VERSION ""

NS_ :

BS_:

BU_: ACM APIM APIM_CDC APIM_CIM APIM_CISM ARM DSP ESPM FCIMB GENERIC GWM HUD_ADV IPC MRCMB_RDAPM_HS3 RACM_RCIM TRM_ITRM TSTR WCM WCMB WCMC

BO_ 726 ACU_Send_Signals_8: 8 APIM_CIM
 SG_ ACU_SelectedPTYCodes_St : 4|29@0+ (1,0) [0|536870911] "unitless"  APIM,APIM_CDC,GWM
 SG_ ACU_AFJump_St : 51|2@0+ (1,0) [0|3] "SED"  APIM,APIM_CDC,GWM
 SG_ ACU_TAMode_St : 53|2@0+ (1,0) [0|3] "SED"  APIM,APIM_CDC,GWM,IPC
 SG_ ACU_NEWSMode_St : 55|2@0+ (1,0) [0|3] "SED"  APIM,APIM_CDC,GWM,IPC

BO_ 727 ACU_Send_Signals_2: 8 ACM
 SG_ ACU_LoadEjectDisc_St : 2|3@0+ (1,0) [0|7] "SED"  APIM,APIM_CDC,GWM
 SG_ ACU_LoadEjectMode_St : 7|4@0+ (1,0) [0|15] "SED"  APIM,APIM_CDC,GWM

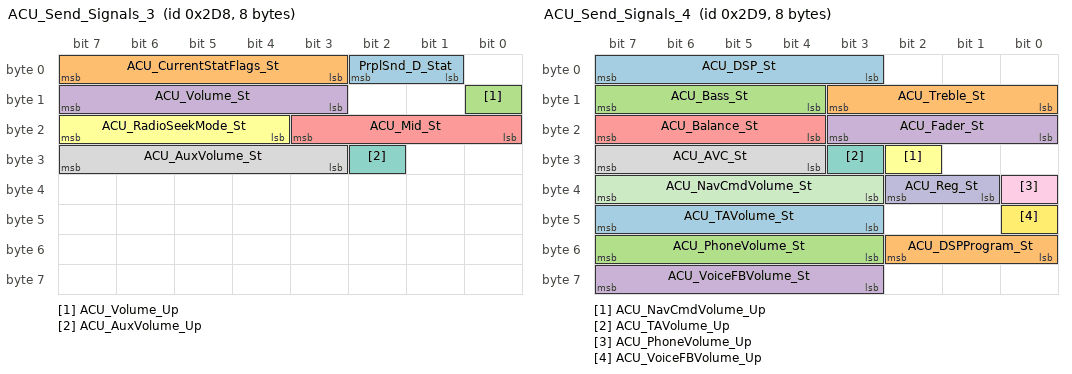
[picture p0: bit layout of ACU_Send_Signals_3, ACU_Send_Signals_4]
BO_ 728 ACU_Send_Signals_3: 8 APIM_CIM
 SG_ PrplSnd_D_Stat : 2|2@0+ (1,0) [0|3] "SED"  APIM,APIM_CDC
 SG_ ACU_CurrentStatFlags_St : 7|5@0+ (1,0) [0|31] "unitless"  APIM,APIM_CDC,GWM,IPC,RACM_RCIM
 SG_ ACU_Volume_Up : 8|1@0+ (1,0) [0|1] "SED"  APIM,APIM_CDC,GWM,IPC,RACM_RCIM
 SG_ ACU_Volume_St : 15|5@0+ (1,0) [0|30] "unitless"  APIM,APIM_CDC,GWM,HUD_ADV,IPC,RACM_RCIM,WCM
 SG_ ACU_Mid_St : 19|4@0+ (1,-7) [-7|8] "unitless"  APIM,APIM_CDC,GWM
 SG_ ACU_RadioSeekMode_St : 23|4@0+ (1,0) [0|15] "SED"  APIM,APIM_CDC,GWM,IPC
 SG_ ACU_AuxVolume_Up : 26|1@0+ (1,0) [0|1] "SED"  APIM_CDC,IPC
 SG_ ACU_AuxVolume_St : 31|5@0+ (1,0) [0|31] "unitless"  APIM_CDC,IPC

BO_ 729 ACU_Send_Signals_4: 8 APIM_CIM
 SG_ ACU_DSP_St : 7|5@0+ (1,0) [0|31] "SED"  APIM,APIM_CDC,GWM
 SG_ ACU_Treble_St : 11|4@0+ (1,-7) [-7|8] "unitless"  APIM,APIM_CDC,GWM,IPC
 SG_ ACU_Bass_St : 15|4@0+ (1,-7) [-7|1] "unitless"  APIM,APIM_CDC
 SG_ ACU_Fader_St : 19|4@0+ (1,-7) [-7|8] "unitless"  APIM,APIM_CDC,GWM,IPC
 SG_ ACU_Balance_St : 23|4@0+ (1,-7) [-7|1] "unitless"  APIM,APIM_CDC
 SG_ ACU_NavCmdVolume_Up : 26|1@0+ (1,0) [0|1] "SED"  APIM,APIM_CDC,GWM,IPC
 SG_ ACU_TAVolume_Up : 27|1@0+ (1,0) [0|1] "SED"  APIM,APIM_CDC,GWM,IPC
 SG_ ACU_AVC_St : 31|4@0+ (1,0) [0|7] "unitless"  APIM,APIM_CDC
 SG_ ACU_PhoneVolume_Up : 32|1@0+ (1,0) [0|1] "SED"  APIM,APIM_CDC,GWM,IPC
 SG_ ACU_Reg_St : 34|2@0+ (1,0) [0|3] "SED"  APIM,APIM_CDC,GWM
 SG_ ACU_NavCmdVolume_St : 39|5@0+ (1,0) [0|30] "SED"  APIM,APIM_CDC,GWM,IPC,WCM
 SG_ ACU_VoiceFBVolume_Up : 40|1@0+ (1,0) [0|1] "SED"  APIM,APIM_CDC,GWM,IPC
 SG_ ACU_TAVolume_St : 47|5@0+ (1,0) [0|30] "SED"  APIM,APIM_CDC,GWM,IPC,WCM
 SG_ ACU_DSPProgram_St : 50|3@0+ (1,0) [0|7] "SED"  APIM,APIM_CDC,GWM
 SG_ ACU_PhoneVolume_St : 55|5@0+ (1,0) [0|30] "SED"  APIM,APIM_CDC,GWM,IPC,WCM
 SG_ ACU_VoiceFBVolume_St : 63|5@0+ (1,0) [0|30] "unitless"  APIM,APIM_CDC,GWM,IPC,WCM

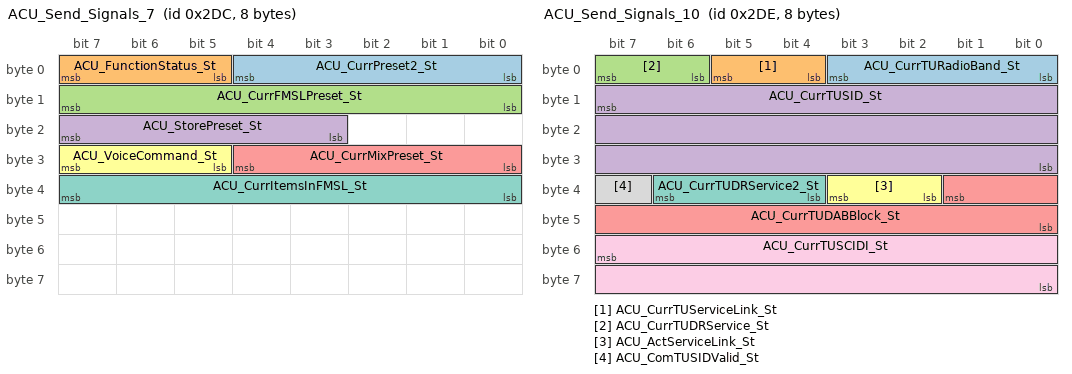
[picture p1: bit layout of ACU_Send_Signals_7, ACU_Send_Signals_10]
BO_ 732 ACU_Send_Signals_7: 8 APIM_CIM
 SG_ ACU_CurrPreset2_St : 4|5@0+ (1,0) [0|31] "unitless"  APIM,APIM_CDC,GWM,IPC,RACM_RCIM
 SG_ ACU_FunctionStatus_St : 7|3@0+ (1,0) [0|7] "SED"  APIM,APIM_CDC,IPC,RACM_RCIM
 SG_ ACU_CurrFMSLPreset_St : 15|8@0+ (1,0) [0|255] "unitless"  APIM,APIM_CDC,GWM
 SG_ ACU_StorePreset_St : 23|5@0+ (1,0) [0|31] "SED"  APIM,APIM_CDC,GWM,IPC
 SG_ ACU_CurrMixPreset_St : 28|5@0+ (1,0) [0|31] "unitless"  APIM,APIM_CDC,GWM,IPC,RACM_RCIM
 SG_ ACU_VoiceCommand_St : 31|3@0+ (1,0) [0|7] "SED"  GWM
 SG_ ACU_CurrItemsInFMSL_St : 39|8@0+ (1,0) [0|255] "unitless"  APIM,APIM_CDC

BO_ 734 ACU_Send_Signals_10: 8 APIM_CIM
 SG_ ACU_CurrTURadioBand_St : 3|4@0+ (1,0) [0|15] "SED"  APIM_CDC
 SG_ ACU_CurrTUServiceLink_St : 5|2@0+ (1,0) [0|3] "SED"  APIM,APIM_CDC,GWM,RACM_RCIM
 SG_ ACU_CurrTUDRService_St : 7|2@0+ (1,0) [0|3] "SED"  APIM,APIM_CDC,GWM
 SG_ ACU_CurrTUSID_St : 15|24@0+ (1,0) [0|16777215] "unitless"  APIM,APIM_CDC,GWM,RACM_RCIM
 SG_ ACU_CurrTUDABBlock_St : 33|10@0+ (1,0) [0|1023] "SED"  APIM,APIM_CDC,GWM,IPC,RACM_RCIM
 SG_ ACU_ActServiceLink_St : 35|2@0+ (1,0) [0|3] "SED"  APIM,APIM_CDC,IPC,RACM_RCIM
 SG_ ACU_CurrTUDRService2_St : 38|3@0+ (1,0) [0|7] "SED"  APIM,APIM_CDC,GWM,IPC,RACM_RCIM
 SG_ ACU_ComTUSIDValid_St : 39|1@0+ (1,0) [0|1] "SED"  APIM,APIM_CDC,GWM
 SG_ ACU_CurrTUSCIDI_St : 55|16@0+ (1,0) [0|65535] "unitless"  APIM,APIM_CDC,GWM,RACM_RCIM

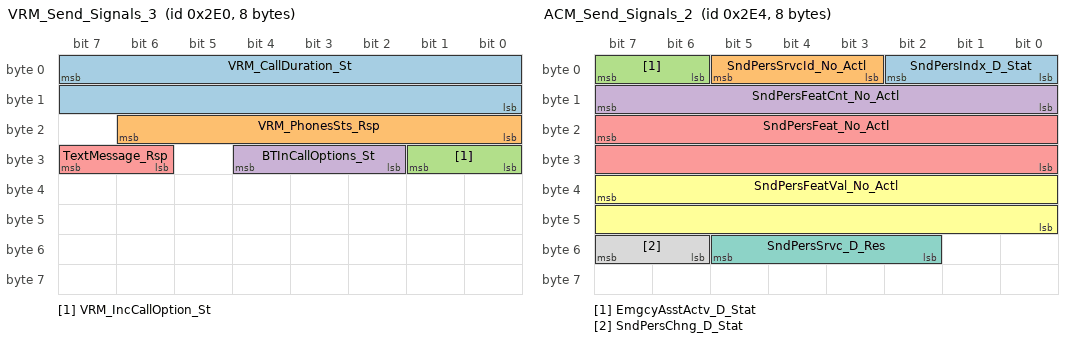
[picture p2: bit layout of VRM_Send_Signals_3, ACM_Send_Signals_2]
BO_ 736 VRM_Send_Signals_3: 8 APIM_CDC
 SG_ VRM_CallDuration_St : 7|16@0+ (1,0) [0|65534] "second"  IPC
 SG_ VRM_PhonesSts_Rsp : 22|7@0+ (1,0) [0|127] "unitless"  GENERIC
 SG_ VRM_IncCallOption_St : 25|2@0+ (1,0) [0|3] "SED"  GENERIC
 SG_ BTInCallOptions_St : 28|3@0+ (1,0) [0|7] "SED"  IPC
 SG_ TextMessage_Rsp : 31|2@0+ (1,0) [0|3] "SED"  IPC

BO_ 737 APIM_ECG_Word_Tx: 8 APIM_CDC
 SG_ APIM_ECG_Word_Tx : 7|64@0+ (1,0) [0|1.84467440737096E+019] "unitless"  GWM,IPC

BO_ 739 HMI_Send_Signals_7: 8 APIM_CDC
 SG_ HMI_HMIMode_St : 2|3@0+ (1,0) [0|7] "SED"  ACM,DSP,GWM,HUD_ADV,IPC,RACM_RCIM,WCM,WCMB,WCMC
 SG_ BptStrtStop_D_RqMnu : 4|2@0+ (1,0) [0|3] "SED"  GWM
 SG_ BptMde_D_RqMnu : 7|3@0+ (1,0) [0|7] "SED"  GWM
 SG_ EngExhMdeHrStrt_D_Rq : 12|5@0+ (1,0) [0|31] "SED"  GWM
 SG_ OnbTrgtSocOvrrd_D_Rq : 14|2@0+ (1,0) [0|3] "SED"  GWM
 SG_ Partial_Amp_Shutdown : 15|1@0+ (1,0) [0|1] "SED"  ACM,GWM
 SG_ SeatOccChime_B_RqCancl : 16|1@0+ (1,0) [0|1] "SED"  GWM
 SG_ EngExhMdeHrEnbl_D_Rq : 18|2@0+ (1,0) [0|3] "SED"  GWM
 SG_ EngExhMdeHrEnd_D_Rq : 23|5@0+ (1,0) [0|31] "SED"  GWM
 SG_ VgfSet_D_Stat : 25|2@0+ (1,0) [0|3] "SED"  GWM
 SG_ VehHornOccAlrt_D_Stat : 27|2@0+ (1,0) [0|3] "SED"  GWM
 SG_ SeatOccRear_D_Stat : 29|2@0+ (1,0) [0|3] "SED"  GWM
 SG_ BabySeatInUse_D_Stat : 31|2@0+ (1,0) [0|3] "SED"  GWM
 SG_ BptMnSoc_L_RqMnu : 39|13@0+ (0.1,0) [0|819.1] "kilometer"  GWM
 SG_ LostPKChirp_D_RqMnu : 42|2@0+ (1,0) [0|3] "SED"  GWM
 SG_ SpeedChngChime_D_Rq : 49|2@0+ (1,0) [0|3] "SED"  GWM
 SG_ BptDly_T_RqMnu : 55|6@0+ (0.5,0) [0|31.5] "minute"  GWM
 SG_ OnbTrgtSocOvrrd_Pc_Rq : 63|7@0+ (1,0) [0|127] "percent"  GWM

BO_ 740 ACM_Send_Signals_2: 8 ACM
 SG_ SndPersIndx_D_Stat : 2|3@0+ (1,0) [0|7] "SED"  GWM
 SG_ SndPersSrvcId_No_Actl : 5|3@0+ (1,0) [0|7] "unitless"  GWM
 SG_ EmgcyAsstActv_D_Stat : 7|2@0+ (1,0) [0|3] "SED"  GWM
 SG_ SndPersFeatCnt_No_Actl : 15|8@0+ (1,0) [0|255] "unitless"  GWM
 SG_ SndPersFeat_No_Actl : 23|16@0+ (1,0) [0|65535] "unitless"  GWM
 SG_ SndPersFeatVal_No_Actl : 39|16@0+ (1,0) [0|65535] "unitless"  GWM
 SG_ SndPersSrvc_D_Res : 53|4@0+ (1,0) [0|15] "SED"  GWM
 SG_ SndPersChng_D_Stat : 55|2@0+ (1,0) [0|3] "SED"  GWM

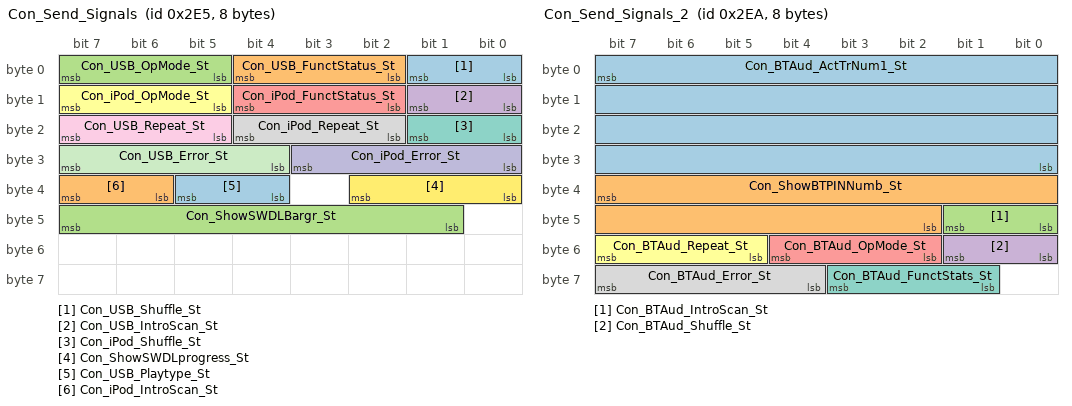
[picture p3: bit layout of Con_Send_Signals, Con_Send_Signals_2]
BO_ 741 Con_Send_Signals: 8 ACM
 SG_ Con_USB_Shuffle_St : 1|2@0+ (1,0) [0|3] "SED"  APIM,APIM_CDC
 SG_ Con_USB_FunctStatus_St : 4|3@0+ (1,0) [0|7] "SED"  APIM,APIM_CDC
 SG_ Con_USB_OpMode_St : 7|3@0+ (1,0) [0|7] "SED"  APIM,APIM_CDC
 SG_ Con_USB_IntroScan_St : 9|2@0+ (1,0) [0|3] "SED"  APIM,APIM_CDC
 SG_ Con_iPod_FunctStatus_St : 12|3@0+ (1,0) [0|7] "SED"  APIM,APIM_CDC
 SG_ Con_iPod_OpMode_St : 15|3@0+ (1,0) [0|7] "SED"  APIM,APIM_CDC
 SG_ Con_iPod_Shuffle_St : 17|2@0+ (1,0) [0|3] "SED"  APIM,APIM_CDC
 SG_ Con_iPod_Repeat_St : 20|3@0+ (1,0) [0|7] "SED"  APIM,APIM_CDC
 SG_ Con_USB_Repeat_St : 23|3@0+ (1,0) [0|7] "SED"  APIM,APIM_CDC
 SG_ Con_iPod_Error_St : 27|4@0+ (1,0) [0|15] "SED"  APIM,APIM_CDC
 SG_ Con_USB_Error_St : 31|4@0+ (1,0) [0|15] "SED"  APIM,APIM_CDC
 SG_ Con_ShowSWDLprogress_St : 34|3@0+ (1,0) [0|7] "SED"  APIM,APIM_CDC
 SG_ Con_USB_Playtype_St : 37|2@0+ (1,0) [0|3] "SED"  APIM,APIM_CDC
 SG_ Con_iPod_IntroScan_St : 39|2@0+ (1,0) [0|3] "SED"  APIM,APIM_CDC
 SG_ Con_ShowSWDLBargr_St : 47|7@0+ (1,0) [0|127] "unitless"  APIM,APIM_CDC

BO_ 744 Con_Send_Signals_3: 8 ACM
 SG_ Con_USB_ActTrNum1_St : 7|32@0+ (1,0) [0|4294967295] "unitless"  IPC
 SG_ Con_USB_NumberOfTracks : 39|16@0+ (1,0) [0|65535] "unitless"  IPC
 SG_ Con_iPod_NumberOfTracks : 55|16@0+ (1,0) [0|65535] "unitless"  IPC

BO_ 745 ECG_APIM_Word_Tx: 8 GWM
 SG_ ECG_APIM_Word_Tx : 7|64@0+ (1,0) [0|1.84467440737096E+019] "unitless"  APIM,APIM_CDC,APIM_CIM,APIM_CISM

BO_ 746 Con_Send_Signals_2: 8 ACM
 SG_ Con_BTAud_ActTrNum1_St : 7|32@0+ (1,0) [0|4294967295] "unitless"  IPC
 SG_ Con_ShowBTPINNumb_St : 39|14@0+ (1,0) [0|16383] "unitless"  IPC
 SG_ Con_BTAud_IntroScan_St : 41|2@0+ (1,0) [0|3] "SED"  IPC
 SG_ Con_BTAud_Shuffle_St : 49|2@0+ (1,0) [0|3] "SED"  IPC
 SG_ Con_BTAud_OpMode_St : 52|3@0+ (1,0) [0|7] "SED"  IPC
 SG_ Con_BTAud_Repeat_St : 55|3@0+ (1,0) [0|7] "SED"  IPC
 SG_ Con_BTAud_FunctStats_St : 59|3@0+ (1,0) [0|7] "SED"  IPC
 SG_ Con_BTAud_Error_St : 63|4@0+ (1,0) [0|15] "SED"  IPC

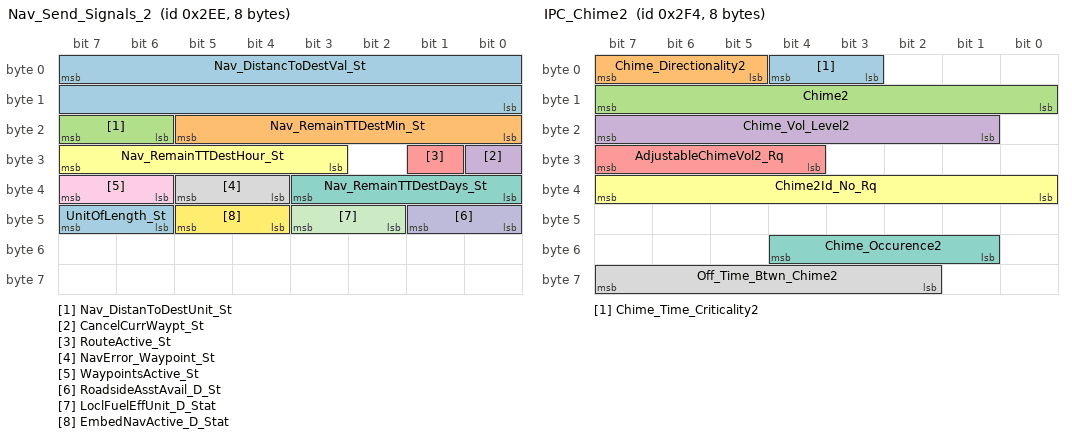
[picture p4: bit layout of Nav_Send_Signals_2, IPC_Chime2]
BO_ 750 Nav_Send_Signals_2: 8 APIM_CDC
 SG_ Nav_DistancToDestVal_St : 7|16@0+ (1,0) [0|65534] "unitless"  GWM,HUD_ADV,IPC
 SG_ Nav_RemainTTDestMin_St : 21|6@0+ (1,0) [0|63] "minute"  GWM,HUD_ADV,IPC
 SG_ Nav_DistanToDestUnit_St : 23|2@0+ (1,0) [0|3] "SED"  GWM,HUD_ADV,IPC
 SG_ CancelCurrWaypt_St : 24|1@0+ (1,0) [0|1] "SED"  GWM,IPC
 SG_ RouteActive_St : 25|1@0+ (1,0) [0|1] "SED"  GWM,HUD_ADV,IPC
 SG_ Nav_RemainTTDestHour_St : 31|5@0+ (1,0) [0|31] "hour"  GWM,HUD_ADV,IPC
 SG_ Nav_RemainTTDestDays_St : 35|4@0+ (1,0) [0|14] "day"  GWM,HUD_ADV,IPC
 SG_ NavError_Waypoint_St : 37|2@0+ (1,0) [0|3] "SED"  GWM,HUD_ADV,IPC
 SG_ WaypointsActive_St : 39|2@0+ (1,0) [0|3] "SED"  GWM,IPC
 SG_ RoadsideAsstAvail_D_St : 41|2@0+ (1,0) [0|3] "SED"  GWM,IPC
 SG_ LoclFuelEffUnit_D_Stat : 43|2@0+ (1,0) [0|3] "SED"  GWM,IPC
 SG_ EmbedNavActive_D_Stat : 45|2@0+ (1,0) [0|3] "SED"  GWM,IPC
 SG_ UnitOfLength_St : 47|2@0+ (1,0) [0|3] "SED"  GWM,IPC

BO_ 753 Vehicle_Stat_Data: 8 APIM_CDC
 SG_ RollCodeValet : 7|16@0+ (1,0) [0|65535] "unitless"  GWM
 SG_ WndwCabnMde_D_Rq : 17|2@0+ (1,0) [0|3] "SED"  GWM
 SG_ HazrdLghtMde_D_Rq : 19|2@0+ (1,0) [0|3] "SED"  GWM
 SG_ DelvrAsstLckMde_D_Rq : 21|2@0+ (1,0) [0|3] "SED"  GWM
 SG_ DelvrAsstButtn_D_Rq : 23|2@0+ (1,0) [0|3] "SED"  GWM
 SG_ VehOprtMan_B_Rq : 24|1@0+ (1,0) [0|1] "SED"  GWM
 SG_ DrConsoleLckFront_B_Rq : 25|1@0+ (1,0) [0|1] "SED"  GWM
 SG_ OraAutoShutdown_B_Rq : 29|1@0+ (1,0) [0|1] "unitless"  GWM
 SG_ OraZone1_D_Rq : 31|2@0+ (1,0) [0|3] "unitless"  GWM
 SG_ OraZone5_D_Rq : 33|2@0+ (1,0) [0|3] "SED"  GWM
 SG_ OraZone4_D_Rq : 35|2@0+ (1,0) [0|3] "SED"  GWM
 SG_ OraZone2_D_Rq : 37|2@0+ (1,0) [0|3] "SED"  GWM
 SG_ PdlAsyPos_D_RqMnu : 39|2@0+ (1,0) [0|3] "SED"  GWM
 SG_ SelDrvMdeSwtch_D_Stat8 : 42|2@0+ (1,0) [0|3] "SED"  GWM
 SG_ KeylessIdlSrc_D_Rq : 45|3@0+ (1,0) [0|7] "SED"  GWM
 SG_ OraZone6_D_Rq : 47|2@0+ (1,0) [0|3] "SED"  GWM
 SG_ Bec2Oprt_No_RqMnu : 55|3@0+ (1,0) [0|7] "unitless"  GWM

BO_ 754 ACU_Send_Signals_14: 8 APIM_CIM
 SG_ ACU_ActChimeTypeDat_St : 5|14@0+ (1,0) [0|16383] "unitless"  DSP
 SG_ ACU_ActChimeType_St : 23|3@0+ (1,0) [0|7] "SED"  DSP

BO_ 756 IPC_Chime2: 8 APIM_CDC
 SG_ Chime_Time_Criticality2 : 4|2@0+ (1,0) [0|3] "SED"  ACM,APIM_CISM,DSP,GWM
 SG_ Chime_Directionality2 : 7|3@0+ (1,0) [0|7] "SED"  ACM,APIM_CISM,DSP,GWM
 SG_ Chime2 : 15|8@0+ (1,0) [0|255] "unitless"  ACM,APIM_CISM,DSP,GWM
 SG_ Chime_Vol_Level2 : 23|7@0+ (1,0) [0|127] "unitless"  ACM,APIM_CISM,DSP,GWM
 SG_ AdjustableChimeVol2_Rq : 31|4@0+ (1,0) [0|15] "SED"  ACM,APIM_CISM,DSP,GWM
 SG_ Chime2Id_No_Rq : 39|8@0+ (1,0) [0|255] "SED"  ACM,APIM_CISM,DSP
 SG_ Chime_Occurence2 : 52|4@0+ (1,0) [0|15] "SED"  ACM,APIM_CISM,DSP,GWM
 SG_ Off_Time_Btwn_Chime2 : 63|6@0+ (1,0) [0|52] "unitless"  ACM,APIM_CISM,DSP,GWM

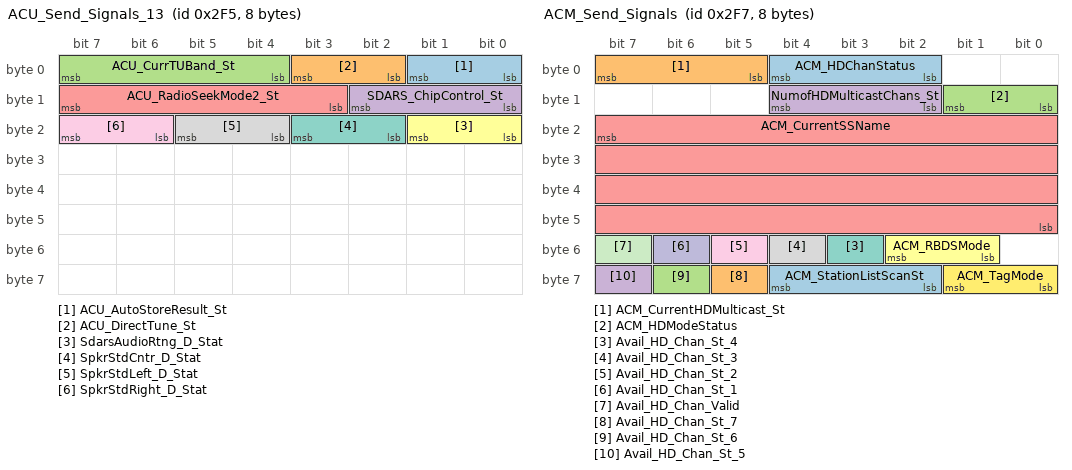
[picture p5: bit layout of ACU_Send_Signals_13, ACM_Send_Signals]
BO_ 757 ACU_Send_Signals_13: 8 APIM_CIM
 SG_ ACU_AutoStoreResult_St : 1|2@0+ (1,0) [0|3] "SED"  APIM,APIM_CDC,GWM,IPC,RACM_RCIM
 SG_ ACU_DirectTune_St : 3|2@0+ (1,0) [0|3] "SED"  APIM,APIM_CDC,GWM,IPC
 SG_ ACU_CurrTUBand_St : 7|4@0+ (1,0) [0|15] "SED"  APIM,APIM_CDC,DSP,GWM,IPC,RACM_RCIM,WCM,WCMB,WCMC
 SG_ SDARS_ChipControl_St : 10|3@0+ (1,0) [0|7] "SED"  APIM,APIM_CDC
 SG_ ACU_RadioSeekMode2_St : 15|5@0+ (1,0) [0|31] "SED"  APIM,APIM_CDC,GWM,IPC,RACM_RCIM,WCM,WCMB,WCMC
 SG_ SdarsAudioRtng_D_Stat : 17|2@0+ (1,0) [0|3] "SED"  APIM,APIM_CDC
 SG_ SpkrStdCntr_D_Stat : 19|2@0+ (1,0) [0|3] "SED"  DSP,GWM
 SG_ SpkrStdLeft_D_Stat : 21|2@0+ (1,0) [0|3] "SED"  DSP,GWM
 SG_ SpkrStdRight_D_Stat : 23|2@0+ (1,0) [0|3] "SED"  DSP,GWM

BO_ 758 SDARS_Status_Msg_1: 8 APIM_CISM
 SG_ SDARS_OpMode_St : 5|3@0+ (1,0) [0|7] "SED"  APIM,APIM_CDC,IPC
 SG_ SDARS_Factory_Reset_St : 7|2@0+ (1,0) [0|3] "SED"  APIM,APIM_CDC,IPC
 SG_ SDARS_GCI_Update_Prg_St : 23|8@0+ (1,0) [0|255] "unitless"  APIM,APIM_CDC,IPC,RACM_RCIM
 SG_ SDARS_SetCategory_St : 31|8@0+ (1,0) [0|255] "unitless"  APIM,APIM_CDC,IPC

BO_ 759 ACM_Send_Signals: 8 APIM_CIM
 SG_ ACM_HDChanStatus : 4|3@0+ (1,0) [0|7] "SED"  APIM,APIM_CDC,DSP,IPC,RACM_RCIM
 SG_ ACM_CurrentHDMulticast_St : 7|3@0+ (1,0) [0|7] "SED"  APIM,APIM_CDC,IPC,RACM_RCIM
 SG_ ACM_HDModeStatus : 9|2@0+ (1,0) [0|3] "SED"  APIM,APIM_CDC,IPC,RACM_RCIM
 SG_ NumofHDMulticastChans_St : 12|3@0+ (1,0) [0|7] "SED"  APIM,APIM_CDC,IPC,RACM_RCIM
 SG_ ACM_CurrentSSName : 23|32@0+ (1,0) [0|4294967295] "unitless"  APIM,APIM_CDC,IPC,RACM_RCIM
 SG_ ACM_RBDSMode : 50|2@0+ (1,0) [0|3] "SED"  APIM,APIM_CDC,IPC,RACM_RCIM
 SG_ Avail_HD_Chan_St_4 : 51|1@0+ (1,0) [0|1] "SED"  APIM,APIM_CDC,RACM_RCIM
 SG_ Avail_HD_Chan_St_3 : 52|1@0+ (1,0) [0|1] "SED"  APIM,APIM_CDC,RACM_RCIM
 SG_ Avail_HD_Chan_St_2 : 53|1@0+ (1,0) [0|1] "SED"  APIM,APIM_CDC,RACM_RCIM
 SG_ Avail_HD_Chan_St_1 : 54|1@0+ (1,0) [0|1] "SED"  APIM,APIM_CDC,RACM_RCIM
 SG_ Avail_HD_Chan_Valid : 55|1@0+ (1,0) [0|1] "SED"  APIM,APIM_CDC,RACM_RCIM
 SG_ ACM_TagMode : 57|2@0+ (1,0) [0|3] "SED"  APIM,APIM_CDC,IPC
 SG_ ACM_StationListScanSt : 60|3@0+ (1,0) [0|7] "SED"  APIM,APIM_CDC,IPC
 SG_ Avail_HD_Chan_St_7 : 61|1@0+ (1,0) [0|1] "SED"  APIM,APIM_CDC,RACM_RCIM
 SG_ Avail_HD_Chan_St_6 : 62|1@0+ (1,0) [0|1] "SED"  APIM,APIM_CDC,RACM_RCIM
 SG_ Avail_HD_Chan_St_5 : 63|1@0+ (1,0) [0|1] "SED"  APIM,APIM_CDC,RACM_RCIM

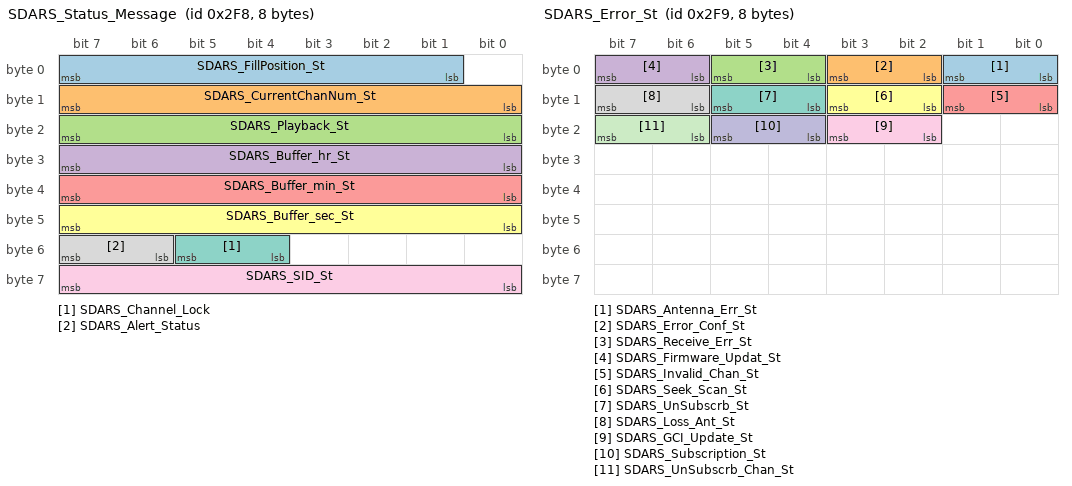
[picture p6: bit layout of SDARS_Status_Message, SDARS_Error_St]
BO_ 760 SDARS_Status_Message: 8 APIM_CISM
 SG_ SDARS_FillPosition_St : 7|7@0+ (1,0) [0|127] "unitless"  APIM,APIM_CDC,IPC
 SG_ SDARS_CurrentChanNum_St : 15|8@0+ (1,0) [0|255] "unitless"  APIM,APIM_CDC,IPC,RACM_RCIM
 SG_ SDARS_Playback_St : 23|8@0+ (1,0) [0|255] "unitless"  APIM,APIM_CDC,IPC
 SG_ SDARS_Buffer_hr_St : 31|8@0+ (1,0) [0|255] "unitless"  APIM,APIM_CDC,IPC
 SG_ SDARS_Buffer_min_St : 39|8@0+ (1,0) [0|255] "unitless"  APIM,APIM_CDC,IPC
 SG_ SDARS_Buffer_sec_St : 47|8@0+ (1,0) [0|255] "unitless"  APIM,APIM_CDC,IPC
 SG_ SDARS_Channel_Lock : 53|2@0+ (1,0) [0|3] "SED"  APIM,APIM_CDC,IPC,RACM_RCIM
 SG_ SDARS_Alert_Status : 55|2@0+ (1,0) [0|3] "SED"  APIM,APIM_CDC,IPC
 SG_ SDARS_SID_St : 63|8@0+ (1,0) [0|255] "unitless"  APIM,APIM_CDC,RACM_RCIM

BO_ 761 SDARS_Error_St: 8 ACM
 SG_ SDARS_Antenna_Err_St : 1|2@0+ (1,0) [0|3] "SED"  APIM,APIM_CDC,IPC,RACM_RCIM
 SG_ SDARS_Error_Conf_St : 3|2@0+ (1,0) [0|3] "SED"  APIM,APIM_CDC,IPC,RACM_RCIM
 SG_ SDARS_Receive_Err_St : 5|2@0+ (1,0) [0|3] "SED"  APIM,APIM_CDC,IPC,RACM_RCIM
 SG_ SDARS_Firmware_Updat_St : 7|2@0+ (1,0) [0|3] "SED"  APIM,APIM_CDC,IPC,RACM_RCIM
 SG_ SDARS_Invalid_Chan_St : 9|2@0+ (1,0) [0|3] "SED"  APIM,APIM_CDC,IPC,RACM_RCIM
 SG_ SDARS_Seek_Scan_St : 11|2@0+ (1,0) [0|3] "SED"  APIM,APIM_CDC,IPC,RACM_RCIM
 SG_ SDARS_UnSubscrb_St : 13|2@0+ (1,0) [0|3] "SED"  APIM,APIM_CDC,IPC,RACM_RCIM
 SG_ SDARS_Loss_Ant_St : 15|2@0+ (1,0) [0|3] "SED"  APIM,APIM_CDC,IPC,RACM_RCIM
 SG_ SDARS_GCI_Update_St : 19|2@0+ (1,0) [0|3] "SED"  APIM,APIM_CDC,IPC,RACM_RCIM
 SG_ SDARS_Subscription_St : 21|2@0+ (1,0) [0|3] "SED"  APIM,APIM_CDC,IPC,RACM_RCIM
 SG_ SDARS_UnSubscrb_Chan_St : 23|2@0+ (1,0) [0|3] "SED"  APIM,APIM_CDC,IPC,RACM_RCIM

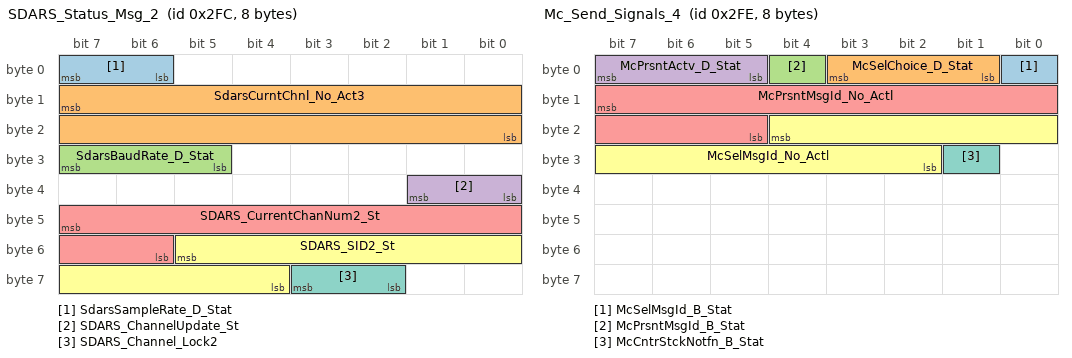
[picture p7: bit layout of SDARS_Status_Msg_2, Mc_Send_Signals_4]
BO_ 764 SDARS_Status_Msg_2: 8 APIM_CDC
 SG_ SdarsSampleRate_D_Stat : 7|2@0+ (1,0) [0|3] "SED"  ACM
 SG_ SdarsCurntChnl_No_Act3 : 15|16@0+ (1,0) [0|65535] "unitless"  ACM,RACM_RCIM
 SG_ SdarsBaudRate_D_Stat : 31|3@0+ (1,0) [0|7] "SED"  ACM
 SG_ SDARS_ChannelUpdate_St : 33|2@0+ (1,0) [0|3] "SED"  ACM
 SG_ SDARS_CurrentChanNum2_St : 47|10@0+ (1,0) [0|1023] "unitless"  ACM,IPC,RACM_RCIM
 SG_ SDARS_SID2_St : 53|10@0+ (1,0) [0|1023] "unitless"  ACM,RACM_RCIM
 SG_ SDARS_Channel_Lock2 : 59|2@0+ (1,0) [0|3] "SED"  ACM,IPC,RACM_RCIM

BO_ 765 Mc_Send_Signals_2: 8 APIM_CDC
 SG_ Mc_VehTimeFrmtUsrSel_St : 1|2@0+ (1,0) [0|3] "SED"  APIM,APIM_CISM,GWM,HUD_ADV,RACM_RCIM
 SG_ Mc_VehLangUsrSel_St : 7|6@0+ (1,0) [0|63] "SED"  ACM,APIM,APIM_CISM,GWM,HUD_ADV
 SG_ Mc_VehThemeUsrSel_St : 11|4@0+ (1,0) [0|15] "SED"  APIM,APIM_CISM,GENERIC,GWM
 SG_ Mc_VehDayNightUsrSel_St : 14|3@0+ (1,0) [0|7] "SED"  ACM,APIM,APIM_CISM,GWM
 SG_ EsaOn_B_Rq : 15|1@0+ (1,0) [0|1] "SED"  GWM
 SG_ EngExhMdeQuiet_D_Rq : 17|2@0+ (1,0) [0|3] "SED"  GWM
 SG_ BrkLineLck_D_Rq : 19|2@0+ (1,0) [0|3] "SED"  GWM
 SG_ Running_Board_Cmd : 21|2@0+ (1,0) [0|3] "SED"  GWM
 SG_ Mc_VehUnitTempUsrSel_St : 22|1@0+ (1,0) [0|1] "SED"  APIM,APIM_CISM,GWM,HUD_ADV,RACM_RCIM
 SG_ Mc_VehUntTrpCoUsrSel_St : 23|1@0+ (1,0) [0|1] "SED"  APIM,APIM_CISM,GWM,HUD_ADV
 SG_ RearDiffLck_D_RqArb : 25|2@0+ (1,0) [0|3] "SED"  GWM
 SG_ BttOn_B_Rq : 26|1@0+ (1,0) [0|1] "SED"  GWM
 SG_ AwdRnge_D_ActlIpc : 29|3@0+ (1,0) [0|7] "SED"  GWM
 SG_ AirSusp_D_RqDrv : 31|2@0+ (1,0) [0|3] "SED"  GWM
 SG_ DrvInputRequired_B_Rq : 32|1@0+ (1,0) [0|1] "SED"  GWM
 SG_ Btt_L_Actl : 39|7@0+ (0.1,0) [0|12.7] "meter"  GWM
 SG_ SelDrvMdeTxtReset_B_Rq : 40|1@0+ (1,0) [0|1] "SED"  GWM
 SG_ SelDrvMdeDsply_B_Avail : 41|1@0+ (1,0) [0|1] "SED"  GWM
 SG_ AwdDrvMde_D_Rq : 44|3@0+ (1,0) [0|7] "SED"  GWM
 SG_ AwdMde_D_RqArb : 47|3@0+ (1,0) [0|7] "SED"  GWM
 SG_ EdmSailMde_B_RqDrv : 48|1@0+ (1,0) [0|1] "SED"  GWM
 SG_ WaitToStartLamp_D_Falt : 50|2@0+ (1,0) [0|3] "SED"  GWM
 SG_ AutoTowAllw_D_RqMnu : 52|2@0+ (1,0) [0|3] "SED"  GWM
 SG_ EngExhMdeQuiet_D2_Rq : 55|3@0+ (1,0) [0|7] "SED"  GWM
 SG_ BalrSwtch_D_Stat : 57|2@0+ (1,0) [0|3] "SED"  GWM
 SG_ BalrMde_D_Rq : 59|2@0+ (1,0) [0|3] "SED"  GWM
 SG_ RstrnOnPsngr_D_RqMnu : 63|4@0+ (1,0) [0|15] "SED"  GWM

BO_ 766 Mc_Send_Signals_4: 8 APIM_CISM
 SG_ McSelMsgId_B_Stat : 0|1@0+ (1,0) [0|1] "SED"  IPC
 SG_ McSelChoice_D_Stat : 3|3@0+ (1,0) [0|7] "SED"  IPC
 SG_ McPrsntMsgId_B_Stat : 4|1@0+ (1,0) [0|1] "SED"  IPC
 SG_ McPrsntActv_D_Stat : 7|3@0+ (1,0) [0|7] "SED"  IPC
 SG_ McPrsntMsgId_No_Actl : 15|11@0+ (1,0) [0|2047] "unitless"  IPC
 SG_ McSelMsgId_No_Actl : 20|11@0+ (1,0) [0|2047] "unitless"  IPC
 SG_ McCntrStckNotfn_B_Stat : 25|1@0+ (1,0) [0|1] "SED"  IPC

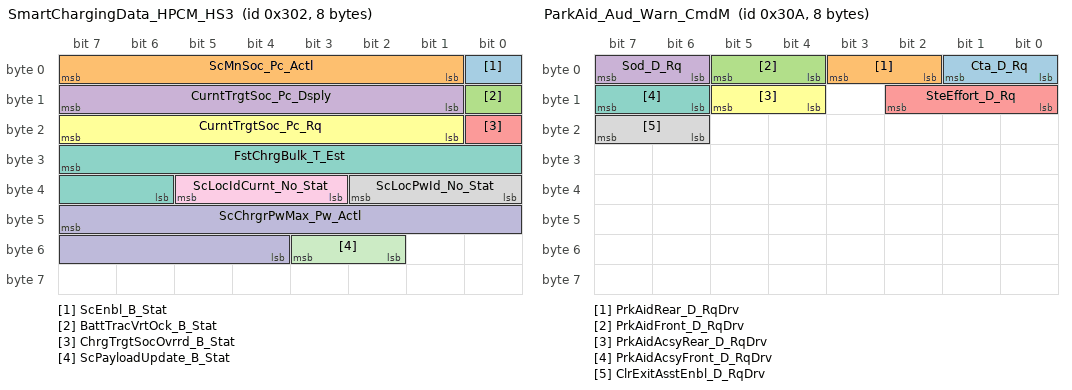
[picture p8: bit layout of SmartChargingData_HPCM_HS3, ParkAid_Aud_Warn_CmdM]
BO_ 770 SmartChargingData_HPCM_HS3: 8 GWM
 SG_ ScEnbl_B_Stat : 0|1@0+ (1,0) [0|1] "SED"  APIM,APIM_CDC,APIM_CIM,APIM_CISM
 SG_ ScMnSoc_Pc_Actl : 7|7@0+ (1,0) [0|127] "percent"  APIM,APIM_CDC,APIM_CIM,APIM_CISM
 SG_ BattTracVrtOck_B_Stat : 8|1@0+ (1,0) [0|1] "SED" Vector__XXX
 SG_ CurntTrgtSoc_Pc_Dsply : 15|7@0+ (1,0) [0|127] "percent"  APIM,APIM_CDC,APIM_CIM,APIM_CISM,IPC
 SG_ ChrgTrgtSocOvrrd_B_Stat : 16|1@0+ (1,0) [0|1] "SED"  APIM,APIM_CDC,APIM_CIM,APIM_CISM
 SG_ CurntTrgtSoc_Pc_Rq : 23|7@0+ (1,0) [0|127] "percent"  GENERIC
 SG_ FstChrgBulk_T_Est : 31|10@0+ (1,0) [0|1023] "minute"  APIM,APIM_CDC,APIM_CIM,APIM_CISM,IPC
 SG_ ScLocPwId_No_Stat : 34|3@0+ (1,0) [0|7] "unitless"  GENERIC
 SG_ ScLocIdCurnt_No_Stat : 37|3@0+ (1,0) [0|7] "unitless"  APIM,APIM_CDC,APIM_CIM,APIM_CISM
 SG_ ScChrgrPwMax_Pw_Actl : 47|12@0+ (50,0) [0|204750] "watts"  GENERIC
 SG_ ScPayloadUpdate_B_Stat : 51|2@0+ (1,0) [0|3] "SED"  GENERIC

BO_ 772 Driver_Seat_Info_2_HS3: 8 GWM
 SG_ Memory_Feedback_Rqst : 0|1@0+ (1,0) [0|1] "SED"  APIM_CDC,APIM_CIM,IPC
 SG_ Cancel_Auto_Movement : 1|1@0+ (1,0) [0|1] "SED"  APIM_CIM,APIM_CISM
 SG_ MemDrvDeny_B_Stat : 2|1@0+ (1,0) [0|1] "SED"  APIM_CDC,APIM_CIM,IPC
 SG_ Easy_Entry_Rqst : 4|2@0+ (1,0) [0|3] "SED" Vector__XXX
 SG_ SeatSlprPosMsgTxt_B_Rq : 5|1@0+ (1,0) [0|1] "SED"  APIM_CDC,APIM_CIM,IPC
 SG_ PwRnngBoardSwtch_D_Stat : 7|2@0+ (1,0) [0|3] "SED"  APIM,APIM_CDC,APIM_CIM,APIM_CISM,IPC
 SG_ SeatScrnDrvOn_B_Rq : 8|1@0+ (1,0) [0|1] "SED"  APIM,APIM_CDC,APIM_CIM,APIM_CISM
 SG_ SeatPos_D_Stat : 11|3@0+ (1,0) [0|7] "SED" Vector__XXX
 SG_ Memory_Cmd : 15|4@0+ (1,0) [0|15] "SED"  APIM_CDC,APIM_CIM,HUD_ADV,IPC
 SG_ SeatPosSavDrv_B_Stat : 16|1@0+ (1,0) [0|1] "SED"  APIM,APIM_CDC,APIM_CIM
 SG_ SeatRelxPosDact_B_Stat : 17|1@0+ (1,0) [0|1] "SED"  APIM,APIM_CDC,APIM_CIM,APIM_CISM
 SG_ SeatRelxPosActv_B_Stat : 18|1@0+ (1,0) [0|1] "SED"  APIM,APIM_CDC,APIM_CIM,APIM_CISM
 SG_ SeatRelxPosSet_B_Stat : 19|1@0+ (1,0) [0|1] "SED"  APIM,APIM_CDC,APIM_CIM,APIM_CISM
 SG_ SeatSlprPosPsngr_D_Stat : 21|2@0+ (1,0) [0|3] "SED" Vector__XXX
 SG_ PwRnngBoardT_D_Stat : 23|2@0+ (1,0) [0|3] "SED"  APIM,APIM_CDC,APIM_CIM,APIM_CISM,IPC
 SG_ SteClmnPosDrvMde_D_St : 25|2@0+ (1,0) [0|3] "SED" Vector__XXX
 SG_ SteClmnPosSav_D_St : 27|2@0+ (1,0) [0|3] "SED" Vector__XXX
 SG_ SeatMovDrv_D_Stat : 31|4@0+ (1,0) [0|15] "SED" Vector__XXX
 SG_ SeatMemPosDrv_D_Stat : 39|5@0+ (1,0) [0|31] "SED" Vector__XXX

BO_ 773 PassengerSeat_Data_HS3: 8 GWM
 SG_ SeatBckInclnPsng_B_St : 0|1@0+ (1,0) [0|1] "SED" Vector__XXX
 SG_ StmsScrnPsngrOn_B_Rq : 1|1@0+ (1,0) [0|1] "SED"  APIM,APIM_CDC,APIM_CIM,APIM_CISM
 SG_ SeatPsngrMem_D_Cmd : 5|4@0+ (1,0) [0|15] "SED"  APIM_CDC,APIM_CIM
 SG_ SeatScrnPsngrOn_B_Rq : 6|1@0+ (1,0) [0|1] "SED"  APIM,APIM_CDC,APIM_CIM,APIM_CISM
 SG_ MemSwtchPsngrFdbck_B_Rq : 7|1@0+ (1,0) [0|1] "SED"  APIM,APIM_CDC,APIM_CIM,IPC
 SG_ SeatBckInclTopPsn_B_St : 8|1@0+ (1,0) [0|1] "SED" Vector__XXX
 SG_ SeatMovDrv_D_Rq : 11|3@0+ (1,0) [0|7] "SED" Vector__XXX
 SG_ SeatMovMdeSel_D_Rq : 13|2@0+ (1,0) [0|3] "SED" Vector__XXX
 SG_ SeatAutoSavPsngr_D_St : 15|2@0+ (1,0) [0|3] "SED"  APIM_CDC,APIM_CIM
 SG_ PersStorePsngr_D_Stat : 17|2@0+ (1,0) [0|3] "SED"  APIM_CDC,APIM_CIM
 SG_ StwblStewMde_D_Dsply : 19|2@0+ (1,0) [0|3] "SED"  APIM,APIM_CDC,APIM_CIM
 SG_ StwblStewMde_D_Stat : 23|4@0+ (1,0) [0|15] "SED"  APIM,APIM_CDC,APIM_CIM,GWM
 SG_ SeatLmbrExtnPsngr_B_St : 24|1@0+ (1,0) [0|1] "SED" Vector__XXX
 SG_ SeatHghtRearPsng_B_St : 25|1@0+ (1,0) [0|1] "SED" Vector__XXX
 SG_ SeatHghtFrontPsng_B_St : 26|1@0+ (1,0) [0|1] "SED" Vector__XXX
 SG_ SeatHeadrstTltPsn_B_St : 27|1@0+ (1,0) [0|1] "SED" Vector__XXX
 SG_ SeatMovPsngr_D_Res : 31|4@0+ (1,0) [0|15] "SED" Vector__XXX
 SG_ SeatHeadrstHgtPsn_B_St : 32|1@0+ (1,0) [0|1] "SED" Vector__XXX
 SG_ SeatMovIdPsngr_No_Actl : 35|3@0+ (1,0) [0|7] "unitless" Vector__XXX
 SG_ SeatThghRExtnPsng_B_St : 36|1@0+ (1,0) [0|1] "SED" Vector__XXX
 SG_ SeatThghLExtnPsng_B_St : 37|1@0+ (1,0) [0|1] "SED" Vector__XXX
 SG_ SeatSlidPosPsngr_B_St : 38|1@0+ (1,0) [0|1] "SED" Vector__XXX
 SG_ SeatLmbrHghtPsngr_B_St : 39|1@0+ (1,0) [0|1] "SED" Vector__XXX
 SG_ PersRecallPsng_D_Actl : 45|2@0+ (1,0) [0|3] "SED"  APIM_CDC,APIM_CIM
 SG_ SeatMovSrvcPsngr_D_Arb : 47|2@0+ (1,0) [0|3] "SED" Vector__XXX

BO_ 778 ParkAid_Aud_Warn_CmdM: 8 APIM_CDC
 SG_ Cta_D_Rq : 1|2@0+ (1,0) [0|3] "SED"  GWM
 SG_ PrkAidRear_D_RqDrv : 3|2@0+ (1,0) [0|3] "SED"  GWM
 SG_ PrkAidFront_D_RqDrv : 5|2@0+ (1,0) [0|3] "SED"  GWM
 SG_ Sod_D_Rq : 7|2@0+ (1,0) [0|3] "SED"  GWM
 SG_ SteEffort_D_Rq : 10|3@0+ (1,0) [0|7] "SED"  GWM
 SG_ PrkAidAcsyRear_D_RqDrv : 13|2@0+ (1,0) [0|3] "SED"  GWM
 SG_ PrkAidAcsyFront_D_RqDrv : 15|2@0+ (1,0) [0|3] "SED"  GWM
 SG_ ClrExitAsstEnbl_D_RqDrv : 23|2@0+ (1,0) [0|3] "SED"  GWM

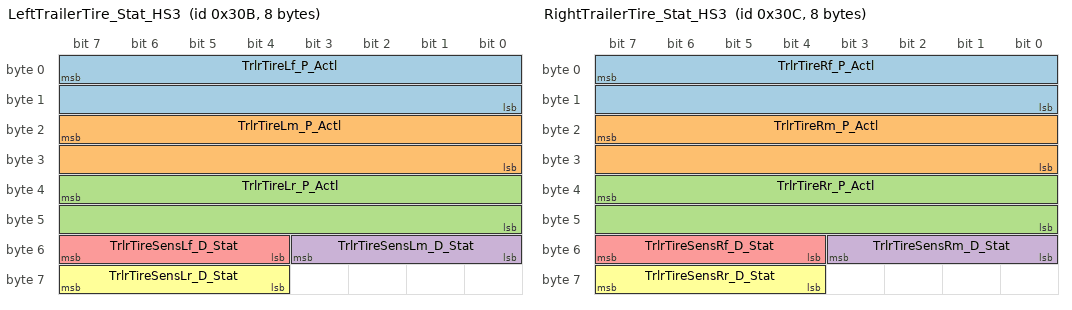
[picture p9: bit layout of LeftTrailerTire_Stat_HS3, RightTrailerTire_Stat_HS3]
BO_ 779 LeftTrailerTire_Stat_HS3: 8 GWM
 SG_ TrlrTireLf_P_Actl : 7|16@0+ (1,0) [0|65535] "kilopascal"  APIM_CDC,APIM_CIM,APIM_CISM,IPC
 SG_ TrlrTireLm_P_Actl : 23|16@0+ (1,0) [0|65535] "kilopascal"  APIM_CDC,APIM_CIM,APIM_CISM,IPC
 SG_ TrlrTireLr_P_Actl : 39|16@0+ (1,0) [0|65535] "kilopascal"  APIM_CDC,APIM_CIM,APIM_CISM,IPC
 SG_ TrlrTireSensLm_D_Stat : 51|4@0+ (1,0) [0|15] "SED"  APIM_CDC,APIM_CIM,APIM_CISM,IPC
 SG_ TrlrTireSensLf_D_Stat : 55|4@0+ (1,0) [0|15] "SED"  APIM_CDC,APIM_CIM,APIM_CISM,IPC
 SG_ TrlrTireSensLr_D_Stat : 63|4@0+ (1,0) [0|15] "SED"  APIM_CDC,APIM_CIM,APIM_CISM,IPC

BO_ 780 RightTrailerTire_Stat_HS3: 8 GWM
 SG_ TrlrTireRf_P_Actl : 7|16@0+ (1,0) [0|65535] "kilopascal"  APIM_CDC,APIM_CIM,IPC
 SG_ TrlrTireRm_P_Actl : 23|16@0+ (1,0) [0|65535] "kilopascal"  APIM_CDC,APIM_CIM,IPC
 SG_ TrlrTireRr_P_Actl : 39|16@0+ (1,0) [0|65535] "kilopascal"  APIM_CDC,APIM_CIM,IPC
 SG_ TrlrTireSensRm_D_Stat : 51|4@0+ (1,0) [0|15] "SED"  APIM_CDC,APIM_CIM,IPC
 SG_ TrlrTireSensRf_D_Stat : 55|4@0+ (1,0) [0|15] "SED"  APIM_CDC,APIM_CIM,IPC
 SG_ TrlrTireSensRr_D_Stat : 63|4@0+ (1,0) [0|15] "SED"  APIM_CDC,APIM_CIM,IPC

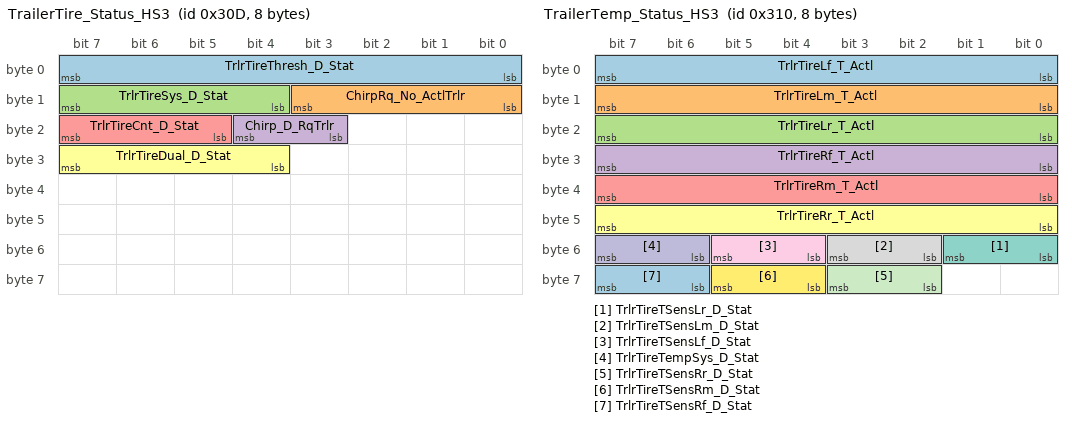
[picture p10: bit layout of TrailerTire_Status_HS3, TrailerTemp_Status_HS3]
BO_ 781 TrailerTire_Status_HS3: 8 GWM
 SG_ TrlrTireThresh_D_Stat : 7|8@0+ (1,0) [0|255] "unitless"  APIM,APIM_CDC,APIM_CIM,APIM_CISM,IPC
 SG_ ChirpRq_No_ActlTrlr : 11|4@0+ (1,0) [0|15] "unitless"  APIM_CIM,APIM_CISM,IPC
 SG_ TrlrTireSys_D_Stat : 15|4@0+ (1,0) [0|15] "SED"  APIM,APIM_CDC,APIM_CIM,APIM_CISM,IPC
 SG_ Chirp_D_RqTrlr : 20|2@0+ (1,0) [0|3] "SED"  APIM_CIM,APIM_CISM,IPC
 SG_ TrlrTireCnt_D_Stat : 23|3@0+ (1,0) [0|7] "SED"  APIM,APIM_CDC,APIM_CIM,APIM_CISM,IPC
 SG_ TrlrTireDual_D_Stat : 31|4@0+ (1,0) [0|15] "SED"  APIM,APIM_CDC,APIM_CIM,APIM_CISM,IPC

BO_ 783 Cluster_TireData: 8 APIM_CDC
 SG_ TrlrTireThresh_D_RqDrv : 7|8@0+ (1,0) [0|255] "unitless"  GWM
 SG_ TrlrLearnMdeOn_B_RqDrv : 12|1@0+ (1,0) [0|1] "SED"  GWM
 SG_ TrlrTireCnt_D_RqDrv : 15|3@0+ (1,0) [0|7] "SED"  GWM

BO_ 784 TrailerTemp_Status_HS3: 8 GWM
 SG_ TrlrTireLf_T_Actl : 7|8@0+ (1,-60) [-60|195] "degC"  APIM_CDC,APIM_CIM,IPC
 SG_ TrlrTireLm_T_Actl : 15|8@0+ (1,-60) [-60|195] "degC"  APIM_CDC,APIM_CIM,IPC
 SG_ TrlrTireLr_T_Actl : 23|8@0+ (1,-60) [-60|195] "degC"  APIM_CDC,APIM_CIM,IPC
 SG_ TrlrTireRf_T_Actl : 31|8@0+ (1,-60) [-60|195] "degC"  APIM_CDC,APIM_CIM,IPC
 SG_ TrlrTireRm_T_Actl : 39|8@0+ (1,-60) [-60|195] "degC"  APIM_CDC,APIM_CIM,IPC
 SG_ TrlrTireRr_T_Actl : 47|8@0+ (1,-60) [-60|195] "degC"  APIM_CDC,APIM_CIM,IPC
 SG_ TrlrTireTSensLr_D_Stat : 49|2@0+ (1,0) [0|3] "SED"  APIM_CDC,APIM_CIM,IPC
 SG_ TrlrTireTSensLm_D_Stat : 51|2@0+ (1,0) [0|3] "SED"  APIM_CDC,APIM_CIM,IPC
 SG_ TrlrTireTSensLf_D_Stat : 53|2@0+ (1,0) [0|3] "SED"  APIM_CDC,APIM_CIM,IPC
 SG_ TrlrTireTempSys_D_Stat : 55|2@0+ (1,0) [0|3] "SED"  APIM_CDC,APIM_CIM,IPC
 SG_ TrlrTireTSensRr_D_Stat : 59|2@0+ (1,0) [0|3] "SED"  APIM_CDC,APIM_CIM,IPC
 SG_ TrlrTireTSensRm_D_Stat : 61|2@0+ (1,0) [0|3] "SED"  APIM_CDC,APIM_CIM,IPC
 SG_ TrlrTireTSensRf_D_Stat : 63|2@0+ (1,0) [0|3] "SED"  APIM_CDC,APIM_CIM,IPC

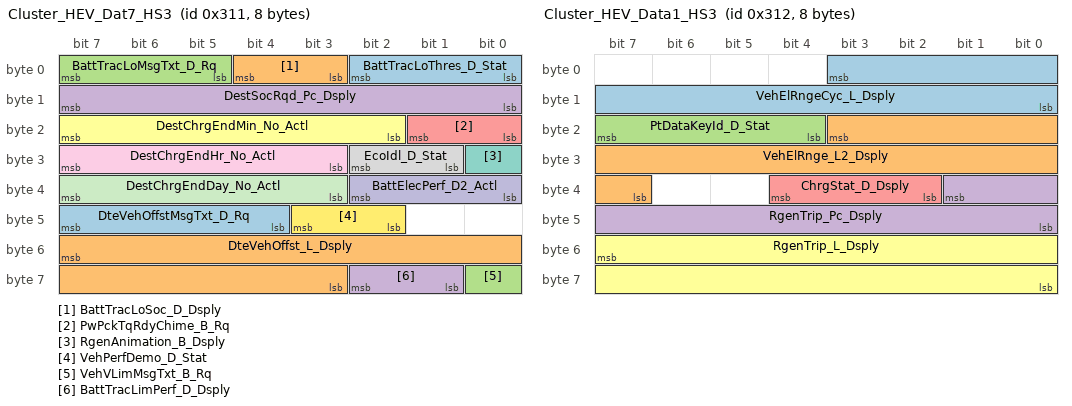
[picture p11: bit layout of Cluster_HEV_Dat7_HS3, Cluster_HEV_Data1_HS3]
BO_ 785 Cluster_HEV_Dat7_HS3: 8 GWM
 SG_ BattTracLoThres_D_Stat : 2|3@0+ (1,0) [0|7] "SED"  APIM,APIM_CDC,APIM_CIM,APIM_CISM,IPC
 SG_ BattTracLoSoc_D_Dsply : 4|2@0+ (1,0) [0|3] "SED"  APIM,APIM_CDC,APIM_CIM,APIM_CISM,IPC
 SG_ BattTracLoMsgTxt_D_Rq : 7|3@0+ (1,0) [0|7] "SED"  APIM,APIM_CDC,APIM_CIM,APIM_CISM,IPC
 SG_ DestSocRqd_Pc_Dsply : 15|8@0+ (0.5,0) [0|127.5] "percent"  APIM,APIM_CDC,APIM_CIM,APIM_CISM,IPC
 SG_ PwPckTqRdyChime_B_Rq : 17|2@0+ (1,0) [0|3] "SED"  APIM_CDC,APIM_CIM,APIM_CISM,IPC
 SG_ DestChrgEndMin_No_Actl : 23|6@0+ (1,0) [0|63] "minute"  APIM,APIM_CDC,APIM_CIM,APIM_CISM,IPC
 SG_ RgenAnimation_B_Dsply : 24|1@0+ (1,0) [0|1] "SED"  APIM_CDC,APIM_CIM,IPC
 SG_ EcoIdl_D_Stat : 26|2@0+ (1,0) [0|3] "SED"  APIM,APIM_CDC,APIM_CIM,APIM_CISM
 SG_ DestChrgEndHr_No_Actl : 31|5@0+ (1,0) [0|31] "Hours"  APIM,APIM_CDC,APIM_CIM,APIM_CISM,IPC
 SG_ BattElecPerf_D2_Actl : 34|3@0+ (1,0) [0|7] "SED"  APIM_CDC,APIM_CIM,IPC
 SG_ DestChrgEndDay_No_Actl : 39|5@0+ (1,0) [1|31] "day"  APIM,APIM_CDC,APIM_CIM,APIM_CISM,IPC
 SG_ VehPerfDemo_D_Stat : 43|2@0+ (1,0) [0|3] "SED"  APIM,APIM_CDC,APIM_CIM,APIM_CISM
 SG_ DteVehOffstMsgTxt_D_Rq : 47|4@0+ (1,0) [0|15] "SED"  APIM,APIM_CDC,APIM_CIM,APIM_CISM,IPC
 SG_ DteVehOffst_L_Dsply : 55|13@0+ (0.1,-400) [-400|419.1] "kilometer"  APIM,APIM_CDC,APIM_CIM,APIM_CISM,IPC
 SG_ VehVLimMsgTxt_B_Rq : 56|1@0+ (1,0) [0|1] "SED"  APIM_CDC,APIM_CIM,IPC
 SG_ BattTracLimPerf_D_Dsply : 58|2@0+ (1,0) [0|3] "SED"  APIM_CDC,APIM_CIM,IPC

BO_ 786 Cluster_HEV_Data1_HS3: 8 GWM
 SG_ VehElRngeCyc_L_Dsply : 3|12@0+ (0.1,0) [0|409.5] "km"  APIM,APIM_CDC,APIM_CIM,APIM_CISM
 SG_ VehElRnge_L2_Dsply : 19|13@0+ (0.1,0) [0|819.1] "kilometer"  APIM,APIM_CDC,APIM_CIM,APIM_CISM,IPC
 SG_ PtDataKeyId_D_Stat : 23|4@0+ (1,0) [0|15] "SED" Vector__XXX
 SG_ RgenTrip_Pc_Dsply : 33|10@0+ (0.1,0) [0|102.3] "percent"  APIM_CDC,APIM_CIM,IPC
 SG_ ChrgStat_D_Dsply : 36|3@0+ (1,0) [0|7] "SED"  APIM,APIM_CDC,APIM_CIM,APIM_CISM,IPC
 SG_ RgenTrip_L_Dsply : 55|16@0+ (0.1,0) [0|6553.5] "kilometer"  APIM_CDC,APIM_CIM,IPC

BO_ 787 Power_Liftgate_Stat_HS3: 8 GWM
 SG_ PwTgateStepMsgTxt_B_Rq : 0|1@0+ (1,0) [0|1] "SED"  APIM,APIM_CDC,APIM_CIM,APIM_CISM,IPC
 SG_ DrTGate_D_Rq : 2|2@0+ (1,0) [0|3] "SED" Vector__XXX
 SG_ Power_Liftgate_Mode_Stt : 4|2@0+ (1,0) [0|3] "SED"  APIM,APIM_CDC,APIM_CIM,APIM_CISM,IPC
 SG_ PwLftgtIntSw_B_Stat : 5|1@0+ (1,0) [0|1] "SED"  APIM,APIM_CDC,APIM_CIM,APIM_CISM
 SG_ PwTgateMsgTxt_B_Rq : 6|1@0+ (1,0) [0|1] "SED"  APIM,APIM_CDC,APIM_CIM,APIM_CISM,IPC
 SG_ PwTgateLamp_B_Rq : 7|1@0+ (1,0) [0|1] "SED"  APIM,APIM_CDC,APIM_CIM,APIM_CISM,IPC
 SG_ PwTgateInhbtMsgTxt_B_Rq : 8|1@0+ (1,0) [0|1] "SED"  APIM_CDC,APIM_CIM,IPC
 SG_ DrLckCnt_No_ActlTgate : 12|4@0+ (1,0) [0|15] "unitless" Vector__XXX
 SG_ DrTgateChime2_D_Rq : 15|3@0+ (1,0) [0|7] "SED"  APIM,APIM_CDC,APIM_CIM,APIM_CISM,IPC
 SG_ DrMatLamp_B_Rq : 16|1@0+ (1,0) [0|1] "SED"  APIM_CDC,IPC
 SG_ DrTgatePos_Pc_Actl : 23|7@0+ (1,0) [0|127] "percent"  APIM_CDC,APIM_CIM
 SG_ DrMatAjarMsgTxt_B_Rq : 24|1@0+ (1,0) [0|1] "SED"  APIM_CDC,IPC
 SG_ LftgtPos_Pc_Actl : 31|7@0+ (1,0) [0|127] "unitless"  APIM_CDC,APIM_CIM
 SG_ DrMatInhbt_B_Rq : 32|1@0+ (1,0) [0|1] "SED" Vector__XXX
 SG_ DrMatInhbtMsgTxt_B_Rq : 33|1@0+ (1,0) [0|1] "SED"  APIM_CDC,IPC
 SG_ BecManCloseMsgTxt_D_Rq : 35|2@0+ (1,0) [0|3] "SED"  APIM_CDC,APIM_CIM
 SG_ BecAjarMsgTxt_D_Rq : 37|2@0+ (1,0) [0|3] "SED"  APIM_CDC,APIM_CIM
 SG_ BecConfg_D_Stat : 39|2@0+ (1,0) [0|3] "SED"  APIM_CDC,APIM_CIM
 SG_ Bec2Ajar_B_Stat : 44|1@0+ (1,0) [0|1] "SED"  APIM_CDC,APIM_CIM
 SG_ AvPwLftgtChime_D_Rq : 47|3@0+ (1,0) [0|7] "SED"  APIM_CDC

BO_ 788 PowertrainData_13_HS3: 8 GWM
 SG_ EcoCochATrip1_Pc_Dsply : 7|8@0+ (0.392157,0) [0|100.000035] "percent"  APIM,APIM_CDC,APIM_CIM,APIM_CISM
 SG_ EcoCochATrip2_Pc_Dsply : 15|8@0+ (0.392157,0) [0|100.000035] "percent"  APIM,APIM_CDC,APIM_CIM,APIM_CISM
 SG_ EcoCochCrus1_Pc_Dsply : 23|8@0+ (0.392157,0) [0|100.000035] "percent"  APIM,APIM_CDC,APIM_CIM,APIM_CISM
 SG_ EcoCochCrus2_Pc_Dsply : 31|8@0+ (0.392157,0) [0|100.000035] "percent"  APIM,APIM_CDC,APIM_CIM,APIM_CISM
 SG_ EcoCochDecel1_Pc_Dsply : 39|8@0+ (0.392157,0) [0|100.000035] "percent"  APIM,APIM_CDC,APIM_CIM,APIM_CISM
 SG_ EcoCochDecel2_Pc_Dsply : 47|8@0+ (0.392157,0) [0|100.000035] "percent"  APIM,APIM_CDC,APIM_CIM,APIM_CISM

BO_ 789 IPC_TripData_1: 8 APIM_CDC
 SG_ TripSum_Vl_Dsply : 1|10@0+ (0.1,0) [0|102.3] "Liters"  GWM
 SG_ VehElSurpStat_L_Dsply : 20|13@0+ (0.1,-409.4) [-409.4|409.7] "Km"  GWM
 SG_ TripSum_L_Dsply : 39|16@0+ (0.1,0) [0|6553.5] "Km"  GWM
 SG_ TripSum_E_Dsply : 48|9@0+ (0.1,0) [0|51.1] "kw*hrs"  GWM

BO_ 791 Cluster_HEV_Data8: 8 APIM_CDC
 SG_ BattElEmotive_Pc_Dsply : 1|10@0+ (0.1,0) [0|102.3] "percent"  APIM,APIM_CISM,GWM
 SG_ EcoMde_D_RqMnu : 3|2@0+ (1,0) [0|3] "SED"  GWM
 SG_ ChargeProfIDPref_Rq : 5|2@0+ (1,0) [0|3] "SED"  GWM
 SG_ HybMdeOvrrd_D_Rq : 7|2@0+ (1,0) [0|3] "SED"  GWM
 SG_ StopStrtVThres_D_RqMnu : 17|2@0+ (1,0) [0|3] "SED"  GWM
 SG_ AwdDrvMde_D2_Rq : 21|4@0+ (1,0) [0|15] "SED"  GWM
 SG_ GrdAsstAllw_D_RqMnu : 23|2@0+ (1,0) [0|3] "SED"  GWM
 SG_ ConsAvgTrip_Fe_Dsply : 31|24@0+ (0.0001,0) [0|1677.7215] "litre/100km"  GWM
 SG_ EngAirFilt_B_RqReset : 48|1@0+ (1,0) [0|1] "SED"  GWM
 SG_ LongTermReset_B_Rq : 49|1@0+ (1,0) [0|1] "SED"  GWM
 SG_ GpsElMdeSel_B_Rq : 50|1@0+ (1,0) [0|1] "SED"  GWM
 SG_ EcoCcActv_B_Rq : 51|1@0+ (1,0) [0|1] "SED"  GWM
 SG_ EmotiveType_D_Dsply : 53|2@0+ (1,0) [0|3] "SED"  APIM,APIM_CISM,GWM
 SG_ PlgOvrrdStrt_D_Cmd : 55|2@0+ (1,0) [0|3] "SED"  GWM
 SG_ DrvEffLvl_No_Stat : 61|6@0+ (1,0) [0|63] "unitless"  APIM,APIM_CISM,GWM
 SG_ VehElEffTrip2Reset_B_Rq : 62|1@0+ (1,0) [0|1] "SED"  GWM
 SG_ VehElEffTrip1Reset_B_Rq : 63|1@0+ (1,0) [0|1] "SED"  GWM

BO_ 792 IPC_Send_Signals_2: 8 APIM_CDC
 SG_ ElLongTerm_L_Dsply : 7|24@0+ (0.1,0) [0|1677721.5] "unitless"  GWM
 SG_ ElTrip_L_Dsply : 31|16@0+ (0.1,0) [0|6553.5] "unitless"  GWM
 SG_ FuelRange_L_Dsply : 45|14@0+ (0.1,0) [0|1638.3] "km"  ACM,APIM,APIM_CISM,GWM,HUD_ADV
 SG_ DsplyChkActv_B_Stat : 47|1@0+ (1,0) [0|1] "SED"  GWM,HUD_ADV
 SG_ FmesSndShrt_D_Stat : 63|2@0+ (1,0) [0|3] "SED"  GWM

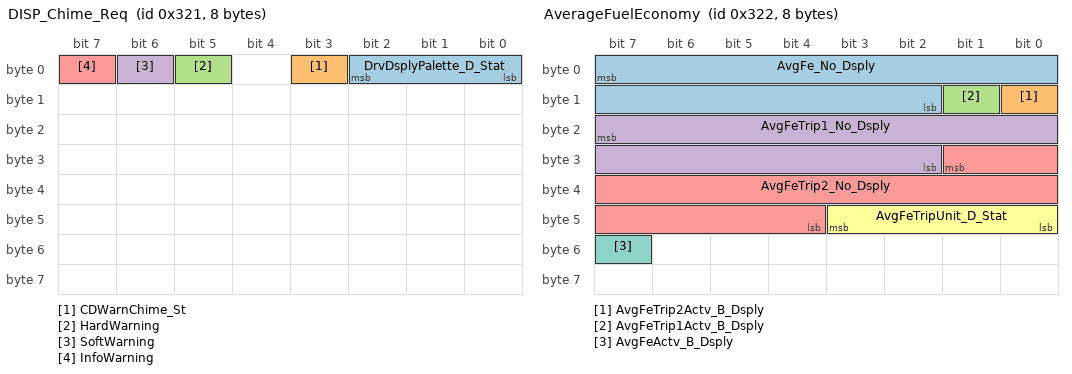
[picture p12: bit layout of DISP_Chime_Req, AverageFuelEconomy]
BO_ 801 DISP_Chime_Req: 8 APIM_CDC
 SG_ DrvDsplyPalette_D_Stat : 2|3@0+ (1,0) [0|7] "SED"  GWM,IPC,RACM_RCIM
 SG_ CDWarnChime_St : 3|1@0+ (1,0) [0|1] "SED"  GWM,IPC
 SG_ HardWarning : 5|1@0+ (1,0) [0|1] "SED"  GWM,IPC
 SG_ SoftWarning : 6|1@0+ (1,0) [0|1] "SED"  GWM,IPC
 SG_ InfoWarning : 7|1@0+ (1,0) [0|1] "SED"  GWM,IPC

BO_ 802 AverageFuelEconomy: 8 APIM_CDC
 SG_ AvgFe_No_Dsply : 7|14@0+ (0.1,0) [0|1638.3] "unitless"  APIM,APIM_CISM
 SG_ AvgFeTrip2Actv_B_Dsply : 8|1@0+ (1,0) [0|1] "SED"  APIM,APIM_CISM
 SG_ AvgFeTrip1Actv_B_Dsply : 9|1@0+ (1,0) [0|1] "SED"  APIM,APIM_CISM
 SG_ AvgFeTrip1_No_Dsply : 23|14@0+ (0.1,0) [0|1638.3] "unitless"  APIM,APIM_CISM
 SG_ AvgFeTrip2_No_Dsply : 25|14@0+ (0.1,0) [0|1638.3] "unitless"  APIM,APIM_CISM
 SG_ AvgFeTripUnit_D_Stat : 43|4@0+ (1,0) [0|15] "SED"  APIM,APIM_CISM
 SG_ AvgFeActv_B_Dsply : 55|1@0+ (1,0) [0|1] "SED"  APIM,APIM_CISM

BO_ 803 DistantTripDisplay: 8 APIM_CDC
 SG_ DistTrip1_No_Dsply : 7|17@0+ (0.1,0) [0|13107.1] "unitless"  APIM,APIM_CISM
 SG_ DistTrip2_No_Dsply : 22|17@0+ (0.1,0) [0|13107.1] "unitless"  APIM,APIM_CISM
 SG_ DistTripUnit_D_Stat : 37|2@0+ (1,0) [0|3] "SED"  APIM,APIM_CISM

BO_ 804 InstFuelEconomy_1: 8 IPC
 SG_ InstFeMax_No_Dsply : 7|8@0+ (1,0) [0|255] "unitless"  APIM,APIM_CISM
 SG_ ConsInst_No_Dsply : 15|10@0+ (0.1,0) [0|102.3] "percent"  APIM,APIM_CISM
 SG_ ConsInstUnit_D_Stat : 21|2@0+ (1,0) [0|3] "SED"  APIM,APIM_CISM
 SG_ ConsInstActv_B_Dsply : 51|1@0+ (1,0) [0|1] "SED"  APIM,APIM_CISM

BO_ 805 InstFuelEconomy_2: 8 APIM_CDC
 SG_ InstFe_No_Dsply : 7|14@0+ (0.1,0) [0|1638.3] "unitless"  APIM,APIM_CISM
 SG_ InstFeTripUnit_D_Stat : 23|4@0+ (1,0) [0|15] "SED"  APIM,APIM_CISM
 SG_ FuelRange_L2_Dsply : 31|15@0+ (0.1,0) [0|3276.7] "kilometer"  APIM,APIM_CISM,GWM,HUD_ADV

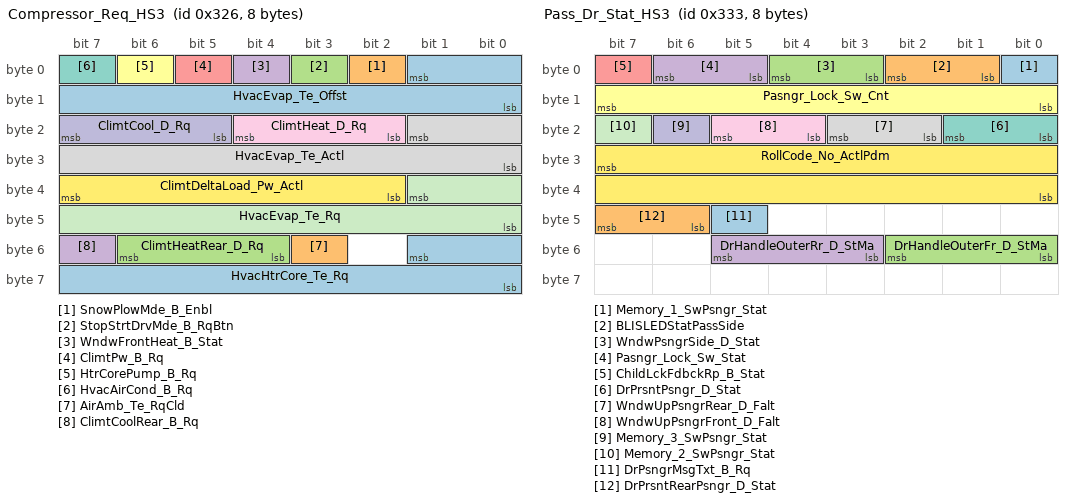
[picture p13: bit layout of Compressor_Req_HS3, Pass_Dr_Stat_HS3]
BO_ 806 Compressor_Req_HS3: 8 GWM
 SG_ HvacEvap_Te_Offst : 1|10@0+ (0.125,-50) [-50|77.875] "degC" Vector__XXX
 SG_ SnowPlowMde_B_Enbl : 2|1@0+ (1,0) [0|1] "SED"  APIM,APIM_CDC,APIM_CIM,APIM_CISM,IPC
 SG_ StopStrtDrvMde_B_RqBtn : 3|1@0+ (1,0) [0|1] "SED" Vector__XXX
 SG_ WndwFrontHeat_B_Stat : 4|1@0+ (1,0) [0|1] "SED" Vector__XXX
 SG_ ClimtPw_B_Rq : 5|1@0+ (1,0) [0|1] "SED" Vector__XXX
 SG_ HtrCorePump_B_Rq : 6|1@0+ (1,0) [0|1] "SED" Vector__XXX
 SG_ HvacAirCond_B_Rq : 7|1@0+ (1,0) [0|1] "SED" Vector__XXX
 SG_ HvacEvap_Te_Actl : 17|10@0+ (0.125,-50) [-50|77.875] "degC" Vector__XXX
 SG_ ClimtHeat_D_Rq : 20|3@0+ (1,0) [0|7] "SED" Vector__XXX
 SG_ ClimtCool_D_Rq : 23|3@0+ (1,0) [0|7] "SED" Vector__XXX
 SG_ HvacEvap_Te_Rq : 33|10@0+ (0.125,-50) [-50|77.875] "degC" Vector__XXX
 SG_ ClimtDeltaLoad_Pw_Actl : 39|6@0+ (50,-1600) [-1600|1550] "watts" Vector__XXX
 SG_ HvacHtrCore_Te_Rq : 49|10@0+ (0.25,-50) [-50|205.75] "degC" Vector__XXX
 SG_ AirAmb_Te_RqCld : 51|1@0+ (1,0) [0|1] "SED"  APIM,APIM_CDC
 SG_ ClimtHeatRear_D_Rq : 54|3@0+ (1,0) [0|7] "SED" Vector__XXX
 SG_ ClimtCoolRear_B_Rq : 55|1@0+ (1,0) [0|1] "SED" Vector__XXX

BO_ 807 InstFuelEconomy_3: 8 IPC
 SG_ ElDistTrip1_No_Dsply : 7|17@0+ (0.1,0) [0|13107.1] "unitless"  APIM,APIM_CISM
 SG_ ElDistTrip2_No_Dsply : 22|17@0+ (0.1,0) [0|13107.1] "unitless"  APIM,APIM_CISM
 SG_ ElDistTripCur_No_Dsply : 35|17@0+ (0.1,0) [0|13107.1] "unitless"  APIM,APIM_CISM
 SG_ ElDistTripUnit_D_Stat : 37|2@0+ (1,0) [0|3] "SED"  APIM,APIM_CISM

BO_ 810 ECG_Data_HS3: 8 GWM
 SG_ TrlrIdActv_No_Rq : 4|4@0+ (1,0) [0|15] "unitless"  APIM,APIM_CDC,APIM_CIM
 SG_ ExtLghtDsply_B_StatArb : 7|1@0+ (1,0) [0|1] "SED"  APIM,APIM_CDC,APIM_CIM,APIM_CISM
 SG_ ScOnb_D_Rq : 15|2@0+ (1,0) [0|3] "SED"  APIM,APIM_CDC,APIM_CIM,APIM_CISM
 SG_ OneTEditActv_B_RqCld : 32|1@0+ (1,0) [0|1] "SED"  APIM,APIM_CDC,APIM_CIM,APIM_CISM

BO_ 811 APIM_Data: 8 APIM_CDC
 SG_ ExtLghtLeft_D_RqMnu : 1|3@0+ (1,0) [0|7] "SED"  GWM
 SG_ ExtLghtFront_D_RqMnu : 4|3@0+ (1,0) [0|7] "SED"  GWM
 SG_ ExtLghtDsply_D_Stat : 7|3@0+ (1,0) [0|7] "SED"  GWM
 SG_ AutoLghtOvrrd_B_RqDrv : 8|1@0+ (1,0) [0|1] "SED"  GWM
 SG_ ExtLghtRight_D_RqMnu : 11|3@0+ (1,0) [0|7] "SED"  GWM
 SG_ ExtLghtRear_D_RqMnu : 14|3@0+ (1,0) [0|7] "SED"  GWM
 SG_ OnePdlDrvButtn_B_Falt : 16|1@0+ (1,0) [0|1] "SED"  GWM
 SG_ LongTermReset_B_RqMnu : 17|1@0+ (1,0) [0|1] "SED"  GWM
 SG_ TrnkFrontRleas_No_RqMnu : 20|3@0+ (1,0) [0|7] "unitless"  GWM
 SG_ BecRleas_No_RqMnu : 23|3@0+ (1,0) [0|7] "unitless"  GWM
 SG_ DistToStopover_L_Actl : 31|16@0+ (0.1,0) [0|6553.5] "kilometer"  GWM,IPC
 SG_ GoTEditHr_T_RqMnu : 44|5@0+ (1,0) [0|31] "SED"  GWM
 SG_ StopoverType_D_Stat : 47|3@0+ (1,0) [0|7] "SED"  GWM,IPC
 SG_ OnePdlDrvButtn_B_Stat : 48|1@0+ (1,0) [0|1] "SED"  GWM
 SG_ ScMnSoc_Pc_RqMnu : 55|7@0+ (1,0) [0|127] "percent"  GWM
 SG_ ScEnbl_D_RqMnu : 57|2@0+ (1,0) [0|3] "SED"  GWM
 SG_ SpeedoMajorUnit_D_Confg : 59|2@0+ (1,0) [0|3] "SED"  GWM
 SG_ GoTEditMnte_T_RqMnu : 63|4@0+ (1,0) [0|15] "SED"  GWM

BO_ 812 TimerDisplay_Data: 8 IPC
 SG_ TimerTrip1_T_Dsply : 7|26@0+ (1,0) [0|67108863] "second"  APIM,APIM_CISM
 SG_ TimerTrip2_T_Dsply : 29|26@0+ (1,0) [0|67108863] "second"  APIM,APIM_CISM

BO_ 813 TimerDisplay_Data2: 8 IPC
 SG_ TimerTripCurnt_T_Dsply : 7|26@0+ (1,0) [0|67108863] "second"  APIM,APIM_CISM

BO_ 816 APIM_Send_Signals_3: 8 APIM_CDC
 SG_ KeyPadCodeDgt2_D_Stat : 3|4@0+ (1,0) [0|15] "SED"  GWM
 SG_ KeyPadCodeDgt1_D_Stat : 7|4@0+ (1,0) [0|15] "SED"  GWM
 SG_ KeyPadCodeDgt4_D_Stat : 11|4@0+ (1,0) [0|15] "SED"  GWM
 SG_ KeyPadCodeDgt3_D_Stat : 15|4@0+ (1,0) [0|15] "SED"  GWM
 SG_ KeyPadCodeDgt6_D_Stat : 19|4@0+ (1,0) [0|15] "SED"  GWM
 SG_ KeyPadCodeDgt5_D_Stat : 23|4@0+ (1,0) [0|15] "SED"  GWM
 SG_ DcacPwResetScnd_B_Rq : 24|1@0+ (1,0) [0|1] "SED"  GWM
 SG_ CntrStk2_D_RqAssoc : 27|3@0+ (1,0) [0|7] "SED"  GWM
 SG_ KeyPadCodeDgt7_D_Stat : 31|4@0+ (1,0) [0|15] "SED"  GWM
 SG_ DcacLoFuelLim_L_RqMnu : 32|9@0+ (1,0) [0|511] "kilometer"  GWM
 SG_ NfcMyKeyCreate_D_Rq : 33|1@0+ (1,0) [0|1] "SED"  GWM
 SG_ DcacZone2Pw_D_Rq : 35|2@0+ (1,0) [0|3] "SED"  GWM
 SG_ DcacAllZone_D_Rq : 37|2@0+ (1,0) [0|3] "SED"  GWM
 SG_ KeylessIdl_D_Rq : 39|2@0+ (1,0) [0|3] "SED"  GWM
 SG_ DgtlKeyPrflAssoc_D_Rq : 51|3@0+ (1,0) [0|7] "SED"  GWM
 SG_ DcacPwScnd_D_Rq : 53|2@0+ (1,0) [0|3] "SED"  GWM
 SG_ DcacZone3Pw_D_Rq : 55|2@0+ (1,0) [0|3] "SED"  GWM
 SG_ HybMdeSel_D_Rq : 58|3@0+ (1,0) [0|7] "SED"  GWM
 SG_ Dimming_Lvl_RqMnu : 63|5@0+ (1,0) [0|31] "SED"  GWM

BO_ 817 Locking_Systems_2_HS3: 8 GWM
 SG_ Power_Liftgate_Rqst : 0|1@0+ (1,0) [0|1] "SED" Vector__XXX
 SG_ Power_Decklid_Rqst : 1|1@0+ (1,0) [0|1] "SED" Vector__XXX
 SG_ LockInhibit : 2|1@0+ (1,0) [0|1] "SED"  APIM,APIM_CDC,APIM_CIM,APIM_CISM
 SG_ L_Pwr_Sliding_Dr_Rqst : 3|1@0+ (1,0) [0|1] "SED" Vector__XXX
 SG_ FobComm_D_Stat : 5|2@0+ (1,0) [0|3] "SED" Vector__XXX
 SG_ CamperMde_D_Stat : 7|2@0+ (1,0) [0|3] "SED" Vector__XXX
 SG_ Keyfob_Pad_Msg_Count : 15|8@0+ (1,0) [0|255] "Counts" Vector__XXX
 SG_ RollCodeUnlock : 23|16@0+ (1,0) [0|65535] "unitless"  APIM_CDC,APIM_CIM,IPC
 SG_ DrTgateExtSwMde_B_Stat : 32|1@0+ (1,0) [0|1] "SED" Vector__XXX
 SG_ Veh_Lock_Status : 34|2@0+ (1,0) [0|3] "SED"  ACM,APIM,APIM_CDC,APIM_CIM,APIM_CISM,HUD_ADV,IPC,MRCMB_RDAPM_HS3,RACM_RCIM
 SG_ WindowLockout_B_Stat : 35|1@0+ (1,0) [0|1] "SED"  RACM_RCIM
 SG_ R_Pwr_Sliding_Dr_Rqst : 36|1@0+ (1,0) [0|1] "SED" Vector__XXX
 SG_ Lockmsgtxt_D_Rq : 39|3@0+ (1,0) [0|7] "SED"  APIM_CDC,APIM_CIM,IPC
 SG_ Veh_Lock_EvNum : 47|8@0+ (1,0) [0|255] "unitless"  APIM_CDC,APIM_CIM,HUD_ADV,IPC
 SG_ Remote_Device_Feedback : 50|3@0+ (1,0) [0|7] "SED" Vector__XXX
 SG_ Veh_Lock_Requestor : 55|5@0+ (1,0) [0|31] "SED"  APIM,APIM_CDC,APIM_CIM,APIM_CISM,HUD_ADV
 SG_ ChildLckMde_B_Stat : 56|1@0+ (1,0) [0|1] "SED"  GENERIC
 SG_ VehLckInd_D_Rq : 58|2@0+ (1,0) [0|3] "SED" Vector__XXX
 SG_ DrTgateOpen_B_Rq : 59|1@0+ (1,0) [0|1] "SED" Vector__XXX
 SG_ Veh_Lock_Sub_Id : 63|4@0+ (1,0) [0|15] "SED" Vector__XXX

BO_ 818 Driver_Dr_Stat_HS3: 8 GWM
 SG_ WndwDrvSide_D_Stat : 1|2@0+ (1,0) [0|3] "SED" Vector__XXX
 SG_ KeyCylSwDrvDr_D_Stat : 3|2@0+ (1,0) [0|3] "SED" Vector__XXX
 SG_ Driver_Lock_Sw_Stat : 5|2@0+ (1,0) [0|3] "SED" Vector__XXX
 SG_ ChildLckPw_D_Rq : 6|1@0+ (1,0) [0|1] "SED" Vector__XXX
 SG_ ChildLckFdbckRd_B_Stat : 7|1@0+ (1,0) [0|1] "SED" Vector__XXX
 SG_ Driver_Lock_Sw_Cnt : 15|8@0+ (1,0) [0|255] "Cnt" Vector__XXX
 SG_ RollCodeDrvDrKeyCyl : 23|16@0+ (1,0) [0|65535] "unitless" Vector__XXX
 SG_ ChildLckPw_N_Cnt : 39|8@0+ (1,0) [0|255] "unitless" Vector__XXX
 SG_ DrvSpotLight_B_Stat : 40|1@0+ (1,0) [0|1] "SED" Vector__XXX
 SG_ WndwUpDrvRear_D_Falt : 42|2@0+ (1,0) [0|3] "SED" Vector__XXX
 SG_ WndwUpDrvFront_D_Falt : 44|2@0+ (1,0) [0|3] "SED" Vector__XXX
 SG_ RvrseMirrorChime_B_Rq : 45|1@0+ (1,0) [0|1] "SED"  APIM_CDC,APIM_CIM,IPC
 SG_ BLISLEDStatDriverSide : 47|2@0+ (1,0) [0|3] "SED" Vector__XXX
 SG_ DrDrvMsgTxt_B_Rq : 51|1@0+ (1,0) [0|1] "SED"  APIM_CDC,APIM_CIM,IPC
 SG_ DrPrsntRearDrv_D_Stat : 53|2@0+ (1,0) [0|3] "SED"  APIM,APIM_CDC,APIM_CIM,APIM_CISM,IPC
 SG_ DrPrsntDrv_D_Stat : 55|2@0+ (1,0) [0|3] "SED"  APIM,APIM_CDC,APIM_CIM,APIM_CISM,IPC
 SG_ DrHandleOuterFl_D_StMa : 58|3@0+ (1,0) [0|7] "SED" Vector__XXX
 SG_ DrHandleOuterRl_D_StMa : 61|3@0+ (1,0) [0|7] "SED" Vector__XXX

BO_ 819 Pass_Dr_Stat_HS3: 8 GWM
 SG_ Memory_1_SwPsngr_Stat : 0|1@0+ (1,0) [0|1] "SED" Vector__XXX
 SG_ BLISLEDStatPassSide : 2|2@0+ (1,0) [0|3] "SED" Vector__XXX
 SG_ WndwPsngrSide_D_Stat : 4|2@0+ (1,0) [0|3] "SED" Vector__XXX
 SG_ Pasngr_Lock_Sw_Stat : 6|2@0+ (1,0) [0|3] "SED" Vector__XXX
 SG_ ChildLckFdbckRp_B_Stat : 7|1@0+ (1,0) [0|1] "SED" Vector__XXX
 SG_ Pasngr_Lock_Sw_Cnt : 15|8@0+ (1,0) [0|255] "Cnt" Vector__XXX
 SG_ DrPrsntPsngr_D_Stat : 17|2@0+ (1,0) [0|3] "SED"  APIM,APIM_CDC,APIM_CIM,APIM_CISM,IPC
 SG_ WndwUpPsngrRear_D_Falt : 19|2@0+ (1,0) [0|3] "SED" Vector__XXX
 SG_ WndwUpPsngrFront_D_Falt : 21|2@0+ (1,0) [0|3] "SED" Vector__XXX
 SG_ Memory_3_SwPsngr_Stat : 22|1@0+ (1,0) [0|1] "SED" Vector__XXX
 SG_ Memory_2_SwPsngr_Stat : 23|1@0+ (1,0) [0|1] "SED" Vector__XXX
 SG_ RollCode_No_ActlPdm : 31|16@0+ (1,0) [0|65535] "unitless" Vector__XXX
 SG_ DrPsngrMsgTxt_B_Rq : 45|1@0+ (1,0) [0|1] "SED"  APIM_CDC,APIM_CIM,IPC
 SG_ DrPrsntRearPsngr_D_Stat : 47|2@0+ (1,0) [0|3] "SED"  APIM,APIM_CDC,APIM_CIM,APIM_CISM,IPC
 SG_ DrHandleOuterFr_D_StMa : 50|3@0+ (1,0) [0|7] "SED" Vector__XXX
 SG_ DrHandleOuterRr_D_StMa : 53|3@0+ (1,0) [0|7] "SED" Vector__XXX

BO_ 820 Adaptive_Headlamp_Stat_HS3: 8 GWM
 SG_ HeadLghtHiOn_B_StatHcm : 0|1@0+ (1,0) [0|1] "SED"  APIM_CDC,APIM_CIM,IPC
 SG_ TailLghtAnmtn_D_Stat : 4|4@0+ (1,0) [0|15] "SED"  APIM,APIM_CDC,APIM_CIM,APIM_CISM
 SG_ TurnLampFrOut_B_Stat : 5|1@0+ (1,0) [0|1] "SED" Vector__XXX
 SG_ TurnLampFlOut_B_Stat : 6|1@0+ (1,0) [0|1] "SED" Vector__XXX
 SG_ Adaptive_Hdlmp_Fault : 7|1@0+ (1,0) [0|1] "SED"  APIM_CDC,APIM_CIM,IPC
 SG_ HeadLampLoFlOut_B_Stat : 8|1@0+ (1,0) [0|1] "SED" Vector__XXX
 SG_ HeadLampLoFrOut_B_Stat : 9|1@0+ (1,0) [0|1] "SED" Vector__XXX
 SG_ DgtlShadeAr2_D_Stat : 12|3@0+ (1,0) [0|7] "SED"  APIM_CDC,APIM_CIM,GWM,RACM_RCIM
 SG_ DgtlShadeAr1_D_Stat : 15|3@0+ (1,0) [0|7] "SED"  APIM_CDC,APIM_CIM,GWM,RACM_RCIM
 SG_ DgtlShadeAr4_D_Stat : 20|3@0+ (1,0) [0|7] "SED"  APIM_CDC,APIM_CIM,GWM,RACM_RCIM
 SG_ DgtlShadeAr3_D_Stat : 23|3@0+ (1,0) [0|7] "SED"  APIM_CDC,APIM_CIM,GWM,RACM_RCIM
 SG_ DgtlShadeAr6_D_Stat : 28|3@0+ (1,0) [0|7] "SED"  APIM_CDC,APIM_CIM,GWM,RACM_RCIM
 SG_ DgtlShadeAr5_D_Stat : 31|3@0+ (1,0) [0|7] "SED"  APIM_CDC,APIM_CIM,GWM,RACM_RCIM
 SG_ DrDefeatMde_B_Stat : 32|1@0+ (1,0) [0|1] "Unitless"  APIM_CDC,APIM_CIM
 SG_ HeadLghtDrvSide_B_Stat : 33|1@0+ (1,0) [0|1] "SED" Vector__XXX
 SG_ DgtlShadeMde_D_Stat : 39|3@0+ (1,0) [0|7] "SED"  APIM_CDC,APIM_CIM,GWM,RACM_RCIM
 SG_ AhbStatGfhbFdbk_D_Actl : 53|2@0+ (1,0) [0|3] "SED" Vector__XXX

BO_ 826 Memory_Sw_StatM_HS3: 8 GWM
 SG_ Mirror_Manual_Override : 0|1@0+ (1,0) [0|1] "SED"  APIM_CIM,APIM_CISM
 SG_ Memory_3_Sw_Stat : 4|1@0+ (1,0) [0|1] "SED" Vector__XXX
 SG_ Memory_2_Sw_Stat : 5|1@0+ (1,0) [0|1] "SED" Vector__XXX
 SG_ Memory_1_Sw_Stat : 6|1@0+ (1,0) [0|1] "SED" Vector__XXX

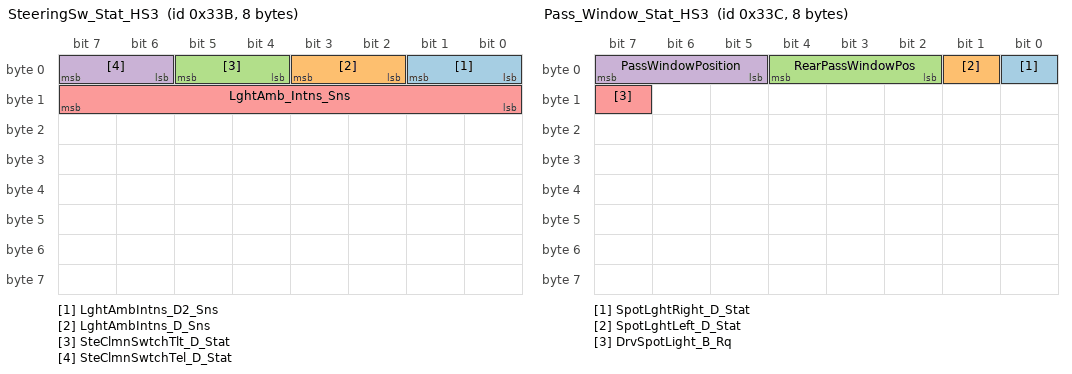
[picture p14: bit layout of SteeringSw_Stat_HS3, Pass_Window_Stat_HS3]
BO_ 827 SteeringSw_Stat_HS3: 8 GWM
 SG_ LghtAmbIntns_D2_Sns : 1|2@0+ (1,0) [0|3] "SED"  APIM_CIM,HUD_ADV
 SG_ LghtAmbIntns_D_Sns : 3|2@0+ (1,0) [0|3] "SED"  APIM_CIM,HUD_ADV
 SG_ SteClmnSwtchTlt_D_Stat : 5|2@0+ (1,0) [0|3] "SED" Vector__XXX
 SG_ SteClmnSwtchTel_D_Stat : 7|2@0+ (1,0) [0|3] "SED" Vector__XXX
 SG_ LghtAmb_Intns_Sns : 15|8@0+ (1,0) [0|255] "unitless"  APIM_CIM,HUD_ADV

BO_ 828 Pass_Window_Stat_HS3: 8 GWM
 SG_ SpotLghtRight_D_Stat : 0|1@0+ (1,0) [0|1] "SED"  APIM,APIM_CDC,APIM_CIM,APIM_CISM
 SG_ SpotLghtLeft_D_Stat : 1|1@0+ (1,0) [0|1] "SED"  APIM,APIM_CDC,APIM_CIM,APIM_CISM
 SG_ RearPassWindowPos : 4|3@0+ (1,0) [0|7] "SED"  ACM,APIM,APIM_CDC,APIM_CIM,APIM_CISM,WCM,WCMB,WCMC
 SG_ PassWindowPosition : 7|3@0+ (1,0) [0|7] "SED"  ACM,APIM,APIM_CDC,APIM_CIM,APIM_CISM,WCM,WCMB,WCMC
 SG_ DrvSpotLight_B_Rq : 15|1@0+ (1,0) [0|1] "SED" Vector__XXX

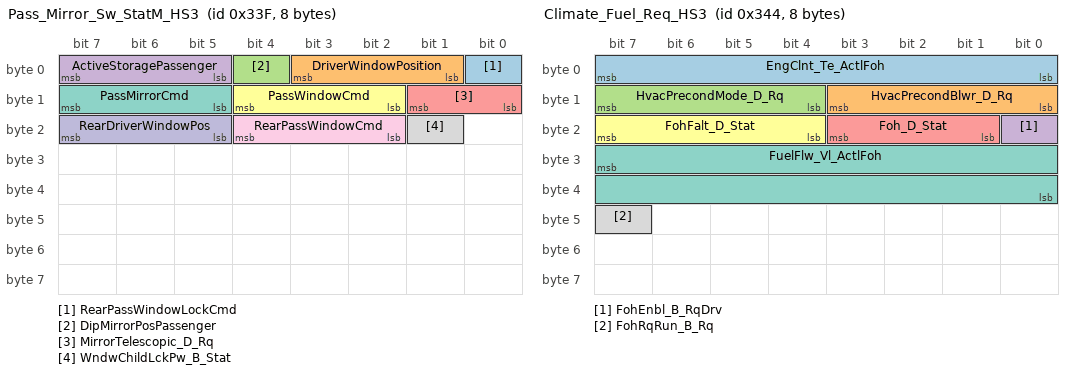
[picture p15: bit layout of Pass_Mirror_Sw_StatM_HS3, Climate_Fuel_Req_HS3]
BO_ 831 Pass_Mirror_Sw_StatM_HS3: 8 GWM
 SG_ RearPassWindowLockCmd : 0|1@0+ (1,0) [0|1] "SED" Vector__XXX
 SG_ DriverWindowPosition : 3|3@0+ (1,0) [0|7] "SED"  ACM,APIM,APIM_CDC,APIM_CIM,APIM_CISM,WCM,WCMB,WCMC
 SG_ DipMirrorPosPassenger : 4|1@0+ (1,0) [0|1] "SED" Vector__XXX
 SG_ ActiveStoragePassenger : 7|3@0+ (1,0) [0|7] "SED" Vector__XXX
 SG_ MirrorTelescopic_D_Rq : 9|2@0+ (1,0) [0|3] "SED" Vector__XXX
 SG_ PassWindowCmd : 12|3@0+ (1,0) [0|7] "SED" Vector__XXX
 SG_ PassMirrorCmd : 15|3@0+ (1,0) [0|7] "SED" Vector__XXX
 SG_ WndwChildLckPw_B_Stat : 17|1@0+ (1,0) [0|1] "SED"  APIM_CDC,APIM_CIM
 SG_ RearPassWindowCmd : 20|3@0+ (1,0) [0|7] "SED" Vector__XXX
 SG_ RearDriverWindowPos : 23|3@0+ (1,0) [0|7] "SED"  ACM,APIM,APIM_CDC,APIM_CIM,APIM_CISM,WCM,WCMB,WCMC

BO_ 836 Climate_Fuel_Req_HS3: 8 GWM
 SG_ EngClnt_Te_ActlFoh : 7|8@0+ (1,-50) [-50|205] "degC" Vector__XXX
 SG_ HvacPrecondBlwr_D_Rq : 11|4@0+ (1,0) [0|15] "SED" Vector__XXX
 SG_ HvacPrecondMode_D_Rq : 15|4@0+ (1,0) [0|15] "SED" Vector__XXX
 SG_ FohEnbl_B_RqDrv : 16|1@0+ (1,0) [0|1] "SED" Vector__XXX
 SG_ Foh_D_Stat : 19|3@0+ (1,0) [0|7] "SED" Vector__XXX
 SG_ FohFalt_D_Stat : 23|4@0+ (1,0) [0|15] "SED" Vector__XXX
 SG_ FuelFlw_Vl_ActlFoh : 31|16@0+ (25,0) [0|1638375] "microlitre"  APIM,APIM_CDC,APIM_CIM,APIM_CISM,IPC
 SG_ FohRqRun_B_Rq : 47|1@0+ (1,0) [0|1] "SED" Vector__XXX

BO_ 837 VeyDynamics_Data_HS3: 8 GWM
 SG_ AirSusp_D_Stat : 1|2@0+ (1,0) [0|3] "SED"  APIM_CDC,APIM_CIM,IPC
 SG_ AirSuspMsgTxt_D_Rq : 3|2@0+ (1,0) [0|3] "SED"  APIM_CDC,APIM_CIM,IPC
 SG_ CcdMsgTxt_D_RqDsply : 7|4@0+ (1,0) [0|15] "SED"  ACM,APIM_CDC,APIM_CIM,APIM_CISM,IPC
 SG_ AdptDrvMdeChassis_D_Rq : 10|3@0+ (1,0) [0|7] "SED" Vector__XXX
 SG_ VdmSustnActv_B_Rq : 12|1@0+ (1,0) [0|1] "SED" Vector__XXX
 SG_ SuspDrvMde_D_Stat : 15|3@0+ (1,0) [0|7] "SED"  APIM_CDC,APIM_CIM,IPC
 SG_ AirSprngRateFl_D_Rq : 17|2@0+ (1,0) [0|3] "SED" Vector__XXX
 SG_ SuspVLim_B_Rq : 18|1@0+ (1,0) [0|1] "SED" Vector__XXX
 SG_ SelDrvMdeSusp_D_Stat : 20|2@0+ (1,0) [0|3] "SED" Vector__XXX
 SG_ AdptDrvMdePt_D_Rq : 23|3@0+ (1,0) [0|7] "SED" Vector__XXX
 SG_ Ccd_B_Falt : 24|1@0+ (1,0) [0|1] "SED"  APIM_CDC,APIM_CIM,IPC
 SG_ SuspType_B_Stat : 25|1@0+ (1,0) [0|1] "SED" Vector__XXX
 SG_ AirSprngRateRr_D_Rq : 27|2@0+ (1,0) [0|3] "SED" Vector__XXX
 SG_ AirSprngRateRl_D_Rq : 29|2@0+ (1,0) [0|3] "SED" Vector__XXX
 SG_ AirSprngRateFr_D_Rq : 31|2@0+ (1,0) [0|3] "SED" Vector__XXX
 SG_ SuspVLimBRq_No_Cs : 39|8@0+ (1,0) [0|255] "Unitless" Vector__XXX
 SG_ VehCurb_M_Actl : 43|10@0+ (5,0) [0|5115] "kilogram"  APIM,APIM_CDC,APIM_CIM,APIM_CISM
 SG_ SuspVLimBRq_No_Cnt : 47|4@0+ (1,0) [0|15] "Unitless" Vector__XXX
 SG_ VehGvwr_M_Actl : 49|10@0+ (10,0) [0|10230] "kilogram"  APIM,APIM_CDC,APIM_CIM,APIM_CISM

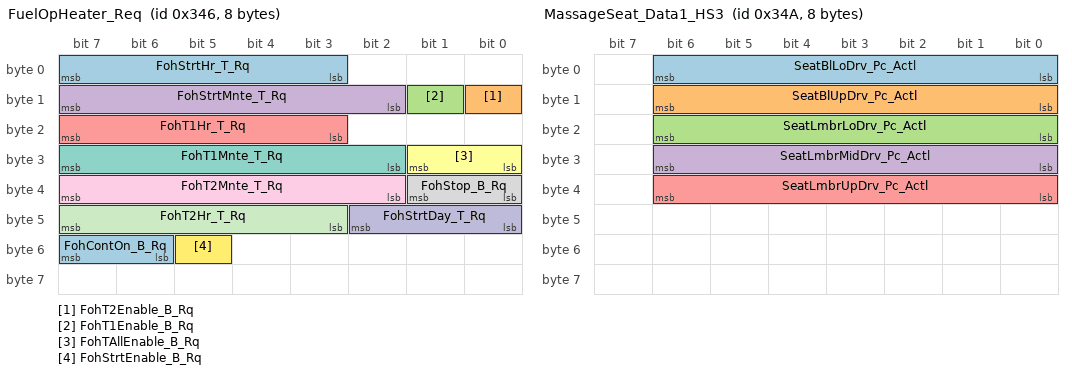
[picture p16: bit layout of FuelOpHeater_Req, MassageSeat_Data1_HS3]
BO_ 838 FuelOpHeater_Req: 8 APIM_CDC
 SG_ FohStrtHr_T_Rq : 7|5@0+ (1,0) [0|31] "hour"  GWM
 SG_ FohT2Enable_B_Rq : 8|1@0+ (1,0) [0|1] "SED"  GWM
 SG_ FohT1Enable_B_Rq : 9|1@0+ (1,0) [0|1] "SED"  GWM
 SG_ FohStrtMnte_T_Rq : 15|6@0+ (1,0) [0|63] "minute"  GWM
 SG_ FohT1Hr_T_Rq : 23|5@0+ (1,0) [0|31] "hour"  GWM
 SG_ FohTAllEnable_B_Rq : 25|2@0+ (1,0) [0|3] "SED"  GWM
 SG_ FohT1Mnte_T_Rq : 31|6@0+ (1,0) [0|63] "minute"  GWM
 SG_ FohStop_B_Rq : 33|2@0+ (1,0) [0|3] "SED"  GWM
 SG_ FohT2Mnte_T_Rq : 39|6@0+ (1,0) [0|63] "minute"  GWM
 SG_ FohStrtDay_T_Rq : 42|3@0+ (1,0) [0|7] "SED"  GWM
 SG_ FohT2Hr_T_Rq : 47|5@0+ (1,0) [0|31] "hour"  GWM
 SG_ FohStrtEnable_B_Rq : 53|1@0+ (1,0) [0|1] "SED"  GWM
 SG_ FohContOn_B_Rq : 55|2@0+ (1,0) [0|3] "SED"  GWM

BO_ 839 FuelOpHeater_Stat_HS3: 8 GWM
 SG_ FohT1Enable_B_Stat : 0|1@0+ (1,0) [0|1] "SED"  APIM_CDC,APIM_CIM,IPC
 SG_ FohStrtEnable_B_Stat : 1|1@0+ (1,0) [0|1] "SED"  APIM_CDC,APIM_CIM,IPC
 SG_ FohMsgTxt_D_Rq : 4|3@0+ (1,0) [0|7] "SED"  APIM_CDC,APIM_CIM,IPC
 SG_ FohT1Friday_T_Stat : 5|1@0+ (1,0) [0|1] "SED"  APIM_CDC,APIM_CIM,IPC
 SG_ FohKeyOff_B_Rq : 6|1@0+ (1,0) [0|1] "SED"  APIM_CDC,APIM_CIM,IPC
 SG_ FohEnbl_B_Rq : 7|1@0+ (1,0) [0|1] "SED"  APIM_CDC,APIM_CIM,IPC
 SG_ FohStrtDay_T_Stat : 10|3@0+ (1,0) [0|7] "SED"  APIM_CDC,APIM_CIM,IPC
 SG_ FohStrtHr_T_Stat : 15|5@0+ (1,0) [0|31] "hour"  APIM_CDC,APIM_CIM,IPC
 SG_ FohTAllEnable_B_Stat : 17|2@0+ (1,0) [0|3] "SED"  APIM_CDC,APIM_CIM,IPC
 SG_ FohStrtMnte_T_Stat : 23|6@0+ (1,0) [0|63] "minute"  APIM_CDC,APIM_CIM,IPC
 SG_ FohT1Sunday_T_Stat : 24|1@0+ (1,0) [0|1] "SED"  APIM_CDC,APIM_CIM,IPC
 SG_ FohT1Saturday_T_Stat : 25|1@0+ (1,0) [0|1] "SED"  APIM_CDC,APIM_CIM,IPC
 SG_ FohT1Monday_T_Stat : 26|1@0+ (1,0) [0|1] "SED"  APIM_CDC,APIM_CIM,IPC
 SG_ FohT1Hr_T_Stat : 31|5@0+ (1,0) [0|31] "hour"  APIM_CDC,APIM_CIM,IPC
 SG_ FohContOn_B_Stat : 33|2@0+ (1,0) [0|3] "SED"  APIM_CDC,APIM_CIM,IPC
 SG_ FohT1Mnte_T_Stat : 39|6@0+ (1,0) [0|63] "minute"  APIM_CDC,APIM_CIM,IPC
 SG_ FohT1Wednesday_T_Stat : 40|1@0+ (1,0) [0|1] "SED"  APIM_CDC,APIM_CIM,IPC
 SG_ FohT1Tuesday_T_Stat : 41|1@0+ (1,0) [0|1] "SED"  APIM_CDC,APIM_CIM,IPC
 SG_ FohT1Thursday_T_Stat : 42|1@0+ (1,0) [0|1] "SED"  APIM_CDC,APIM_CIM,IPC
 SG_ FohT2Hr_T_Stat : 47|5@0+ (1,0) [0|31] "hour"  APIM_CDC,APIM_CIM,IPC
 SG_ FohStop_B_Stat : 49|2@0+ (1,0) [0|3] "SED"  APIM_CDC,APIM_CIM,IPC
 SG_ FohT2Mnte_T_Stat : 55|6@0+ (1,0) [0|63] "minute"  APIM_CDC,APIM_CIM,IPC
 SG_ FohT2Wednesday_T_Stat : 56|1@0+ (1,0) [0|1] "SED"  APIM_CDC,APIM_CIM,IPC
 SG_ FohT2Tuesday_T_Stat : 57|1@0+ (1,0) [0|1] "SED"  APIM_CDC,APIM_CIM,IPC
 SG_ FohT2Thursday_T_Stat : 58|1@0+ (1,0) [0|1] "SED"  APIM_CDC,APIM_CIM,IPC
 SG_ FohT2Sunday_T_Stat : 59|1@0+ (1,0) [0|1] "SED"  APIM_CDC,APIM_CIM,IPC
 SG_ FohT2Saturday_T_Stat : 60|1@0+ (1,0) [0|1] "SED"  APIM_CDC,APIM_CIM,IPC
 SG_ FohT2Monday_T_Stat : 61|1@0+ (1,0) [0|1] "SED"  APIM_CDC,APIM_CIM,IPC
 SG_ FohT2Friday_T_Stat : 62|1@0+ (1,0) [0|1] "SED"  APIM_CDC,APIM_CIM,IPC
 SG_ FohT2Enable_B_Stat : 63|1@0+ (1,0) [0|1] "SED"  APIM_CDC,APIM_CIM,IPC

BO_ 840 FoH_Day_Req: 8 APIM_CDC
 SG_ FohT2Friday_T_Rq : 0|1@0+ (1,0) [0|1] "SED"  GWM
 SG_ FohT1Wednesday_T_Rq : 1|1@0+ (1,0) [0|1] "SED"  GWM
 SG_ FohT1Tuesday_T_Rq : 2|1@0+ (1,0) [0|1] "SED"  GWM
 SG_ FohT1Thursday_T_Rq : 3|1@0+ (1,0) [0|1] "SED"  GWM
 SG_ FohT1Sunday_T_Rq : 4|1@0+ (1,0) [0|1] "SED"  GWM
 SG_ FohT1Saturday_T_Rq : 5|1@0+ (1,0) [0|1] "SED"  GWM
 SG_ FohT1Monday_T_Rq : 6|1@0+ (1,0) [0|1] "SED"  GWM
 SG_ FohT1Friday_T_Rq : 7|1@0+ (1,0) [0|1] "SED"  GWM
 SG_ FohAddHeater_D_Rq : 9|2@0+ (1,0) [0|3] "SED"  GWM
 SG_ FohT2Wednesday_T_Rq : 10|1@0+ (1,0) [0|1] "SED"  GWM
 SG_ FohT2Tuesday_T_Rq : 11|1@0+ (1,0) [0|1] "SED"  GWM
 SG_ FohT2Thursday_T_Rq : 12|1@0+ (1,0) [0|1] "SED"  GWM
 SG_ FohT2Sunday_T_Rq : 13|1@0+ (1,0) [0|1] "SED"  GWM
 SG_ FohT2Saturday_T_Rq : 14|1@0+ (1,0) [0|1] "SED"  GWM
 SG_ FohT2Monday_T_Rq : 15|1@0+ (1,0) [0|1] "SED"  GWM
 SG_ FohStrtDateDay_No_Rq : 23|16@0+ (1,0) [0|65535] "julian day"  GWM
 SG_ FohStrtDateYr_No_Rq : 39|8@0+ (1,2000) [2000|2255] "year"  GWM

BO_ 841 FuelOpHeater_Stat2_HS3: 8 GWM
 SG_ FohStrtDateDay_No_Stat : 7|16@0+ (1,0) [0|65535] "julian day"  APIM_CDC,APIM_CIM,IPC
 SG_ FohStrtDateYr_No_Stat : 23|8@0+ (1,2000) [2000|2255] "year"  APIM_CDC,APIM_CIM,IPC
 SG_ FohAddHeater_D_Stat : 31|2@0+ (1,0) [0|3] "SED"  APIM_CDC,APIM_CIM,IPC

BO_ 842 MassageSeat_Data1_HS3: 8 GWM
 SG_ SeatBlLoDrv_Pc_Actl : 6|7@0+ (1,0) [0|127] "Percent"  APIM,APIM_CDC,APIM_CIM,APIM_CISM
 SG_ SeatBlUpDrv_Pc_Actl : 14|7@0+ (1,0) [0|127] "Percent"  APIM,APIM_CDC,APIM_CIM,APIM_CISM
 SG_ SeatLmbrLoDrv_Pc_Actl : 22|7@0+ (1,0) [0|127] "Percent"  APIM,APIM_CDC,APIM_CIM,APIM_CISM
 SG_ SeatLmbrMidDrv_Pc_Actl : 30|7@0+ (1,0) [0|127] "Percent"  APIM,APIM_CDC,APIM_CIM,APIM_CISM
 SG_ SeatLmbrUpDrv_Pc_Actl : 38|7@0+ (1,0) [0|127] "Percent"  APIM,APIM_CDC,APIM_CIM,APIM_CISM

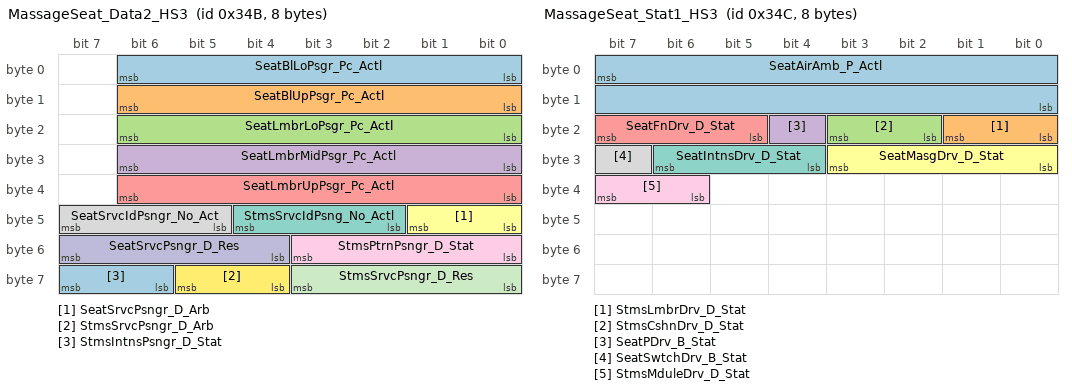
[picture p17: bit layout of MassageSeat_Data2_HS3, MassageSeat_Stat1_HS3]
BO_ 843 MassageSeat_Data2_HS3: 8 GWM
 SG_ SeatBlLoPsgr_Pc_Actl : 6|7@0+ (1,0) [0|127] "Percent"  APIM,APIM_CDC,APIM_CIM,APIM_CISM
 SG_ SeatBlUpPsgr_Pc_Actl : 14|7@0+ (1,0) [0|127] "Percent"  APIM,APIM_CDC,APIM_CIM,APIM_CISM
 SG_ SeatLmbrLoPsgr_Pc_Actl : 22|7@0+ (1,0) [0|127] "Percent"  APIM,APIM_CDC,APIM_CIM,APIM_CISM
 SG_ SeatLmbrMidPsgr_Pc_Actl : 30|7@0+ (1,0) [0|127] "Percent"  APIM,APIM_CDC,APIM_CIM,APIM_CISM
 SG_ SeatLmbrUpPsgr_Pc_Actl : 38|7@0+ (1,0) [0|127] "Percent"  APIM,APIM_CDC,APIM_CIM,APIM_CISM
 SG_ SeatSrvcPsngr_D_Arb : 41|2@0+ (1,0) [0|3] "SED" Vector__XXX
 SG_ StmsSrvcIdPsng_No_Actl : 44|3@0+ (1,0) [0|7] "unitless" Vector__XXX
 SG_ SeatSrvcIdPsngr_No_Act : 47|3@0+ (1,0) [0|7] "unitless" Vector__XXX
 SG_ StmsPtrnPsngr_D_Stat : 51|4@0+ (1,0) [0|15] "SED" Vector__XXX
 SG_ SeatSrvcPsngr_D_Res : 55|4@0+ (1,0) [0|15] "SED" Vector__XXX
 SG_ StmsSrvcPsngr_D_Res : 59|4@0+ (1,0) [0|15] "SED" Vector__XXX
 SG_ StmsSrvcPsngr_D_Arb : 61|2@0+ (1,0) [0|3] "SED" Vector__XXX
 SG_ StmsIntnsPsngr_D_Stat : 63|2@0+ (1,0) [0|3] "SED" Vector__XXX

BO_ 844 MassageSeat_Stat1_HS3: 8 GWM
 SG_ SeatAirAmb_P_Actl : 7|16@0+ (0.01,0) [0|655.35] "KiloPascal"  APIM,APIM_CDC,APIM_CIM,APIM_CISM
 SG_ StmsLmbrDrv_D_Stat : 17|2@0+ (1,0) [0|3] "SED"  APIM,APIM_CDC,APIM_CIM,APIM_CISM
 SG_ StmsCshnDrv_D_Stat : 19|2@0+ (1,0) [0|3] "SED"  APIM,APIM_CDC,APIM_CIM,APIM_CISM
 SG_ SeatPDrv_B_Stat : 20|1@0+ (1,0) [0|1] "SED"  APIM,APIM_CDC,APIM_CIM,APIM_CISM
 SG_ SeatFnDrv_D_Stat : 23|3@0+ (1,0) [0|7] "SED"  APIM,APIM_CDC,APIM_CIM,APIM_CISM
 SG_ SeatMasgDrv_D_Stat : 27|4@0+ (1,0) [0|15] "SED"  APIM,APIM_CDC,APIM_CIM,APIM_CISM
 SG_ SeatIntnsDrv_D_Stat : 30|3@0+ (1,0) [0|7] "SED"  APIM,APIM_CDC,APIM_CIM,APIM_CISM
 SG_ SeatSwtchDrv_B_Stat : 31|1@0+ (1,0) [0|1] "SED"  APIM,APIM_CDC,APIM_CIM,APIM_CISM
 SG_ StmsMduleDrv_D_Stat : 39|2@0+ (1,0) [0|3] "SED"  APIM,APIM_CDC,APIM_CIM,APIM_CISM

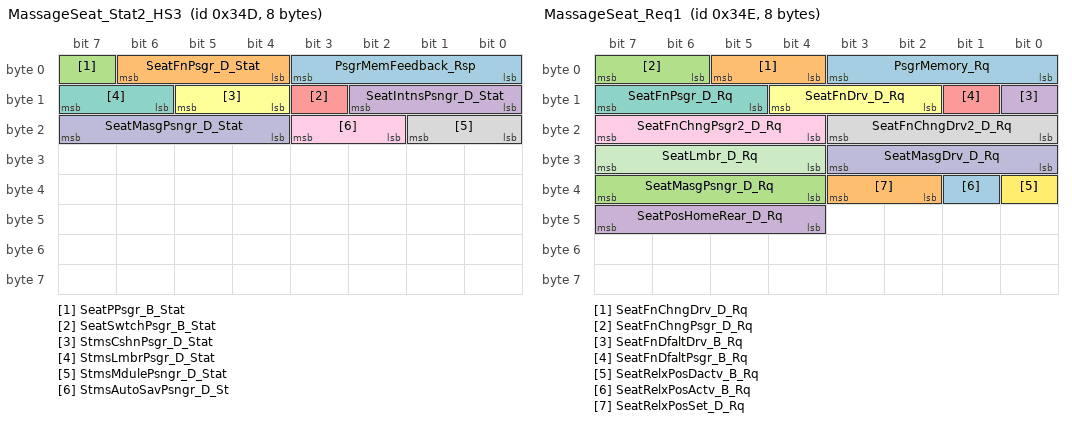
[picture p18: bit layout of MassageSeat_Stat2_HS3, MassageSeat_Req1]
BO_ 845 MassageSeat_Stat2_HS3: 8 GWM
 SG_ PsgrMemFeedback_Rsp : 3|4@0+ (1,0) [0|15] "SED"  APIM,APIM_CDC,APIM_CIM,APIM_CISM
 SG_ SeatFnPsgr_D_Stat : 6|3@0+ (1,0) [0|7] "SED"  APIM,APIM_CDC,APIM_CIM,APIM_CISM
 SG_ SeatPPsgr_B_Stat : 7|1@0+ (1,0) [0|1] "SED"  APIM,APIM_CDC,APIM_CIM,APIM_CISM
 SG_ SeatIntnsPsngr_D_Stat : 10|3@0+ (1,0) [0|7] "SED"  APIM,APIM_CDC,APIM_CIM,APIM_CISM
 SG_ SeatSwtchPsgr_B_Stat : 11|1@0+ (1,0) [0|1] "SED"  APIM,APIM_CDC,APIM_CIM,APIM_CISM
 SG_ StmsCshnPsgr_D_Stat : 13|2@0+ (1,0) [0|3] "SED"  APIM,APIM_CDC,APIM_CIM,APIM_CISM
 SG_ StmsLmbrPsgr_D_Stat : 15|2@0+ (1,0) [0|3] "SED"  APIM,APIM_CDC,APIM_CIM,APIM_CISM
 SG_ StmsMdulePsngr_D_Stat : 17|2@0+ (1,0) [0|3] "SED"  APIM,APIM_CDC,APIM_CIM,APIM_CISM
 SG_ StmsAutoSavPsngr_D_St : 19|2@0+ (1,0) [0|3] "SED"  APIM_CDC,APIM_CIM
 SG_ SeatMasgPsngr_D_Stat : 23|4@0+ (1,0) [0|15] "SED"  APIM,APIM_CDC,APIM_CIM,APIM_CISM

BO_ 846 MassageSeat_Req1: 8 APIM_CDC
 SG_ PsgrMemory_Rq : 3|4@0+ (1,0) [0|15] "SED"  GWM
 SG_ SeatFnChngDrv_D_Rq : 5|2@0+ (1,0) [0|3] "SED"  GWM
 SG_ SeatFnChngPsgr_D_Rq : 7|2@0+ (1,0) [0|3] "SED"  GWM
 SG_ SeatFnDfaltDrv_B_Rq : 8|1@0+ (1,0) [0|1] "SED"  GWM
 SG_ SeatFnDfaltPsgr_B_Rq : 9|1@0+ (1,0) [0|1] "SED"  GWM
 SG_ SeatFnDrv_D_Rq : 12|3@0+ (1,0) [0|7] "SED"  GWM
 SG_ SeatFnPsgr_D_Rq : 15|3@0+ (1,0) [0|7] "SED"  GWM
 SG_ SeatFnChngDrv2_D_Rq : 19|4@0+ (1,0) [0|15] "SED"  GWM
 SG_ SeatFnChngPsgr2_D_Rq : 23|4@0+ (1,0) [0|15] "SED"  GWM
 SG_ SeatMasgDrv_D_Rq : 27|4@0+ (1,0) [0|15] "SED"  GWM
 SG_ SeatLmbr_D_Rq : 31|4@0+ (1,0) [0|15] "SED"  GWM
 SG_ SeatRelxPosDactv_B_Rq : 32|1@0+ (1,0) [0|1] "SED"  GWM
 SG_ SeatRelxPosActv_B_Rq : 33|1@0+ (1,0) [0|1] "SED"  GWM
 SG_ SeatRelxPosSet_D_Rq : 35|2@0+ (1,0) [0|3] "SED"  GWM
 SG_ SeatMasgPsngr_D_Rq : 39|4@0+ (1,0) [0|15] "SED"  GWM
 SG_ SeatPosHomeRear_D_Rq : 47|4@0+ (1,0) [0|15] "SED"  GWM

BO_ 848 RestraintsData: 8 APIM_CDC
 SG_ RILStat : 7|2@0+ (1,0) [0|3] "SED"  GWM

BO_ 851 IPC_Consumption: 8 APIM_CDC
 SG_ ConsAvgTrip_No_Dsply : 35|12@0+ (1,0) [0|4095] "%"  GWM
 SG_ ConsLongTerm_No_Dsply : 51|12@0+ (1,0) [0|4095] "%"  GWM
 SG_ ConsUnitIPC_D_Dsply : 55|4@0+ (1,0) [0|15] "SED"  APIM,APIM_CISM,GWM

BO_ 861 Clmt_Button_Stat3_HS3: 8 GWM
 SG_ Rr_AUTO_Btn_Stt : 1|2@0+ (1,0) [0|3] "SED"  APIM,APIM_CDC,APIM_CIM,APIM_CISM,RACM_RCIM
 SG_ Rr_On_Indicator : 2|1@0+ (1,0) [0|1] "SED"  APIM,APIM_CDC,APIM_CIM,APIM_CISM,RACM_RCIM
 SG_ CC_Rr_Stat_User_Adj : 7|4@0+ (1,0) [0|15] "SED"  APIM,APIM_CDC,APIM_CIM,APIM_CISM,RACM_RCIM
 SG_ Rr_Floor_Btn_Stt : 9|2@0+ (1,0) [0|3] "SED"  APIM,APIM_CDC,APIM_CIM,APIM_CISM,RACM_RCIM
 SG_ Rr_Control_Btn_Stt : 11|2@0+ (1,0) [0|3] "SED"  APIM,APIM_CDC,APIM_CIM,APIM_CISM,RACM_RCIM
 SG_ Rr_Blower_Indicate : 15|4@0+ (1,0) [0|15] "SED"  APIM,APIM_CDC,APIM_CIM,APIM_CISM,RACM_RCIM
 SG_ Rr_RH_Cond_Seat_Stat : 18|3@0+ (1,0) [0|7] "SED"  APIM,APIM_CDC,APIM_CIM,APIM_CISM,RACM_RCIM
 SG_ Rr_LH_Cond_Seat_Stat : 21|3@0+ (1,0) [0|7] "SED"  APIM,APIM_CDC,APIM_CIM,APIM_CISM,RACM_RCIM
 SG_ Rr_LH_Cld_Seat_Btn_Stt : 23|2@0+ (1,0) [0|3] "SED"  APIM,APIM_CDC,APIM_CIM,APIM_CISM,RACM_RCIM
 SG_ Rr_LHS_Set_Temp_Dig2 : 25|4@0+ (1,0) [0|15] "SED"  APIM,APIM_CDC,APIM_CIM,APIM_CISM,RACM_RCIM
 SG_ Rr_LHS_Set_Temp_Dig1 : 29|4@0+ (1,0) [0|15] "SED"  APIM,APIM_CDC,APIM_CIM,APIM_CISM,RACM_RCIM
 SG_ Rr_LH_Htd_Seat_Btn_Stt : 31|2@0+ (1,0) [0|3] "SED"  APIM,APIM_CDC,APIM_CIM,APIM_CISM,RACM_RCIM
 SG_ Rr_Pnl_Flr_Btn_Stt : 33|2@0+ (1,0) [0|3] "SED"  APIM,APIM_CDC,APIM_CIM,APIM_CISM,RACM_RCIM
 SG_ Rr_Panel_Btn_Stt : 35|2@0+ (1,0) [0|3] "SED"  APIM,APIM_CDC,APIM_CIM,APIM_CISM,RACM_RCIM
 SG_ Rr_LHS_Set_Temp_Dig3 : 37|2@0+ (1,0) [0|3] "SED"  APIM,APIM_CDC,APIM_CIM,APIM_CISM,RACM_RCIM
 SG_ Rr_Set_Temp_Units : 41|2@0+ (1,0) [0|3] "SED"  APIM,APIM_CDC,APIM_CIM,APIM_CISM,RACM_RCIM
 SG_ Rr_RHS_Set_Temp_Dig3 : 43|2@0+ (1,0) [0|3] "SED"  APIM,APIM_CDC,APIM_CIM,APIM_CISM,RACM_RCIM
 SG_ Rr_RH_Htd_Seat_Btn_Stt : 45|2@0+ (1,0) [0|3] "SED"  APIM,APIM_CDC,APIM_CIM,APIM_CISM,RACM_RCIM
 SG_ Rr_RH_Cld_Seat_Btn_Stt : 47|2@0+ (1,0) [0|3] "SED"  APIM,APIM_CDC,APIM_CIM,APIM_CISM,RACM_RCIM
 SG_ Rr_RHS_Set_Temp_Dig2 : 51|4@0+ (1,0) [0|15] "SED"  APIM,APIM_CDC,APIM_CIM,APIM_CISM,RACM_RCIM
 SG_ Rr_RHS_Set_Temp_Dig1 : 55|4@0+ (1,0) [0|15] "SED"  APIM,APIM_CDC,APIM_CIM,APIM_CISM,RACM_RCIM
 SG_ Rr_Power_Btn_Stt : 57|2@0+ (1,0) [0|3] "SED"  APIM,APIM_CDC,APIM_CIM,APIM_CISM,RACM_RCIM
 SG_ Rr_Temp_Detents : 63|6@0+ (1,0) [0|63] "SED"  APIM,APIM_CDC,APIM_CIM,APIM_CISM,RACM_RCIM

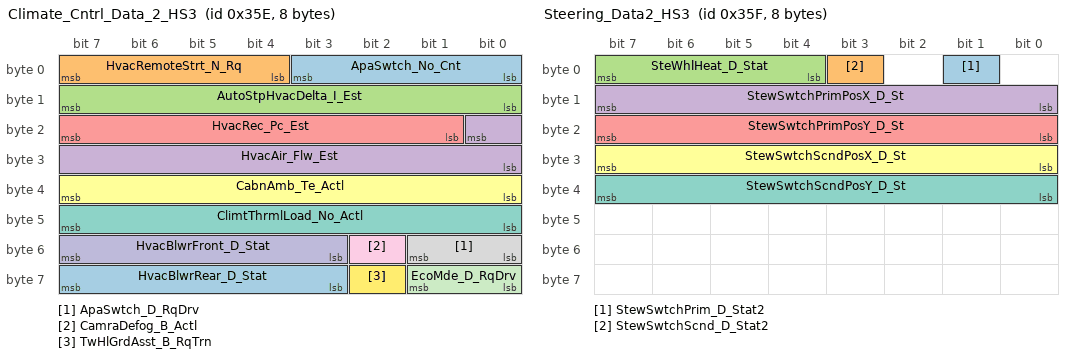
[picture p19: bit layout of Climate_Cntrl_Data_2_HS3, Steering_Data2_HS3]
BO_ 862 Climate_Cntrl_Data_2_HS3: 8 GWM
 SG_ ApaSwtch_No_Cnt : 3|4@0+ (1,0) [0|15] "unitless" Vector__XXX
 SG_ HvacRemoteStrt_N_Rq : 7|4@0+ (100,450) [450|1950] "RPM" Vector__XXX
 SG_ AutoStpHvacDelta_I_Est : 15|8@0+ (1,-192) [-192|63] "ampere" Vector__XXX
 SG_ HvacAir_Flw_Est : 16|9@0+ (0.5,0) [0|255.5] "liter/second" Vector__XXX
 SG_ HvacRec_Pc_Est : 23|7@0+ (1,0) [0|127] "percent" Vector__XXX
 SG_ CabnAmb_Te_Actl : 39|8@0+ (0.5,-57) [-57|70.5] "degC"  ACM,APIM,APIM_CDC,APIM_CIM,APIM_CISM,GWM,WCM,WCMB,WCMC
 SG_ ClimtThrmlLoad_No_Actl : 47|8@0+ (1,0) [0|255] "unitless" Vector__XXX
 SG_ ApaSwtch_D_RqDrv : 49|2@0+ (1,0) [0|3] "SED" Vector__XXX
 SG_ CamraDefog_B_Actl : 50|1@0+ (1,0) [0|1] "SED" Vector__XXX
 SG_ HvacBlwrFront_D_Stat : 55|5@0+ (1,0) [0|31] "SED"  APIM,APIM_CIM,APIM_CISM,WCM,WCMB,WCMC
 SG_ EcoMde_D_RqDrv : 57|2@0+ (1,0) [0|3] "SED" Vector__XXX
 SG_ TwHlGrdAsst_B_RqTrn : 58|1@0+ (1,0) [0|1] "SED" Vector__XXX
 SG_ HvacBlwrRear_D_Stat : 63|5@0+ (1,0) [0|31] "SED"  APIM,APIM_CIM,APIM_CISM,WCM,WCMB,WCMC

BO_ 863 Steering_Data2_HS3: 8 GWM
 SG_ StewSwtchPrim_D_Stat2 : 1|1@0+ (1,0) [0|1] "SED"  APIM_CDC,APIM_CIM
 SG_ StewSwtchScnd_D_Stat2 : 3|1@0+ (1,0) [0|1] "SED"  APIM_CDC,APIM_CIM
 SG_ SteWhlHeat_D_Stat : 7|4@0+ (1,0) [0|15] "SED" Vector__XXX
 SG_ StewSwtchPrimPosX_D_St : 15|8@0+ (1,0) [0|255] "SED"  APIM_CDC,APIM_CIM
 SG_ StewSwtchPrimPosY_D_St : 23|8@0+ (1,0) [0|255] "SED"  APIM_CDC,APIM_CIM
 SG_ StewSwtchScndPosX_D_St : 31|8@0+ (1,0) [0|255] "SED"  APIM_CDC,APIM_CIM
 SG_ StewSwtchScndPosY_D_St : 39|8@0+ (1,0) [0|255] "SED"  APIM_CDC,APIM_CIM

BO_ 864 Clmt_Button_Stat1_HS3: 8 GWM
 SG_ Dual_Button_Stt : 1|2@0+ (1,0) [0|3] "SED"  APIM,APIM_CDC,APIM_CIM,APIM_CISM,HUD_ADV,IPC
 SG_ Defrost_Btn_Stt : 3|2@0+ (1,0) [0|3] "SED"  APIM,APIM_CDC,APIM_CIM,APIM_CISM,IPC
 SG_ Auto_Recirc_Btn_Stt : 5|2@0+ (1,0) [0|3] "SED"  IPC
 SG_ AC_Btn_Stt : 7|2@0+ (1,0) [0|3] "SED"  APIM,APIM_CDC,APIM_CIM,APIM_CISM,HUD_ADV,IPC
 SG_ LHS_Cond_Seat_Status : 10|3@0+ (1,0) [0|7] "SED"  APIM,APIM_CDC,APIM_CIM,APIM_CISM,HUD_ADV,IPC
 SG_ CC_Fr_Btn_User_Adj : 15|5@0+ (1,0) [0|31] "SED"  APIM,APIM_CDC,APIM_CIM,APIM_CISM,HUD_ADV
 SG_ Front_Power_Btn_Stt : 17|2@0+ (1,0) [0|3] "SED"  APIM,APIM_CDC,APIM_CIM,APIM_CISM,HUD_ADV,IPC
 SG_ Front_AUTO_Label : 19|2@0+ (1,0) [0|3] "SED"  APIM,APIM_CDC,APIM_CIM,APIM_CISM,HUD_ADV,IPC
 SG_ Front_AUTO_Btn_Stt : 21|2@0+ (1,0) [0|3] "SED"  APIM,APIM_CDC,APIM_CIM,APIM_CISM,HUD_ADV,IPC
 SG_ Floor_Btn_Stt : 23|2@0+ (1,0) [0|3] "SED"  APIM,APIM_CDC,APIM_CIM,APIM_CISM,HUD_ADV,IPC
 SG_ LHS_Cld_Seat_Btn_Stt : 25|2@0+ (1,0) [0|3] "SED"  APIM,APIM_CDC,APIM_CIM,APIM_CISM,IPC
 SG_ Htd_Strg_Whl_Status : 27|2@0+ (1,0) [0|3] "SED"  APIM,APIM_CDC,APIM_CIM,APIM_CISM,HUD_ADV,IPC
 SG_ Htd_Strg_Whl_Btn_Stt : 29|2@0+ (1,0) [0|3] "SED"  APIM,APIM_CDC,APIM_CIM,APIM_CISM,IPC
 SG_ Htd_Frt_Wsh_Btn_Stt : 31|2@0+ (1,0) [0|3] "SED"  APIM,APIM_CDC,APIM_CIM,APIM_CISM,HUD_ADV,IPC
 SG_ My_Temp_Btn_Stt : 33|2@0+ (1,0) [0|3] "SED"  APIM,APIM_CDC,APIM_CIM,APIM_CISM,HUD_ADV,IPC
 SG_ Max_Defrost_Btn_Stt : 35|2@0+ (1,0) [0|3] "SED"  APIM,APIM_CDC,APIM_CIM,APIM_CISM,HUD_ADV,IPC
 SG_ Max_AC_Btn_Stt : 37|2@0+ (1,0) [0|3] "SED"  APIM,APIM_CDC,APIM_CIM,APIM_CISM,HUD_ADV,IPC
 SG_ LHS_Htd_Seat_Btn_Stt : 39|2@0+ (1,0) [0|3] "SED"  APIM,APIM_CDC,APIM_CIM,APIM_CISM,IPC
 SG_ Recirc_Btn_Stt : 41|2@0+ (1,0) [0|3] "SED"  APIM,APIM_CDC,APIM_CIM,APIM_CISM,HUD_ADV,IPC
 SG_ Rear_Defrost_Btn_Stt : 43|2@0+ (1,0) [0|3] "SED"  APIM,APIM_CDC,APIM_CIM,APIM_CISM,HUD_ADV,IPC
 SG_ Panel_Btn_Stt : 45|2@0+ (1,0) [0|3] "SED"  APIM,APIM_CDC,APIM_CIM,APIM_CISM,HUD_ADV,IPC
 SG_ Outside_Btn_Stt : 47|2@0+ (1,0) [0|3] "SED"  IPC
 SG_ RearMnu_Buttn_Stat : 48|1@0+ (1,0) [0|1] "SED"  APIM,APIM_CDC,APIM_CIM,APIM_CISM
 SG_ FrontMnu_Buttn_Stat : 49|1@0+ (1,0) [0|1] "SED"  APIM,APIM_CDC,APIM_CIM,APIM_CISM
 SG_ Windscreen_Btn_Stt : 51|2@0+ (1,0) [0|3] "SED"  APIM,APIM_CDC,APIM_CIM,APIM_CISM,IPC
 SG_ RHS_Htd_Seat_Btn_Stt : 53|2@0+ (1,0) [0|3] "SED"  APIM_CDC,APIM_CIM,IPC
 SG_ RHS_Cld_Seat_Btn_Stt : 55|2@0+ (1,0) [0|3] "SED"  APIM,APIM_CDC,APIM_CIM,APIM_CISM,IPC
 SG_ DrvrFcsdMde_Btn_Stt : 57|2@0+ (1,0) [0|3] "SED"  APIM,APIM_CDC,APIM_CIM,APIM_CISM
 SG_ MdeMnu_Buttn_Stat : 58|1@0+ (1,0) [0|1] "SED"  APIM,APIM_CDC,APIM_CIM,APIM_CISM
 SG_ Front_AUTO_Blwr_Lvl : 60|2@0+ (1,0) [0|3] "SED"  APIM,APIM_CDC,APIM_CIM,APIM_CISM
 SG_ RHS_Cond_Seat_Status : 63|3@0+ (1,0) [0|7] "SED"  APIM,APIM_CDC,APIM_CIM,APIM_CISM,IPC

BO_ 865 Clmt_Button_Stat2_HS3: 8 GWM
 SG_ EATC_LHS_Units : 1|2@0+ (1,0) [0|3] "SED"  APIM,APIM_CDC,APIM_CIM,APIM_CISM,IPC
 SG_ RHS_Temp_Display_Digit3 : 3|2@0+ (1,0) [0|3] "SED"  APIM,APIM_CDC,APIM_CIM,APIM_CISM,IPC
 SG_ CC_Fr_Stat_User_Adj : 6|3@0+ (1,0) [0|7] "SED"  APIM_CDC,GENERIC,HUD_ADV
 SG_ LHS_Temp_Display_Digit3 : 9|2@0+ (1,0) [0|3] "SED"  APIM,APIM_CDC,APIM_CIM,APIM_CISM,IPC
 SG_ Front_Blower_Indicate : 13|4@0+ (1,0) [0|15] "SED"  APIM,APIM_CDC,APIM_CIM,APIM_CISM,HUD_ADV,IPC
 SG_ EATC_RHS_Units : 15|2@0+ (1,0) [0|3] "SED"  APIM,APIM_CDC,APIM_CIM,APIM_CISM,IPC
 SG_ LHS_Temp_Display_Digit1 : 23|8@0+ (1,0) [0|255] "ASCII"  APIM,APIM_CDC,APIM_CIM,APIM_CISM,IPC
 SG_ LHS_Temp_Display_Digit2 : 31|8@0+ (1,0) [0|255] "ASCII"  APIM,APIM_CDC,APIM_CIM,APIM_CISM,IPC
 SG_ RHS_Temp_Display_Digit1 : 39|8@0+ (1,0) [0|255] "ASCII"  APIM,APIM_CDC,APIM_CIM,APIM_CISM,IPC
 SG_ RHS_Temp_Display_Digit2 : 47|8@0+ (1,0) [0|255] "ASCII"  APIM,APIM_CDC,APIM_CIM,APIM_CISM,IPC
 SG_ SelDrvMdeSwtch_D_Stat2 : 51|2@0+ (1,0) [0|3] "SED"  APIM,APIM_CDC
 SG_ EngExhMdeQuiet_B_RqDrv : 52|1@0+ (1,0) [0|1] "SED"  APIM_CDC,APIM_CIM,IPC
 SG_ LnchCtlSys_B_RqDrv : 53|1@0+ (1,0) [0|1] "SED"  APIM_CDC,APIM_CIM,IPC
 SG_ SteEffortButtn_B_Stat : 54|1@0+ (1,0) [0|1] "SED"  APIM_CDC,APIM_CIM,IPC
 SG_ SelDrvMdeButtn_B_Stat : 55|1@0+ (1,0) [0|1] "SED"  APIM_CDC
 SG_ RHS_Auto_Seat_Btn_Stt : 57|2@0+ (1,0) [0|3] "SED"  APIM,APIM_CDC,APIM_CIM,APIM_CISM,FCIMB
 SG_ LHS_Auto_Seat_Btn_Stt : 59|2@0+ (1,0) [0|3] "SED"  APIM,APIM_CDC,APIM_CIM,APIM_CISM,FCIMB
 SG_ Dsp_RotAddrBtnEv_St : 63|4@0+ (1,0) [0|15] "SED"  APIM,APIM_CDC,APIM_CIM,APIM_CISM

BO_TX_BU_ 726 : ACM,APIM_CIM,APIM_CISM;
BO_TX_BU_ 728 : ACM,APIM_CIM,APIM_CISM;
BO_TX_BU_ 729 : ACM,APIM_CIM,APIM_CISM;
BO_TX_BU_ 732 : ACM,APIM_CIM,APIM_CISM;
BO_TX_BU_ 734 : ACM,APIM_CIM,APIM_CISM;
BO_TX_BU_ 736 : APIM,APIM_CDC,APIM_CISM;
BO_TX_BU_ 737 : APIM,APIM_CDC,APIM_CIM,APIM_CISM;
BO_TX_BU_ 739 : APIM,APIM_CDC,APIM_CIM,APIM_CISM;
BO_TX_BU_ 750 : APIM,APIM_CDC,APIM_CIM,APIM_CISM;
BO_TX_BU_ 753 : APIM,APIM_CDC,APIM_CIM,APIM_CISM;
BO_TX_BU_ 754 : ACM,APIM_CIM,APIM_CISM;
BO_TX_BU_ 756 : APIM_CDC,APIM_CIM,APIM_CISM,IPC;
BO_TX_BU_ 757 : ACM,APIM_CIM,APIM_CISM;
BO_TX_BU_ 758 : ACM,APIM_CISM;
BO_TX_BU_ 759 : ACM,APIM_CIM,APIM_CISM;
BO_TX_BU_ 760 : ACM,APIM_CISM;
BO_TX_BU_ 761 : ACM,APIM_CISM;
BO_TX_BU_ 764 : APIM,APIM_CDC,APIM_CISM;
BO_TX_BU_ 765 : APIM_CDC,APIM_CIM,APIM_CISM,IPC;
BO_TX_BU_ 766 : APIM,APIM_CISM;
BO_TX_BU_ 778 : APIM_CDC,APIM_CIM,IPC;
BO_TX_BU_ 783 : APIM_CDC,APIM_CIM,APIM_CISM,IPC;
BO_TX_BU_ 789 : APIM_CDC,APIM_CIM,APIM_CISM,IPC;
BO_TX_BU_ 791 : APIM_CDC,APIM_CIM,APIM_CISM,IPC;
BO_TX_BU_ 792 : APIM_CDC,APIM_CIM,APIM_CISM,IPC;
BO_TX_BU_ 801 : ACM,APIM,APIM_CDC,APIM_CISM;
BO_TX_BU_ 802 : APIM_CDC,IPC;
BO_TX_BU_ 803 : APIM_CDC,IPC;
BO_TX_BU_ 805 : APIM_CDC,APIM_CIM,APIM_CISM,IPC;
BO_TX_BU_ 811 : APIM,APIM_CDC,APIM_CIM,APIM_CISM;
BO_TX_BU_ 816 : APIM,APIM_CDC,APIM_CIM,APIM_CISM;
BO_TX_BU_ 838 : APIM_CDC,APIM_CIM,APIM_CISM,IPC;
BO_TX_BU_ 840 : APIM_CDC,APIM_CIM,APIM_CISM,IPC;
BO_TX_BU_ 846 : APIM,APIM_CDC,APIM_CIM,APIM_CISM;
BO_TX_BU_ 848 : APIM_CDC,APIM_CIM,APIM_CISM,IPC;
BO_TX_BU_ 851 : APIM_CDC,APIM_CIM,APIM_CISM,IPC;
CM_ BO_ 739 "FCDIM Tx";
CM_ BO_ 753 "APIM Tx";
CM_ BO_ 756 "IPC_Chime2";
CM_ BO_ 827 "MSGDCR 000176 HUD_ADV requested EP 60ms.   ";
CM_ BO_ 828 "Set GenSigSendType = NoSigSendType (Cyclic) for the following signals, D.Card 3/31/08
Driver_Lock_Sw_Stat
";
CM_ BO_ 846 "APIM Tx";
BA_DEF_ BO_  "E2EDataId" INT 0 65535;
BA_DEF_ BO_  "E2EDataLength" INT 0 512;
BA_DEF_ BO_  "E2EProfile" STRING ;
BA_DEF_ BO_  "GenMsgRoutingTimeoutTime" INT 0 5000;
BA_DEF_ BO_  "MessageGateway" ENUM  "No","Yes";
BA_DEF_ BO_  "VFrameFormat" ENUM  "StandardCAN","ExtendedCAN","reserved","reserved","reserved","reserved","reserved","reserved","reserved","reserved","reserved","reserved","reserved","reserved","StandardCAN_FD","ExtendedCAN_FD";
BA_DEF_ SG_  "ECGUsedRxSignal" ENUM  "No","Yes";
BA_DEF_ SG_  "ECGUsedTxSignal" ENUM  "No","Yes";
BA_DEF_ SG_  "GenSigInactiveValue" INT 0 100000;
BA_DEF_ SG_  "GenSigSendType" ENUM  "Cyclic","OnWrite","vector_leerstring","OnChange","vector_leerstring","IfActive","vector_leerstring","NoSigSendType";
BA_DEF_ BO_  "NetworkInitialization" ENUM  "No","Yes";
BA_DEF_ SG_  "GenSigStartValue" HEX 0 268435455;
BA_DEF_ BO_  "GenMsgStartDelayTime" INT 0 10000;
BA_DEF_ SG_  "WakeupSignal" ENUM  "No","Yes";
BA_DEF_ BO_  "GenMsgNrOfRepetition" INT 0 100;
BA_DEF_ BO_  "GenMsgDelayTime" INT 0 1000;
BA_DEF_ BO_  "GenMsgCycleTime" INT 0 100000;
BA_DEF_ BO_  "GenMsgSendType" ENUM  "FixedPeriodic","Event","EnabledPeriodic","NotUsed","NotUsed","EventPeriodic","NotUsed","NotUsed","NoMsgSendType";
BA_DEF_ BO_  "FrameRouting" STRING ;
BA_DEF_ BO_  "TpTxIndex" INT 0 536870911;
BA_DEF_ BO_  "OvtpPushApplication" ENUM  "FALSE","TRUE";
BA_DEF_ BO_  "SCP_FreshnessValueLength" INT 0 512;
BA_DEF_ BO_  "SCP_FreshnessValueTxLength" INT 0 512;
BA_DEF_ BO_  "SCP_AuthInfoTxLength" INT 0 512;
BA_DEF_ BO_  "NmAsrMessage" ENUM  "No","Yes";
BA_DEF_ BO_  "DiagState" ENUM  "No","Yes";
BA_DEF_ BO_  "DiagRequest" ENUM  "No","Yes";
BA_DEF_ BO_  "DiagResponse" ENUM  "No","Yes";
BA_DEF_ BO_  "GenMsgILSupport" ENUM  "No","Yes";
BA_DEF_ SG_  "SystemSignalLongSymbol" STRING ;
BA_DEF_ BO_  "SystemMessageLongSymbol" STRING ;
BA_DEF_DEF_  "E2EDataId" 1;
BA_DEF_DEF_  "E2EDataLength" 0;
BA_DEF_DEF_  "E2EProfile" "";
BA_DEF_DEF_  "GenMsgRoutingTimeoutTime" 0;
BA_DEF_DEF_  "MessageGateway" "No";
BA_DEF_DEF_  "VFrameFormat" "StandardCAN";
BA_DEF_DEF_  "ECGUsedRxSignal" "No";
BA_DEF_DEF_  "ECGUsedTxSignal" "No";
BA_DEF_DEF_  "GenSigInactiveValue" 0;
BA_DEF_DEF_  "GenSigSendType" "NoSigSendType";
BA_DEF_DEF_  "NetworkInitialization" "Yes";
BA_DEF_DEF_  "GenSigStartValue" 0;
BA_DEF_DEF_  "GenMsgStartDelayTime" 0;
BA_DEF_DEF_  "WakeupSignal" "No";
BA_DEF_DEF_  "GenMsgNrOfRepetition" 1;
BA_DEF_DEF_  "GenMsgDelayTime" 20;
BA_DEF_DEF_  "GenMsgCycleTime" 0;
BA_DEF_DEF_  "GenMsgSendType" "NoMsgSendType";
BA_DEF_DEF_  "FrameRouting" "";
BA_DEF_DEF_  "TpTxIndex" 0;
BA_DEF_DEF_  "OvtpPushApplication" "FALSE";
BA_DEF_DEF_  "SCP_FreshnessValueLength" 64;
BA_DEF_DEF_  "SCP_FreshnessValueTxLength" 11;
BA_DEF_DEF_  "SCP_AuthInfoTxLength" 53;
BA_DEF_DEF_  "NmAsrMessage" "No";
BA_DEF_DEF_  "DiagState" "No";
BA_DEF_DEF_  "DiagRequest" "No";
BA_DEF_DEF_  "DiagResponse" "No";
BA_DEF_DEF_  "GenMsgILSupport" "Yes";
BA_DEF_DEF_  "SystemSignalLongSymbol" "";
BA_DEF_DEF_  "SystemMessageLongSymbol" "";
BA_ "GenMsgSendType" BO_ 726 5;
BA_ "GenMsgCycleTime" BO_ 726 1000;
BA_ "GenMsgSendType" BO_ 727 5;
BA_ "GenMsgCycleTime" BO_ 727 1000;
BA_ "GenMsgSendType" BO_ 728 5;
BA_ "GenMsgCycleTime" BO_ 728 1000;
BA_ "GenMsgSendType" BO_ 729 5;
BA_ "GenMsgCycleTime" BO_ 729 1000;
BA_ "GenMsgSendType" BO_ 732 5;
BA_ "GenMsgCycleTime" BO_ 732 1000;
BA_ "GenMsgSendType" BO_ 734 5;
BA_ "GenMsgCycleTime" BO_ 734 1000;
BA_ "GenMsgSendType" BO_ 736 5;
BA_ "GenMsgCycleTime" BO_ 736 1000;
BA_ "TpTxIndex" BO_ 737 53;
BA_ "GenMsgSendType" BO_ 739 5;
BA_ "GenMsgCycleTime" BO_ 739 1000;
BA_ "GenMsgSendType" BO_ 740 5;
BA_ "GenMsgCycleTime" BO_ 740 1000;
BA_ "GenMsgSendType" BO_ 741 5;
BA_ "GenMsgCycleTime" BO_ 741 1000;
BA_ "GenMsgSendType" BO_ 744 5;
BA_ "GenMsgCycleTime" BO_ 744 1000;
BA_ "TpTxIndex" BO_ 745 53;
BA_ "GenMsgSendType" BO_ 746 5;
BA_ "GenMsgCycleTime" BO_ 746 1000;
BA_ "GenMsgSendType" BO_ 750 5;
BA_ "GenMsgCycleTime" BO_ 750 1000;
BA_ "GenMsgSendType" BO_ 753 5;
BA_ "GenMsgCycleTime" BO_ 753 1000;
BA_ "GenMsgSendType" BO_ 754 5;
BA_ "GenMsgCycleTime" BO_ 754 1000;
BA_ "GenMsgSendType" BO_ 756 5;
BA_ "GenMsgCycleTime" BO_ 756 1000;
BA_ "GenMsgSendType" BO_ 757 5;
BA_ "GenMsgCycleTime" BO_ 757 1000;
BA_ "GenMsgSendType" BO_ 758 5;
BA_ "GenMsgCycleTime" BO_ 758 1000;
BA_ "GenMsgSendType" BO_ 759 5;
BA_ "GenMsgCycleTime" BO_ 759 1000;
BA_ "GenMsgSendType" BO_ 760 5;
BA_ "GenMsgCycleTime" BO_ 760 1000;
BA_ "GenMsgSendType" BO_ 761 5;
BA_ "GenMsgCycleTime" BO_ 761 1000;
BA_ "GenMsgSendType" BO_ 764 5;
BA_ "GenMsgCycleTime" BO_ 764 1000;
BA_ "GenMsgSendType" BO_ 765 5;
BA_ "GenMsgCycleTime" BO_ 765 1000;
BA_ "GenMsgSendType" BO_ 766 5;
BA_ "GenMsgCycleTime" BO_ 766 1000;
BA_ "FrameRouting" BO_ 770 "FD1_CAN,0x302;";
BA_ "FrameRouting" BO_ 772 "FD3_CAN,0x304;";
BA_ "FrameRouting" BO_ 773 "FD3_CAN,0x305;MS1_CAN,0x305;";
BA_ "GenMsgSendType" BO_ 778 5;
BA_ "GenMsgCycleTime" BO_ 778 200;
BA_ "FrameRouting" BO_ 779 "MS2_CAN,0x30B;";
BA_ "FrameRouting" BO_ 780 "MS2_CAN,0x30C;";
BA_ "FrameRouting" BO_ 781 "MS2_CAN,0x30D;";
BA_ "GenMsgSendType" BO_ 783 5;
BA_ "GenMsgCycleTime" BO_ 783 1000;
BA_ "FrameRouting" BO_ 784 "MS2_CAN,0x310;";
BA_ "FrameRouting" BO_ 785 "FD1_CAN,0x311;";
BA_ "FrameRouting" BO_ 786 "FD1_CAN,0x312;";
BA_ "FrameRouting" BO_ 787 "MS2_CAN,0x313;MS1_CAN,0x313;";
BA_ "FrameRouting" BO_ 788 "FD1_CAN,0x314;";
BA_ "GenMsgSendType" BO_ 789 0;
BA_ "GenMsgCycleTime" BO_ 789 1000;
BA_ "GenMsgSendType" BO_ 791 5;
BA_ "GenMsgCycleTime" BO_ 791 1000;
BA_ "GenMsgSendType" BO_ 792 0;
BA_ "GenMsgCycleTime" BO_ 792 100;
BA_ "GenMsgSendType" BO_ 801 5;
BA_ "GenMsgCycleTime" BO_ 801 1000;
BA_ "GenMsgSendType" BO_ 802 5;
BA_ "GenMsgCycleTime" BO_ 802 1000;
BA_ "GenMsgSendType" BO_ 803 5;
BA_ "GenMsgCycleTime" BO_ 803 1000;
BA_ "GenMsgSendType" BO_ 804 5;
BA_ "GenMsgCycleTime" BO_ 804 1000;
BA_ "GenMsgSendType" BO_ 805 0;
BA_ "GenMsgCycleTime" BO_ 805 100;
BA_ "FrameRouting" BO_ 806 "MS1_CAN,0x326;";
BA_ "GenMsgSendType" BO_ 807 5;
BA_ "GenMsgCycleTime" BO_ 807 1000;
BA_ "GenMsgSendType" BO_ 810 5;
BA_ "GenMsgCycleTime" BO_ 810 1000;
BA_ "GenMsgSendType" BO_ 811 5;
BA_ "GenMsgCycleTime" BO_ 811 1000;
BA_ "GenMsgSendType" BO_ 812 5;
BA_ "GenMsgCycleTime" BO_ 812 1000;
BA_ "GenMsgSendType" BO_ 813 5;
BA_ "GenMsgCycleTime" BO_ 813 1000;
BA_ "GenMsgSendType" BO_ 816 5;
BA_ "GenMsgCycleTime" BO_ 816 1000;
BA_ "FrameRouting" BO_ 817 "FD1_CAN,0x331;";
BA_ "FrameRouting" BO_ 818 "FD3_CAN,0x332;";
BA_ "FrameRouting" BO_ 819 "FD3_CAN,0x333;";
BA_ "FrameRouting" BO_ 820 "FD1_CAN,0x334;FD3_CAN,0x334;";
BA_ "FrameRouting" BO_ 826 "FD3_CAN,0x33A;";
BA_ "FrameRouting" BO_ 827 "FD3_CAN,0x33B;";
BA_ "FrameRouting" BO_ 828 "FD3_CAN,0x33C;";
BA_ "FrameRouting" BO_ 831 "FD3_CAN,0x33F;";
BA_ "FrameRouting" BO_ 836 "MS1_CAN,0x344;";
BA_ "FrameRouting" BO_ 837 "FD1_CAN,0x345;HS2_CAN,0x345;";
BA_ "GenMsgSendType" BO_ 838 0;
BA_ "GenMsgCycleTime" BO_ 838 100;
BA_ "FrameRouting" BO_ 839 "MS1_CAN,0x347;";
BA_ "GenMsgSendType" BO_ 840 5;
BA_ "GenMsgCycleTime" BO_ 840 1000;
BA_ "FrameRouting" BO_ 841 "MS1_CAN,0x349;";
BA_ "FrameRouting" BO_ 842 "MS1_CAN,0x34A;";
BA_ "FrameRouting" BO_ 843 "MS1_CAN,0x34B;";
BA_ "FrameRouting" BO_ 844 "MS1_CAN,0x34C;";
BA_ "FrameRouting" BO_ 845 "MS1_CAN,0x34D;";
BA_ "GenMsgSendType" BO_ 846 5;
BA_ "GenMsgCycleTime" BO_ 846 1000;
BA_ "GenMsgSendType" BO_ 848 0;
BA_ "GenMsgCycleTime" BO_ 848 1000;
BA_ "GenMsgSendType" BO_ 851 5;
BA_ "GenMsgCycleTime" BO_ 851 1000;
BA_ "FrameRouting" BO_ 861 "MS1_CAN,0x357;";
BA_ "FrameRouting" BO_ 862 "MS1_CAN,0x35E;";
BA_ "FrameRouting" BO_ 863 "FD3_CAN,0x35F;";
BA_ "FrameRouting" BO_ 864 "MS1_CAN,0x355;";
BA_ "FrameRouting" BO_ 865 "MS1_CAN,0x356;";
BA_ "GenSigSendType" SG_ 726 ACU_SelectedPTYCodes_St 3;
BA_ "GenSigSendType" SG_ 726 ACU_AFJump_St 3;
BA_ "GenSigSendType" SG_ 726 ACU_TAMode_St 3;
BA_ "GenSigSendType" SG_ 726 ACU_NEWSMode_St 3;
BA_ "GenSigSendType" SG_ 727 ACU_LoadEjectMode_St 3;
BA_ "GenSigSendType" SG_ 728 PrplSnd_D_Stat 3;
BA_ "GenSigSendType" SG_ 728 ACU_CurrentStatFlags_St 3;
BA_ "GenSigSendType" SG_ 728 ACU_Volume_Up 1;
BA_ "GenSigSendType" SG_ 728 ACU_Volume_St 3;
BA_ "ECGUsedRxSignal" SG_ 728 ACU_Volume_St 1;
BA_ "GenSigSendType" SG_ 728 ACU_Mid_St 3;
BA_ "GenSigSendType" SG_ 728 ACU_RadioSeekMode_St 3;
BA_ "GenSigSendType" SG_ 728 ACU_AuxVolume_Up 1;
BA_ "GenSigSendType" SG_ 729 ACU_DSP_St 3;
BA_ "GenSigSendType" SG_ 729 ACU_Treble_St 3;
BA_ "GenSigSendType" SG_ 729 ACU_Bass_St 3;
BA_ "GenSigSendType" SG_ 729 ACU_Fader_St 3;
BA_ "GenSigSendType" SG_ 729 ACU_Balance_St 3;
BA_ "GenSigSendType" SG_ 729 ACU_NavCmdVolume_Up 3;
BA_ "GenSigSendType" SG_ 729 ACU_TAVolume_Up 3;
BA_ "GenSigSendType" SG_ 729 ACU_AVC_St 3;
BA_ "GenSigSendType" SG_ 729 ACU_PhoneVolume_Up 3;
BA_ "GenSigSendType" SG_ 729 ACU_Reg_St 3;
BA_ "GenSigSendType" SG_ 729 ACU_NavCmdVolume_St 3;
BA_ "GenSigSendType" SG_ 729 ACU_VoiceFBVolume_Up 3;
BA_ "GenSigSendType" SG_ 729 ACU_TAVolume_St 3;
BA_ "GenSigSendType" SG_ 729 ACU_DSPProgram_St 3;
BA_ "GenSigSendType" SG_ 729 ACU_PhoneVolume_St 3;
BA_ "GenSigSendType" SG_ 729 ACU_VoiceFBVolume_St 3;
BA_ "GenSigSendType" SG_ 732 ACU_FunctionStatus_St 3;
BA_ "GenSigSendType" SG_ 732 ACU_StorePreset_St 3;
BA_ "GenSigSendType" SG_ 732 ACU_VoiceCommand_St 3;
BA_ "ECGUsedRxSignal" SG_ 732 ACU_VoiceCommand_St 1;
BA_ "GenSigSendType" SG_ 734 ACU_CurrTURadioBand_St 3;
BA_ "GenSigSendType" SG_ 734 ACU_CurrTUServiceLink_St 3;
BA_ "GenSigSendType" SG_ 734 ACU_CurrTUDRService_St 3;
BA_ "GenSigSendType" SG_ 734 ACU_CurrTUSID_St 3;
BA_ "GenSigSendType" SG_ 734 ACU_CurrTUDABBlock_St 3;
BA_ "GenSigSendType" SG_ 734 ACU_ActServiceLink_St 3;
BA_ "GenSigSendType" SG_ 734 ACU_CurrTUDRService2_St 3;
BA_ "GenSigSendType" SG_ 736 VRM_IncCallOption_St 3;
BA_ "GenSigSendType" SG_ 736 BTInCallOptions_St 3;
BA_ "GenSigSendType" SG_ 736 TextMessage_Rsp 3;
BA_ "ECGUsedRxSignal" SG_ 737 APIM_ECG_Word_Tx 1;
BA_ "WakeupSignal" SG_ 739 HMI_HMIMode_St 1;
BA_ "GenSigSendType" SG_ 739 HMI_HMIMode_St 3;
BA_ "ECGUsedRxSignal" SG_ 739 HMI_HMIMode_St 1;
BA_ "GenSigSendType" SG_ 739 BptStrtStop_D_RqMnu 3;
BA_ "GenSigSendType" SG_ 739 BptMde_D_RqMnu 3;
BA_ "GenSigSendType" SG_ 739 EngExhMdeHrStrt_D_Rq 3;
BA_ "GenSigSendType" SG_ 739 OnbTrgtSocOvrrd_D_Rq 3;
BA_ "GenSigSendType" SG_ 739 Partial_Amp_Shutdown 3;
BA_ "GenSigSendType" SG_ 739 SeatOccChime_B_RqCancl 3;
BA_ "ECGUsedRxSignal" SG_ 739 SeatOccChime_B_RqCancl 1;
BA_ "GenSigSendType" SG_ 739 EngExhMdeHrEnbl_D_Rq 3;
BA_ "GenSigSendType" SG_ 739 EngExhMdeHrEnd_D_Rq 3;
BA_ "GenSigSendType" SG_ 739 VgfSet_D_Stat 3;
BA_ "ECGUsedRxSignal" SG_ 739 VgfSet_D_Stat 1;
BA_ "GenSigSendType" SG_ 739 VehHornOccAlrt_D_Stat 3;
BA_ "ECGUsedRxSignal" SG_ 739 VehHornOccAlrt_D_Stat 1;
BA_ "GenSigSendType" SG_ 739 SeatOccRear_D_Stat 3;
BA_ "ECGUsedRxSignal" SG_ 739 SeatOccRear_D_Stat 1;
BA_ "GenSigSendType" SG_ 739 BabySeatInUse_D_Stat 3;
BA_ "ECGUsedRxSignal" SG_ 739 BabySeatInUse_D_Stat 1;
BA_ "GenSigStartValue" SG_ 739 BptMnSoc_L_RqMnu 8190;
BA_ "GenSigSendType" SG_ 739 LostPKChirp_D_RqMnu 3;
BA_ "GenSigSendType" SG_ 739 SpeedChngChime_D_Rq 3;
BA_ "GenSigStartValue" SG_ 739 BptDly_T_RqMnu 62;
BA_ "GenSigSendType" SG_ 739 BptDly_T_RqMnu 3;
BA_ "GenSigStartValue" SG_ 739 OnbTrgtSocOvrrd_Pc_Rq 100;
BA_ "GenSigStartValue" SG_ 740 SndPersIndx_D_Stat 4;
BA_ "GenSigSendType" SG_ 740 SndPersIndx_D_Stat 3;
BA_ "ECGUsedRxSignal" SG_ 740 SndPersIndx_D_Stat 1;
BA_ "WakeupSignal" SG_ 740 SndPersSrvcId_No_Actl 1;
BA_ "GenSigSendType" SG_ 740 SndPersSrvcId_No_Actl 3;
BA_ "ECGUsedRxSignal" SG_ 740 SndPersSrvcId_No_Actl 1;
BA_ "GenSigSendType" SG_ 740 EmgcyAsstActv_D_Stat 3;
BA_ "GenSigSendType" SG_ 740 SndPersFeatCnt_No_Actl 3;
BA_ "ECGUsedRxSignal" SG_ 740 SndPersFeatCnt_No_Actl 1;
BA_ "GenSigSendType" SG_ 740 SndPersFeat_No_Actl 3;
BA_ "ECGUsedRxSignal" SG_ 740 SndPersFeat_No_Actl 1;
BA_ "GenSigSendType" SG_ 740 SndPersFeatVal_No_Actl 3;
BA_ "ECGUsedRxSignal" SG_ 740 SndPersFeatVal_No_Actl 1;
BA_ "GenSigSendType" SG_ 740 SndPersSrvc_D_Res 3;
BA_ "ECGUsedRxSignal" SG_ 740 SndPersSrvc_D_Res 1;
BA_ "GenSigSendType" SG_ 740 SndPersChng_D_Stat 3;
BA_ "ECGUsedRxSignal" SG_ 740 SndPersChng_D_Stat 1;
BA_ "GenSigSendType" SG_ 741 Con_USB_Shuffle_St 3;
BA_ "GenSigSendType" SG_ 741 Con_USB_FunctStatus_St 3;
BA_ "GenSigSendType" SG_ 741 Con_USB_OpMode_St 3;
BA_ "GenSigSendType" SG_ 741 Con_USB_IntroScan_St 3;
BA_ "GenSigSendType" SG_ 741 Con_iPod_FunctStatus_St 3;
BA_ "GenSigSendType" SG_ 741 Con_iPod_OpMode_St 3;
BA_ "GenSigSendType" SG_ 741 Con_iPod_Shuffle_St 3;
BA_ "GenSigSendType" SG_ 741 Con_iPod_Repeat_St 3;
BA_ "GenSigSendType" SG_ 741 Con_USB_Repeat_St 3;
BA_ "GenSigSendType" SG_ 741 Con_iPod_Error_St 3;
BA_ "GenSigSendType" SG_ 741 Con_USB_Error_St 3;
BA_ "GenSigSendType" SG_ 741 Con_ShowSWDLprogress_St 3;
BA_ "GenSigSendType" SG_ 741 Con_USB_Playtype_St 3;
BA_ "GenSigSendType" SG_ 741 Con_iPod_IntroScan_St 3;
BA_ "GenSigSendType" SG_ 744 Con_USB_ActTrNum1_St 3;
BA_ "GenSigSendType" SG_ 744 Con_USB_NumberOfTracks 3;
BA_ "GenSigSendType" SG_ 744 Con_iPod_NumberOfTracks 3;
BA_ "ECGUsedTxSignal" SG_ 745 ECG_APIM_Word_Tx 1;
BA_ "GenSigSendType" SG_ 746 Con_BTAud_ActTrNum1_St 3;
BA_ "GenSigSendType" SG_ 746 Con_ShowBTPINNumb_St 3;
BA_ "GenSigSendType" SG_ 746 Con_BTAud_IntroScan_St 3;
BA_ "GenSigSendType" SG_ 746 Con_BTAud_Shuffle_St 3;
BA_ "GenSigSendType" SG_ 746 Con_BTAud_OpMode_St 3;
BA_ "GenSigSendType" SG_ 746 Con_BTAud_Repeat_St 3;
BA_ "GenSigSendType" SG_ 746 Con_BTAud_FunctStats_St 3;
BA_ "GenSigSendType" SG_ 746 Con_BTAud_Error_St 3;
BA_ "GenSigSendType" SG_ 750 Nav_DistancToDestVal_St 3;
BA_ "GenSigSendType" SG_ 750 Nav_RemainTTDestMin_St 3;
BA_ "GenSigSendType" SG_ 750 CancelCurrWaypt_St 3;
BA_ "GenSigSendType" SG_ 750 RouteActive_St 3;
BA_ "GenSigSendType" SG_ 750 Nav_RemainTTDestHour_St 3;
BA_ "GenSigSendType" SG_ 750 Nav_RemainTTDestDays_St 3;
BA_ "GenSigSendType" SG_ 750 WaypointsActive_St 3;
BA_ "GenSigSendType" SG_ 750 RoadsideAsstAvail_D_St 3;
BA_ "GenSigSendType" SG_ 750 LoclFuelEffUnit_D_Stat 3;
BA_ "ECGUsedRxSignal" SG_ 750 LoclFuelEffUnit_D_Stat 1;
BA_ "GenSigSendType" SG_ 750 EmbedNavActive_D_Stat 3;
BA_ "ECGUsedRxSignal" SG_ 750 EmbedNavActive_D_Stat 1;
BA_ "GenSigSendType" SG_ 750 UnitOfLength_St 3;
BA_ "GenSigSendType" SG_ 753 RollCodeValet 3;
BA_ "GenSigSendType" SG_ 753 WndwCabnMde_D_Rq 3;
BA_ "GenSigSendType" SG_ 753 HazrdLghtMde_D_Rq 3;
BA_ "GenSigSendType" SG_ 753 DelvrAsstLckMde_D_Rq 3;
BA_ "GenSigSendType" SG_ 753 DelvrAsstButtn_D_Rq 3;
BA_ "GenSigSendType" SG_ 753 VehOprtMan_B_Rq 3;
BA_ "GenSigSendType" SG_ 753 DrConsoleLckFront_B_Rq 3;
BA_ "GenSigSendType" SG_ 753 OraAutoShutdown_B_Rq 3;
BA_ "GenSigSendType" SG_ 753 OraZone1_D_Rq 3;
BA_ "GenSigSendType" SG_ 753 OraZone5_D_Rq 3;
BA_ "GenSigSendType" SG_ 753 OraZone4_D_Rq 3;
BA_ "GenSigSendType" SG_ 753 OraZone2_D_Rq 3;
BA_ "GenSigSendType" SG_ 753 PdlAsyPos_D_RqMnu 3;
BA_ "GenSigSendType" SG_ 753 SelDrvMdeSwtch_D_Stat8 3;
BA_ "GenSigSendType" SG_ 753 KeylessIdlSrc_D_Rq 3;
BA_ "GenSigSendType" SG_ 753 OraZone6_D_Rq 3;
BA_ "GenSigSendType" SG_ 753 Bec2Oprt_No_RqMnu 3;
BA_ "GenSigSendType" SG_ 754 ACU_ActChimeType_St 3;
BA_ "GenSigSendType" SG_ 756 Chime_Time_Criticality2 3;
BA_ "ECGUsedRxSignal" SG_ 756 Chime_Time_Criticality2 1;
BA_ "GenSigSendType" SG_ 756 Chime_Directionality2 3;
BA_ "ECGUsedRxSignal" SG_ 756 Chime_Directionality2 1;
BA_ "GenSigSendType" SG_ 756 AdjustableChimeVol2_Rq 3;
BA_ "ECGUsedRxSignal" SG_ 756 AdjustableChimeVol2_Rq 1;
BA_ "GenSigSendType" SG_ 756 Chime2Id_No_Rq 3;
BA_ "GenSigSendType" SG_ 756 Chime_Occurence2 3;
BA_ "GenSigSendType" SG_ 757 ACU_AutoStoreResult_St 3;
BA_ "GenSigSendType" SG_ 757 ACU_DirectTune_St 3;
BA_ "GenSigSendType" SG_ 757 ACU_CurrTUBand_St 3;
BA_ "GenSigSendType" SG_ 757 SDARS_ChipControl_St 3;
BA_ "GenSigSendType" SG_ 757 ACU_RadioSeekMode2_St 3;
BA_ "GenSigSendType" SG_ 757 SdarsAudioRtng_D_Stat 3;
BA_ "GenSigSendType" SG_ 757 SpkrStdCntr_D_Stat 3;
BA_ "GenSigSendType" SG_ 757 SpkrStdLeft_D_Stat 3;
BA_ "GenSigSendType" SG_ 757 SpkrStdRight_D_Stat 3;
BA_ "GenSigSendType" SG_ 758 SDARS_OpMode_St 3;
BA_ "GenSigSendType" SG_ 758 SDARS_Factory_Reset_St 3;
BA_ "GenSigSendType" SG_ 758 SDARS_GCI_Update_Prg_St 3;
BA_ "GenSigSendType" SG_ 758 SDARS_SetCategory_St 3;
BA_ "GenSigSendType" SG_ 759 ACM_HDChanStatus 3;
BA_ "GenSigSendType" SG_ 759 ACM_CurrentHDMulticast_St 3;
BA_ "GenSigSendType" SG_ 759 ACM_HDModeStatus 3;
BA_ "GenSigSendType" SG_ 759 NumofHDMulticastChans_St 3;
BA_ "GenSigSendType" SG_ 759 ACM_CurrentSSName 3;
BA_ "GenSigSendType" SG_ 759 ACM_RBDSMode 3;
BA_ "GenSigSendType" SG_ 759 Avail_HD_Chan_St_4 3;
BA_ "GenSigSendType" SG_ 759 Avail_HD_Chan_St_3 3;
BA_ "GenSigSendType" SG_ 759 Avail_HD_Chan_St_2 3;
BA_ "GenSigSendType" SG_ 759 Avail_HD_Chan_St_1 3;
BA_ "GenSigSendType" SG_ 759 Avail_HD_Chan_Valid 3;
BA_ "GenSigSendType" SG_ 759 ACM_TagMode 3;
BA_ "GenSigSendType" SG_ 759 ACM_StationListScanSt 3;
BA_ "GenSigSendType" SG_ 759 Avail_HD_Chan_St_7 3;
BA_ "GenSigSendType" SG_ 759 Avail_HD_Chan_St_6 3;
BA_ "GenSigSendType" SG_ 759 Avail_HD_Chan_St_5 3;
BA_ "GenSigSendType" SG_ 760 SDARS_FillPosition_St 3;
BA_ "GenSigSendType" SG_ 760 SDARS_CurrentChanNum_St 3;
BA_ "GenSigSendType" SG_ 760 SDARS_Playback_St 3;
BA_ "GenSigSendType" SG_ 760 SDARS_Buffer_sec_St 3;
BA_ "GenSigSendType" SG_ 760 SDARS_Channel_Lock 3;
BA_ "GenSigSendType" SG_ 760 SDARS_Alert_Status 3;
BA_ "GenSigSendType" SG_ 760 SDARS_SID_St 3;
BA_ "GenSigSendType" SG_ 761 SDARS_Antenna_Err_St 3;
BA_ "GenSigSendType" SG_ 761 SDARS_Error_Conf_St 3;
BA_ "GenSigSendType" SG_ 761 SDARS_Receive_Err_St 3;
BA_ "GenSigSendType" SG_ 761 SDARS_Firmware_Updat_St 3;
BA_ "GenSigSendType" SG_ 761 SDARS_Invalid_Chan_St 3;
BA_ "GenSigSendType" SG_ 761 SDARS_Seek_Scan_St 3;
BA_ "GenSigSendType" SG_ 761 SDARS_UnSubscrb_St 3;
BA_ "GenSigSendType" SG_ 761 SDARS_Loss_Ant_St 3;
BA_ "GenSigSendType" SG_ 761 SDARS_GCI_Update_St 3;
BA_ "GenSigSendType" SG_ 761 SDARS_Subscription_St 3;
BA_ "GenSigSendType" SG_ 761 SDARS_UnSubscrb_Chan_St 3;
BA_ "GenSigSendType" SG_ 764 SdarsSampleRate_D_Stat 3;
BA_ "GenSigSendType" SG_ 764 SdarsCurntChnl_No_Act3 3;
BA_ "GenSigSendType" SG_ 764 SdarsBaudRate_D_Stat 3;
BA_ "GenSigSendType" SG_ 764 SDARS_ChannelUpdate_St 3;
BA_ "GenSigStartValue" SG_ 764 SDARS_CurrentChanNum2_St 1022;
BA_ "GenSigSendType" SG_ 764 SDARS_CurrentChanNum2_St 3;
BA_ "GenSigSendType" SG_ 764 SDARS_SID2_St 3;
BA_ "GenSigSendType" SG_ 764 SDARS_Channel_Lock2 3;
BA_ "GenSigSendType" SG_ 765 Mc_VehTimeFrmtUsrSel_St 3;
BA_ "GenSigSendType" SG_ 765 Mc_VehLangUsrSel_St 3;
BA_ "GenSigSendType" SG_ 765 Mc_VehThemeUsrSel_St 3;
BA_ "GenSigSendType" SG_ 765 Mc_VehDayNightUsrSel_St 3;
BA_ "GenSigStartValue" SG_ 765 EsaOn_B_Rq 1;
BA_ "GenSigSendType" SG_ 765 EsaOn_B_Rq 3;
BA_ "GenSigStartValue" SG_ 765 EngExhMdeQuiet_D_Rq 2;
BA_ "GenSigSendType" SG_ 765 EngExhMdeQuiet_D_Rq 3;
BA_ "GenSigSendType" SG_ 765 BrkLineLck_D_Rq 3;
BA_ "GenSigSendType" SG_ 765 Running_Board_Cmd 3;
BA_ "GenSigSendType" SG_ 765 Mc_VehUnitTempUsrSel_St 3;
BA_ "GenSigSendType" SG_ 765 Mc_VehUntTrpCoUsrSel_St 3;
BA_ "ECGUsedRxSignal" SG_ 765 Mc_VehUntTrpCoUsrSel_St 1;
BA_ "GenSigStartValue" SG_ 765 RearDiffLck_D_RqArb 3;
BA_ "GenSigSendType" SG_ 765 RearDiffLck_D_RqArb 3;
BA_ "GenSigSendType" SG_ 765 BttOn_B_Rq 3;
BA_ "GenSigStartValue" SG_ 765 AwdRnge_D_ActlIpc 7;
BA_ "GenSigSendType" SG_ 765 AwdRnge_D_ActlIpc 3;
BA_ "GenSigSendType" SG_ 765 AirSusp_D_RqDrv 3;
BA_ "WakeupSignal" SG_ 765 DrvInputRequired_B_Rq 1;
BA_ "GenSigSendType" SG_ 765 DrvInputRequired_B_Rq 3;
BA_ "GenSigStartValue" SG_ 765 Btt_L_Actl 126;
BA_ "GenSigSendType" SG_ 765 SelDrvMdeTxtReset_B_Rq 3;
BA_ "GenSigSendType" SG_ 765 SelDrvMdeDsply_B_Avail 3;
BA_ "GenSigSendType" SG_ 765 AwdDrvMde_D_Rq 3;
BA_ "GenSigStartValue" SG_ 765 AwdMde_D_RqArb 5;
BA_ "GenSigSendType" SG_ 765 AwdMde_D_RqArb 3;
BA_ "GenSigSendType" SG_ 765 EdmSailMde_B_RqDrv 3;
BA_ "GenSigStartValue" SG_ 765 WaitToStartLamp_D_Falt 1;
BA_ "GenSigSendType" SG_ 765 WaitToStartLamp_D_Falt 3;
BA_ "GenSigSendType" SG_ 765 AutoTowAllw_D_RqMnu 3;
BA_ "GenSigSendType" SG_ 765 EngExhMdeQuiet_D2_Rq 3;
BA_ "GenSigStartValue" SG_ 765 BalrSwtch_D_Stat 1;
BA_ "GenSigSendType" SG_ 765 BalrSwtch_D_Stat 3;
BA_ "GenSigSendType" SG_ 765 BalrMde_D_Rq 3;
BA_ "GenSigSendType" SG_ 765 RstrnOnPsngr_D_RqMnu 3;
BA_ "GenSigSendType" SG_ 766 McSelMsgId_B_Stat 3;
BA_ "GenSigSendType" SG_ 766 McPrsntMsgId_B_Stat 3;
BA_ "GenSigSendType" SG_ 766 McPrsntActv_D_Stat 3;
BA_ "GenSigSendType" SG_ 766 McPrsntMsgId_No_Actl 3;
BA_ "GenSigSendType" SG_ 766 McCntrStckNotfn_B_Stat 3;
BA_ "GenSigStartValue" SG_ 770 ScMnSoc_Pc_Actl 100;
BA_ "GenSigStartValue" SG_ 770 CurntTrgtSoc_Pc_Dsply 100;
BA_ "GenSigStartValue" SG_ 770 CurntTrgtSoc_Pc_Rq 100;
BA_ "WakeupSignal" SG_ 772 Memory_Feedback_Rqst 1;
BA_ "WakeupSignal" SG_ 772 Cancel_Auto_Movement 1;
BA_ "WakeupSignal" SG_ 772 Easy_Entry_Rqst 1;
BA_ "WakeupSignal" SG_ 772 SeatScrnDrvOn_B_Rq 1;
BA_ "WakeupSignal" SG_ 772 Memory_Cmd 1;
BA_ "ECGUsedRxSignal" SG_ 773 SeatBckInclnPsng_B_St 1;
BA_ "ECGUsedRxSignal" SG_ 773 SeatPsngrMem_D_Cmd 1;
BA_ "ECGUsedRxSignal" SG_ 773 SeatBckInclTopPsn_B_St 1;
BA_ "GenSigStartValue" SG_ 773 PersStorePsngr_D_Stat 2;
BA_ "ECGUsedRxSignal" SG_ 773 StwblStewMde_D_Stat 1;
BA_ "ECGUsedRxSignal" SG_ 773 SeatLmbrExtnPsngr_B_St 1;
BA_ "ECGUsedRxSignal" SG_ 773 SeatHghtRearPsng_B_St 1;
BA_ "ECGUsedRxSignal" SG_ 773 SeatHghtFrontPsng_B_St 1;
BA_ "ECGUsedRxSignal" SG_ 773 SeatHeadrstTltPsn_B_St 1;
BA_ "ECGUsedRxSignal" SG_ 773 SeatMovPsngr_D_Res 1;
BA_ "ECGUsedRxSignal" SG_ 773 SeatHeadrstHgtPsn_B_St 1;
BA_ "ECGUsedRxSignal" SG_ 773 SeatMovIdPsngr_No_Actl 1;
BA_ "ECGUsedRxSignal" SG_ 773 SeatThghRExtnPsng_B_St 1;
BA_ "ECGUsedRxSignal" SG_ 773 SeatThghLExtnPsng_B_St 1;
BA_ "ECGUsedRxSignal" SG_ 773 SeatSlidPosPsngr_B_St 1;
BA_ "ECGUsedRxSignal" SG_ 773 SeatLmbrHghtPsngr_B_St 1;
BA_ "GenSigStartValue" SG_ 773 PersRecallPsng_D_Actl 2;
BA_ "ECGUsedRxSignal" SG_ 773 SeatMovSrvcPsngr_D_Arb 1;
BA_ "GenSigStartValue" SG_ 778 Cta_D_Rq 1;
BA_ "GenSigSendType" SG_ 778 Cta_D_Rq 3;
BA_ "GenSigSendType" SG_ 778 PrkAidRear_D_RqDrv 3;
BA_ "GenSigSendType" SG_ 778 PrkAidFront_D_RqDrv 3;
BA_ "GenSigStartValue" SG_ 778 Sod_D_Rq 2;
BA_ "GenSigSendType" SG_ 778 Sod_D_Rq 3;
BA_ "GenSigSendType" SG_ 778 SteEffort_D_Rq 3;
BA_ "GenSigSendType" SG_ 778 PrkAidAcsyRear_D_RqDrv 3;
BA_ "GenSigSendType" SG_ 778 PrkAidAcsyFront_D_RqDrv 3;
BA_ "GenSigSendType" SG_ 778 ClrExitAsstEnbl_D_RqDrv 3;
BA_ "GenSigStartValue" SG_ 779 TrlrTireLf_P_Actl 65533;
BA_ "GenSigStartValue" SG_ 779 TrlrTireLm_P_Actl 65533;
BA_ "GenSigStartValue" SG_ 779 TrlrTireLr_P_Actl 65533;
BA_ "GenSigStartValue" SG_ 780 TrlrTireRf_P_Actl 65533;
BA_ "GenSigStartValue" SG_ 780 TrlrTireRm_P_Actl 65533;
BA_ "GenSigStartValue" SG_ 780 TrlrTireRr_P_Actl 65533;
BA_ "GenSigSendType" SG_ 783 TrlrLearnMdeOn_B_RqDrv 3;
BA_ "GenSigSendType" SG_ 783 TrlrTireCnt_D_RqDrv 3;
BA_ "GenSigStartValue" SG_ 784 TrlrTireLf_T_Actl 253;
BA_ "GenSigStartValue" SG_ 784 TrlrTireLm_T_Actl 253;
BA_ "GenSigStartValue" SG_ 784 TrlrTireLr_T_Actl 253;
BA_ "GenSigStartValue" SG_ 784 TrlrTireRf_T_Actl 253;
BA_ "GenSigStartValue" SG_ 784 TrlrTireRm_T_Actl 253;
BA_ "GenSigStartValue" SG_ 784 TrlrTireRr_T_Actl 253;
BA_ "GenSigStartValue" SG_ 784 TrlrTireTempSys_D_Stat 3;
BA_ "GenSigStartValue" SG_ 785 DestChrgEndDay_No_Actl 1;
BA_ "GenSigStartValue" SG_ 785 DteVehOffst_L_Dsply 8190;
BA_ "GenSigStartValue" SG_ 786 VehElRnge_L2_Dsply 8191;
BA_ "GenSigStartValue" SG_ 786 RgenTrip_L_Dsply 65535;
BA_ "WakeupSignal" SG_ 787 DrTGate_D_Rq 1;
BA_ "WakeupSignal" SG_ 787 PwLftgtIntSw_B_Stat 1;
BA_ "WakeupSignal" SG_ 787 DrLckCnt_No_ActlTgate 1;
BA_ "WakeupSignal" SG_ 787 DrTgateChime2_D_Rq 1;
BA_ "GenSigStartValue" SG_ 787 DrMatInhbt_B_Rq 1;
BA_ "GenSigStartValue" SG_ 787 BecConfg_D_Stat 1;
BA_ "GenSigStartValue" SG_ 788 EcoCochATrip1_Pc_Dsply 255;
BA_ "GenSigStartValue" SG_ 788 EcoCochATrip2_Pc_Dsply 255;
BA_ "GenSigStartValue" SG_ 788 EcoCochCrus1_Pc_Dsply 255;
BA_ "GenSigStartValue" SG_ 788 EcoCochCrus2_Pc_Dsply 255;
BA_ "GenSigStartValue" SG_ 788 EcoCochDecel1_Pc_Dsply 255;
BA_ "GenSigStartValue" SG_ 788 EcoCochDecel2_Pc_Dsply 255;
BA_ "ECGUsedRxSignal" SG_ 789 TripSum_Vl_Dsply 1;
BA_ "ECGUsedRxSignal" SG_ 789 VehElSurpStat_L_Dsply 1;
BA_ "ECGUsedRxSignal" SG_ 789 TripSum_L_Dsply 1;
BA_ "ECGUsedRxSignal" SG_ 789 TripSum_E_Dsply 1;
BA_ "GenSigStartValue" SG_ 791 BattElEmotive_Pc_Dsply 1022;
BA_ "GenSigStartValue" SG_ 791 EcoMde_D_RqMnu 1;
BA_ "GenSigSendType" SG_ 791 EcoMde_D_RqMnu 3;
BA_ "WakeupSignal" SG_ 791 ChargeProfIDPref_Rq 1;
BA_ "GenSigSendType" SG_ 791 ChargeProfIDPref_Rq 3;
BA_ "GenSigSendType" SG_ 791 HybMdeOvrrd_D_Rq 3;
BA_ "GenSigStartValue" SG_ 791 StopStrtVThres_D_RqMnu 1;
BA_ "GenSigSendType" SG_ 791 StopStrtVThres_D_RqMnu 3;
BA_ "GenSigSendType" SG_ 791 AwdDrvMde_D2_Rq 3;
BA_ "ECGUsedRxSignal" SG_ 791 ConsAvgTrip_Fe_Dsply 1;
BA_ "GenSigSendType" SG_ 791 EngAirFilt_B_RqReset 3;
BA_ "GenSigSendType" SG_ 791 LongTermReset_B_Rq 3;
BA_ "ECGUsedRxSignal" SG_ 791 LongTermReset_B_Rq 1;
BA_ "GenSigSendType" SG_ 791 GpsElMdeSel_B_Rq 3;
BA_ "GenSigSendType" SG_ 791 EcoCcActv_B_Rq 3;
BA_ "GenSigSendType" SG_ 791 EmotiveType_D_Dsply 3;
BA_ "GenSigSendType" SG_ 791 PlgOvrrdStrt_D_Cmd 3;
BA_ "GenSigSendType" SG_ 791 VehElEffTrip2Reset_B_Rq 3;
BA_ "GenSigSendType" SG_ 791 VehElEffTrip1Reset_B_Rq 3;
BA_ "ECGUsedRxSignal" SG_ 792 ElLongTerm_L_Dsply 1;
BA_ "ECGUsedRxSignal" SG_ 792 ElTrip_L_Dsply 1;
BA_ "ECGUsedRxSignal" SG_ 792 FuelRange_L_Dsply 1;
BA_ "ECGUsedRxSignal" SG_ 792 DsplyChkActv_B_Stat 1;
BA_ "GenSigSendType" SG_ 801 CDWarnChime_St 3;
BA_ "GenSigSendType" SG_ 801 HardWarning 3;
BA_ "GenSigSendType" SG_ 801 SoftWarning 3;
BA_ "GenSigSendType" SG_ 801 InfoWarning 3;
BA_ "GenSigSendType" SG_ 802 AvgFe_No_Dsply 3;
BA_ "GenSigSendType" SG_ 802 AvgFeTrip2Actv_B_Dsply 3;
BA_ "GenSigSendType" SG_ 802 AvgFeTrip1Actv_B_Dsply 3;
BA_ "GenSigSendType" SG_ 802 AvgFeTrip1_No_Dsply 3;
BA_ "GenSigSendType" SG_ 802 AvgFeTrip2_No_Dsply 3;
BA_ "GenSigSendType" SG_ 802 AvgFeTripUnit_D_Stat 3;
BA_ "GenSigSendType" SG_ 802 AvgFeActv_B_Dsply 3;
BA_ "GenSigSendType" SG_ 803 DistTrip1_No_Dsply 3;
BA_ "GenSigSendType" SG_ 803 DistTrip2_No_Dsply 3;
BA_ "GenSigSendType" SG_ 803 DistTripUnit_D_Stat 3;
BA_ "GenSigSendType" SG_ 804 InstFeMax_No_Dsply 3;
BA_ "GenSigSendType" SG_ 804 ConsInst_No_Dsply 3;
BA_ "GenSigSendType" SG_ 804 ConsInstUnit_D_Stat 3;
BA_ "GenSigSendType" SG_ 804 ConsInstActv_B_Dsply 3;
BA_ "ECGUsedRxSignal" SG_ 805 FuelRange_L2_Dsply 1;
BA_ "GenSigSendType" SG_ 807 ElDistTrip1_No_Dsply 3;
BA_ "GenSigSendType" SG_ 807 ElDistTrip2_No_Dsply 3;
BA_ "GenSigSendType" SG_ 807 ElDistTripCur_No_Dsply 3;
BA_ "GenSigSendType" SG_ 807 ElDistTripUnit_D_Stat 3;
BA_ "GenSigSendType" SG_ 810 TrlrIdActv_No_Rq 3;
BA_ "ECGUsedTxSignal" SG_ 810 TrlrIdActv_No_Rq 1;
BA_ "WakeupSignal" SG_ 810 ExtLghtDsply_B_StatArb 1;
BA_ "GenSigSendType" SG_ 810 ExtLghtDsply_B_StatArb 3;
BA_ "ECGUsedTxSignal" SG_ 810 ExtLghtDsply_B_StatArb 1;
BA_ "GenSigSendType" SG_ 810 ScOnb_D_Rq 3;
BA_ "ECGUsedTxSignal" SG_ 810 ScOnb_D_Rq 1;
BA_ "GenSigSendType" SG_ 810 OneTEditActv_B_RqCld 3;
BA_ "ECGUsedTxSignal" SG_ 810 OneTEditActv_B_RqCld 1;
BA_ "WakeupSignal" SG_ 811 ExtLghtLeft_D_RqMnu 1;
BA_ "GenSigSendType" SG_ 811 ExtLghtLeft_D_RqMnu 3;
BA_ "WakeupSignal" SG_ 811 ExtLghtFront_D_RqMnu 1;
BA_ "GenSigSendType" SG_ 811 ExtLghtFront_D_RqMnu 3;
BA_ "GenSigSendType" SG_ 811 ExtLghtDsply_D_Stat 3;
BA_ "ECGUsedRxSignal" SG_ 811 ExtLghtDsply_D_Stat 1;
BA_ "WakeupSignal" SG_ 811 AutoLghtOvrrd_B_RqDrv 1;
BA_ "GenSigSendType" SG_ 811 AutoLghtOvrrd_B_RqDrv 3;
BA_ "WakeupSignal" SG_ 811 ExtLghtRight_D_RqMnu 1;
BA_ "GenSigSendType" SG_ 811 ExtLghtRight_D_RqMnu 3;
BA_ "WakeupSignal" SG_ 811 ExtLghtRear_D_RqMnu 1;
BA_ "GenSigSendType" SG_ 811 ExtLghtRear_D_RqMnu 3;
BA_ "GenSigSendType" SG_ 811 OnePdlDrvButtn_B_Falt 3;
BA_ "GenSigSendType" SG_ 811 LongTermReset_B_RqMnu 3;
BA_ "ECGUsedRxSignal" SG_ 811 LongTermReset_B_RqMnu 1;
BA_ "WakeupSignal" SG_ 811 TrnkFrontRleas_No_RqMnu 1;
BA_ "GenSigSendType" SG_ 811 TrnkFrontRleas_No_RqMnu 3;
BA_ "WakeupSignal" SG_ 811 BecRleas_No_RqMnu 1;
BA_ "GenSigSendType" SG_ 811 BecRleas_No_RqMnu 3;
BA_ "GenSigStartValue" SG_ 811 DistToStopover_L_Actl 65535;
BA_ "ECGUsedRxSignal" SG_ 811 DistToStopover_L_Actl 1;
BA_ "GenSigStartValue" SG_ 811 GoTEditHr_T_RqMnu 30;
BA_ "GenSigSendType" SG_ 811 GoTEditHr_T_RqMnu 3;
BA_ "ECGUsedRxSignal" SG_ 811 GoTEditHr_T_RqMnu 1;
BA_ "GenSigSendType" SG_ 811 StopoverType_D_Stat 3;
BA_ "ECGUsedRxSignal" SG_ 811 StopoverType_D_Stat 1;
BA_ "GenSigSendType" SG_ 811 OnePdlDrvButtn_B_Stat 3;
BA_ "GenSigStartValue" SG_ 811 ScMnSoc_Pc_RqMnu 126;
BA_ "GenSigSendType" SG_ 811 ScEnbl_D_RqMnu 3;
BA_ "GenSigSendType" SG_ 811 SpeedoMajorUnit_D_Confg 3;
BA_ "GenSigStartValue" SG_ 811 GoTEditMnte_T_RqMnu 14;
BA_ "GenSigSendType" SG_ 811 GoTEditMnte_T_RqMnu 3;
BA_ "ECGUsedRxSignal" SG_ 811 GoTEditMnte_T_RqMnu 1;
BA_ "GenSigSendType" SG_ 812 TimerTrip1_T_Dsply 3;
BA_ "GenSigSendType" SG_ 812 TimerTrip2_T_Dsply 3;
BA_ "GenSigSendType" SG_ 813 TimerTripCurnt_T_Dsply 3;
BA_ "WakeupSignal" SG_ 816 KeyPadCodeDgt2_D_Stat 1;
BA_ "GenSigSendType" SG_ 816 KeyPadCodeDgt2_D_Stat 3;
BA_ "WakeupSignal" SG_ 816 KeyPadCodeDgt1_D_Stat 1;
BA_ "GenSigSendType" SG_ 816 KeyPadCodeDgt1_D_Stat 3;
BA_ "WakeupSignal" SG_ 816 KeyPadCodeDgt4_D_Stat 1;
BA_ "GenSigSendType" SG_ 816 KeyPadCodeDgt4_D_Stat 3;
BA_ "WakeupSignal" SG_ 816 KeyPadCodeDgt3_D_Stat 1;
BA_ "GenSigSendType" SG_ 816 KeyPadCodeDgt3_D_Stat 3;
BA_ "WakeupSignal" SG_ 816 KeyPadCodeDgt6_D_Stat 1;
BA_ "GenSigSendType" SG_ 816 KeyPadCodeDgt6_D_Stat 3;
BA_ "WakeupSignal" SG_ 816 KeyPadCodeDgt5_D_Stat 1;
BA_ "GenSigSendType" SG_ 816 KeyPadCodeDgt5_D_Stat 3;
BA_ "GenSigSendType" SG_ 816 DcacPwResetScnd_B_Rq 3;
BA_ "WakeupSignal" SG_ 816 CntrStk2_D_RqAssoc 1;
BA_ "GenSigStartValue" SG_ 816 CntrStk2_D_RqAssoc 3;
BA_ "GenSigSendType" SG_ 816 CntrStk2_D_RqAssoc 3;
BA_ "WakeupSignal" SG_ 816 KeyPadCodeDgt7_D_Stat 1;
BA_ "GenSigSendType" SG_ 816 KeyPadCodeDgt7_D_Stat 3;
BA_ "GenSigStartValue" SG_ 816 DcacLoFuelLim_L_RqMnu 510;
BA_ "GenSigSendType" SG_ 816 DcacLoFuelLim_L_RqMnu 3;
BA_ "ECGUsedRxSignal" SG_ 816 DcacLoFuelLim_L_RqMnu 1;
BA_ "GenSigSendType" SG_ 816 NfcMyKeyCreate_D_Rq 3;
BA_ "GenSigSendType" SG_ 816 DcacZone2Pw_D_Rq 3;
BA_ "GenSigSendType" SG_ 816 DcacAllZone_D_Rq 3;
BA_ "GenSigSendType" SG_ 816 KeylessIdl_D_Rq 3;
BA_ "GenSigSendType" SG_ 816 DgtlKeyPrflAssoc_D_Rq 3;
BA_ "GenSigSendType" SG_ 816 DcacPwScnd_D_Rq 3;
BA_ "GenSigSendType" SG_ 816 DcacZone3Pw_D_Rq 3;
BA_ "GenSigSendType" SG_ 816 HybMdeSel_D_Rq 3;
BA_ "GenSigSendType" SG_ 816 Dimming_Lvl_RqMnu 3;
BA_ "WakeupSignal" SG_ 817 Power_Liftgate_Rqst 1;
BA_ "WakeupSignal" SG_ 817 Power_Decklid_Rqst 1;
BA_ "WakeupSignal" SG_ 817 LockInhibit 1;
BA_ "WakeupSignal" SG_ 817 L_Pwr_Sliding_Dr_Rqst 1;
BA_ "WakeupSignal" SG_ 817 Keyfob_Pad_Msg_Count 1;
BA_ "WakeupSignal" SG_ 817 DrTgateExtSwMde_B_Stat 1;
BA_ "WakeupSignal" SG_ 817 Veh_Lock_Status 1;
BA_ "GenSigStartValue" SG_ 817 Veh_Lock_Status 1;
BA_ "WakeupSignal" SG_ 817 R_Pwr_Sliding_Dr_Rqst 1;
BA_ "WakeupSignal" SG_ 817 Lockmsgtxt_D_Rq 1;
BA_ "WakeupSignal" SG_ 817 Veh_Lock_EvNum 1;
BA_ "WakeupSignal" SG_ 817 Remote_Device_Feedback 1;
BA_ "WakeupSignal" SG_ 817 Veh_Lock_Requestor 1;
BA_ "WakeupSignal" SG_ 817 DrTgateOpen_B_Rq 1;
BA_ "WakeupSignal" SG_ 818 KeyCylSwDrvDr_D_Stat 1;
BA_ "WakeupSignal" SG_ 818 Driver_Lock_Sw_Stat 1;
BA_ "WakeupSignal" SG_ 818 ChildLckPw_D_Rq 1;
BA_ "WakeupSignal" SG_ 818 ChildLckFdbckRd_B_Stat 1;
BA_ "WakeupSignal" SG_ 818 Driver_Lock_Sw_Cnt 1;
BA_ "WakeupSignal" SG_ 818 ChildLckPw_N_Cnt 1;
BA_ "WakeupSignal" SG_ 818 DrPrsntRearDrv_D_Stat 1;
BA_ "WakeupSignal" SG_ 818 DrPrsntDrv_D_Stat 1;
BA_ "WakeupSignal" SG_ 819 Memory_1_SwPsngr_Stat 1;
BA_ "WakeupSignal" SG_ 819 Pasngr_Lock_Sw_Stat 1;
BA_ "WakeupSignal" SG_ 819 ChildLckFdbckRp_B_Stat 1;
BA_ "WakeupSignal" SG_ 819 Pasngr_Lock_Sw_Cnt 1;
BA_ "WakeupSignal" SG_ 819 DrPrsntPsngr_D_Stat 1;
BA_ "WakeupSignal" SG_ 819 Memory_3_SwPsngr_Stat 1;
BA_ "WakeupSignal" SG_ 819 Memory_2_SwPsngr_Stat 1;
BA_ "WakeupSignal" SG_ 819 DrPrsntRearPsngr_D_Stat 1;
BA_ "GenSigStartValue" SG_ 820 TailLghtAnmtn_D_Stat 1;
BA_ "ECGUsedRxSignal" SG_ 820 DgtlShadeAr2_D_Stat 1;
BA_ "ECGUsedRxSignal" SG_ 820 DgtlShadeAr1_D_Stat 1;
BA_ "ECGUsedRxSignal" SG_ 820 DgtlShadeAr4_D_Stat 1;
BA_ "ECGUsedRxSignal" SG_ 820 DgtlShadeAr3_D_Stat 1;
BA_ "ECGUsedRxSignal" SG_ 820 DgtlShadeAr6_D_Stat 1;
BA_ "ECGUsedRxSignal" SG_ 820 DgtlShadeAr5_D_Stat 1;
BA_ "ECGUsedRxSignal" SG_ 820 DgtlShadeMde_D_Stat 1;
BA_ "WakeupSignal" SG_ 826 Mirror_Manual_Override 1;
BA_ "WakeupSignal" SG_ 826 Memory_3_Sw_Stat 1;
BA_ "WakeupSignal" SG_ 826 Memory_2_Sw_Stat 1;
BA_ "WakeupSignal" SG_ 826 Memory_1_Sw_Stat 1;
BA_ "GenSigStartValue" SG_ 827 LghtAmbIntns_D2_Sns 3;
BA_ "WakeupSignal" SG_ 827 SteClmnSwtchTlt_D_Stat 1;
BA_ "WakeupSignal" SG_ 827 SteClmnSwtchTel_D_Stat 1;
BA_ "WakeupSignal" SG_ 828 RearPassWindowPos 1;
BA_ "WakeupSignal" SG_ 828 PassWindowPosition 1;
BA_ "WakeupSignal" SG_ 831 DriverWindowPosition 1;
BA_ "WakeupSignal" SG_ 831 PassWindowCmd 1;
BA_ "WakeupSignal" SG_ 831 PassMirrorCmd 1;
BA_ "WakeupSignal" SG_ 831 RearPassWindowCmd 1;
BA_ "WakeupSignal" SG_ 831 RearDriverWindowPos 1;
BA_ "WakeupSignal" SG_ 836 HvacPrecondBlwr_D_Rq 1;
BA_ "WakeupSignal" SG_ 836 HvacPrecondMode_D_Rq 1;
BA_ "WakeupSignal" SG_ 836 Foh_D_Stat 1;
BA_ "GenSigStartValue" SG_ 837 VehCurb_M_Actl 1022;
BA_ "GenSigStartValue" SG_ 837 VehGvwr_M_Actl 1022;
BA_ "GenSigStartValue" SG_ 838 FohTAllEnable_B_Rq 3;
BA_ "GenSigStartValue" SG_ 838 FohStop_B_Rq 3;
BA_ "GenSigStartValue" SG_ 838 FohContOn_B_Rq 3;
BA_ "WakeupSignal" SG_ 839 FohKeyOff_B_Rq 1;
BA_ "WakeupSignal" SG_ 839 FohEnbl_B_Rq 1;
BA_ "GenSigStartValue" SG_ 839 FohTAllEnable_B_Stat 3;
BA_ "GenSigStartValue" SG_ 839 FohContOn_B_Stat 3;
BA_ "WakeupSignal" SG_ 839 FohStop_B_Stat 1;
BA_ "GenSigStartValue" SG_ 839 FohStop_B_Stat 3;
BA_ "GenSigSendType" SG_ 840 FohT2Friday_T_Rq 3;
BA_ "GenSigSendType" SG_ 840 FohT1Wednesday_T_Rq 3;
BA_ "GenSigSendType" SG_ 840 FohT1Tuesday_T_Rq 3;
BA_ "GenSigSendType" SG_ 840 FohT1Thursday_T_Rq 3;
BA_ "GenSigSendType" SG_ 840 FohT1Sunday_T_Rq 3;
BA_ "GenSigSendType" SG_ 840 FohT1Saturday_T_Rq 3;
BA_ "GenSigSendType" SG_ 840 FohT1Monday_T_Rq 3;
BA_ "GenSigSendType" SG_ 840 FohT1Friday_T_Rq 3;
BA_ "GenSigSendType" SG_ 840 FohAddHeater_D_Rq 3;
BA_ "GenSigSendType" SG_ 840 FohT2Wednesday_T_Rq 3;
BA_ "GenSigSendType" SG_ 840 FohT2Tuesday_T_Rq 3;
BA_ "GenSigSendType" SG_ 840 FohT2Thursday_T_Rq 3;
BA_ "GenSigSendType" SG_ 840 FohT2Sunday_T_Rq 3;
BA_ "GenSigSendType" SG_ 840 FohT2Saturday_T_Rq 3;
BA_ "GenSigSendType" SG_ 840 FohT2Monday_T_Rq 3;
BA_ "GenSigStartValue" SG_ 842 SeatBlLoDrv_Pc_Actl 127;
BA_ "GenSigStartValue" SG_ 842 SeatBlUpDrv_Pc_Actl 127;
BA_ "GenSigStartValue" SG_ 842 SeatLmbrLoDrv_Pc_Actl 127;
BA_ "GenSigStartValue" SG_ 842 SeatLmbrMidDrv_Pc_Actl 127;
BA_ "GenSigStartValue" SG_ 842 SeatLmbrUpDrv_Pc_Actl 127;
BA_ "GenSigStartValue" SG_ 843 SeatBlLoPsgr_Pc_Actl 127;
BA_ "GenSigStartValue" SG_ 843 SeatBlUpPsgr_Pc_Actl 127;
BA_ "GenSigStartValue" SG_ 843 SeatLmbrLoPsgr_Pc_Actl 127;
BA_ "GenSigStartValue" SG_ 843 SeatLmbrMidPsgr_Pc_Actl 127;
BA_ "GenSigStartValue" SG_ 843 SeatLmbrUpPsgr_Pc_Actl 127;
BA_ "WakeupSignal" SG_ 843 StmsSrvcIdPsng_No_Actl 1;
BA_ "WakeupSignal" SG_ 843 SeatSrvcIdPsngr_No_Act 1;
BA_ "GenSigStartValue" SG_ 844 SeatAirAmb_P_Actl 10000;
BA_ "GenSigSendType" SG_ 846 PsgrMemory_Rq 3;
BA_ "GenSigSendType" SG_ 846 SeatFnChngDrv_D_Rq 3;
BA_ "GenSigSendType" SG_ 846 SeatFnChngPsgr_D_Rq 3;
BA_ "GenSigSendType" SG_ 846 SeatFnDfaltDrv_B_Rq 3;
BA_ "GenSigSendType" SG_ 846 SeatFnDfaltPsgr_B_Rq 3;
BA_ "GenSigSendType" SG_ 846 SeatFnDrv_D_Rq 3;
BA_ "GenSigSendType" SG_ 846 SeatFnPsgr_D_Rq 3;
BA_ "GenSigSendType" SG_ 846 SeatFnChngDrv2_D_Rq 3;
BA_ "GenSigSendType" SG_ 846 SeatFnChngPsgr2_D_Rq 3;
BA_ "GenSigSendType" SG_ 846 SeatMasgDrv_D_Rq 3;
BA_ "GenSigSendType" SG_ 846 SeatLmbr_D_Rq 3;
BA_ "GenSigSendType" SG_ 846 SeatRelxPosDactv_B_Rq 3;
BA_ "GenSigSendType" SG_ 846 SeatRelxPosActv_B_Rq 3;
BA_ "GenSigSendType" SG_ 846 SeatRelxPosSet_D_Rq 3;
BA_ "GenSigSendType" SG_ 846 SeatMasgPsngr_D_Rq 3;
BA_ "GenSigSendType" SG_ 846 SeatPosHomeRear_D_Rq 3;
BA_ "ECGUsedRxSignal" SG_ 851 ConsAvgTrip_No_Dsply 1;
BA_ "ECGUsedRxSignal" SG_ 851 ConsLongTerm_No_Dsply 1;
BA_ "GenSigSendType" SG_ 851 ConsUnitIPC_D_Dsply 3;
BA_ "ECGUsedRxSignal" SG_ 851 ConsUnitIPC_D_Dsply 1;
BA_ "GenSigStartValue" SG_ 861 Rr_AUTO_Btn_Stt 2;
BA_ "GenSigStartValue" SG_ 861 Rr_Floor_Btn_Stt 2;
BA_ "GenSigStartValue" SG_ 861 Rr_Control_Btn_Stt 2;
BA_ "GenSigStartValue" SG_ 861 Rr_Blower_Indicate 15;
BA_ "GenSigStartValue" SG_ 861 Rr_LH_Cld_Seat_Btn_Stt 2;
BA_ "GenSigStartValue" SG_ 861 Rr_LHS_Set_Temp_Dig2 15;
BA_ "GenSigStartValue" SG_ 861 Rr_LHS_Set_Temp_Dig1 15;
BA_ "GenSigStartValue" SG_ 861 Rr_LH_Htd_Seat_Btn_Stt 2;
BA_ "GenSigStartValue" SG_ 861 Rr_Pnl_Flr_Btn_Stt 2;
BA_ "GenSigStartValue" SG_ 861 Rr_Panel_Btn_Stt 2;
BA_ "GenSigStartValue" SG_ 861 Rr_Set_Temp_Units 2;
BA_ "GenSigStartValue" SG_ 861 Rr_RHS_Set_Temp_Dig3 2;
BA_ "GenSigStartValue" SG_ 861 Rr_RH_Htd_Seat_Btn_Stt 2;
BA_ "GenSigStartValue" SG_ 861 Rr_RH_Cld_Seat_Btn_Stt 2;
BA_ "GenSigStartValue" SG_ 861 Rr_RHS_Set_Temp_Dig2 15;
BA_ "GenSigStartValue" SG_ 861 Rr_RHS_Set_Temp_Dig1 15;
BA_ "GenSigStartValue" SG_ 861 Rr_Power_Btn_Stt 2;
BA_ "ECGUsedRxSignal" SG_ 862 CabnAmb_Te_Actl 1;
BA_ "GenSigStartValue" SG_ 862 ClimtThrmlLoad_No_Actl 255;
BA_ "WakeupSignal" SG_ 863 StewSwtchPrim_D_Stat2 1;
BA_ "WakeupSignal" SG_ 863 StewSwtchScnd_D_Stat2 1;
BA_ "GenSigStartValue" SG_ 864 Dual_Button_Stt 2;
BA_ "GenSigStartValue" SG_ 864 Defrost_Btn_Stt 2;
BA_ "GenSigStartValue" SG_ 864 Auto_Recirc_Btn_Stt 2;
BA_ "GenSigStartValue" SG_ 864 AC_Btn_Stt 2;
BA_ "GenSigStartValue" SG_ 864 Front_Power_Btn_Stt 2;
BA_ "GenSigStartValue" SG_ 864 Front_AUTO_Label 2;
BA_ "GenSigStartValue" SG_ 864 Front_AUTO_Btn_Stt 2;
BA_ "GenSigStartValue" SG_ 864 Floor_Btn_Stt 2;
BA_ "GenSigStartValue" SG_ 864 LHS_Cld_Seat_Btn_Stt 2;
BA_ "GenSigStartValue" SG_ 864 Htd_Strg_Whl_Status 2;
BA_ "GenSigStartValue" SG_ 864 Htd_Strg_Whl_Btn_Stt 2;
BA_ "GenSigStartValue" SG_ 864 Htd_Frt_Wsh_Btn_Stt 2;
BA_ "GenSigStartValue" SG_ 864 My_Temp_Btn_Stt 2;
BA_ "GenSigStartValue" SG_ 864 Max_Defrost_Btn_Stt 2;
BA_ "GenSigStartValue" SG_ 864 Max_AC_Btn_Stt 2;
BA_ "GenSigStartValue" SG_ 864 LHS_Htd_Seat_Btn_Stt 2;
BA_ "GenSigStartValue" SG_ 864 Recirc_Btn_Stt 2;
BA_ "GenSigStartValue" SG_ 864 Rear_Defrost_Btn_Stt 2;
BA_ "GenSigStartValue" SG_ 864 Panel_Btn_Stt 2;
BA_ "GenSigStartValue" SG_ 864 Outside_Btn_Stt 2;
BA_ "GenSigStartValue" SG_ 864 Windscreen_Btn_Stt 2;
BA_ "GenSigStartValue" SG_ 864 RHS_Htd_Seat_Btn_Stt 2;
BA_ "GenSigStartValue" SG_ 864 RHS_Cld_Seat_Btn_Stt 2;
BA_ "GenSigStartValue" SG_ 864 DrvrFcsdMde_Btn_Stt 2;
BA_ "GenSigStartValue" SG_ 865 Front_Blower_Indicate 15;
BA_ "GenSigStartValue" SG_ 865 RHS_Auto_Seat_Btn_Stt 2;
BA_ "GenSigStartValue" SG_ 865 LHS_Auto_Seat_Btn_Stt 2;
BA_ "GenSigStartValue" SG_ 865 Dsp_RotAddrBtnEv_St 7;
VAL_ 726 ACU_AFJump_St 0 "NoDataExists" 1 "Inhibited" 2 "Enabled" ;
VAL_ 726 ACU_TAMode_St 0 "Invalid" 1 "TaLocalOn" 2 "TaDistantOn" 3 "TaOff" ;
VAL_ 726 ACU_NEWSMode_St 0 "Invalid" 1 "NewsOn" 2 "NewsOff" ;
VAL_ 727 ACU_LoadEjectDisc_St 0 "Invalid" 1 "Disc1" 2 "Disc2" 3 "Disc3" 4 "Disc4" 5 "Disc5" 6 "Disc6" 7 "All" ;
VAL_ 727 ACU_LoadEjectMode_St 0 "Invalid" 1 "LoadModeInactiveDiscNumIg" 2 "LoadModeActiveDiscNumIgno" 3 "PreparingToLoad" 4 "Insert" 5 "Loading" 6 "PreparingToEject" 7 "Ejecting" 8 "RemoveDisc" ;
VAL_ 728 PrplSnd_D_Stat 0 "Null" 1 "Disabled" 2 "Enabled" 3 "Faulty" ;
VAL_ 728 ACU_Volume_Up 0 "NoUpdate" 1 "Update" ;
VAL_ 728 ACU_RadioSeekMode_St 0 "Invalid" 1 "SeekOff" 2 "AutoUp" 3 "AutoDown" 4 "ManSingleStepUp" 5 "ManSingleStepDown" 6 "ContManualUp" 7 "ContManualDown" 8 "ScanUp" 9 "ScanDown" 10 "PtySeekUp" 11 "PtySeekDown" 12 "Autostore" 13 "TpSeek" 14 "PISeek" ;
VAL_ 728 ACU_AuxVolume_Up 0 "NoUpdate" 1 "Update" ;
VAL_ 729 ACU_DSP_St 0 "Invalid" 1 "All" 2 "Driver" 3 "Passenger" 4 "Reserved1" 5 "Reserved2" 6 "Reserved3" 7 "FrontSeats" 8 "RearSeats" 9 "Convertible" 15 "Reserved" ;
VAL_ 729 ACU_NavCmdVolume_Up 0 "NoUpdate" 1 "Update" ;
VAL_ 729 ACU_TAVolume_Up 0 "NoUpdate" 1 "Update" ;
VAL_ 729 ACU_PhoneVolume_Up 0 "NoUpdate" 1 "Update" ;
VAL_ 729 ACU_Reg_St 0 "Invalid" 1 "Off" 2 "On" ;
VAL_ 729 ACU_VoiceFBVolume_Up 0 "NoUpdate" 1 "Update" ;
VAL_ 729 ACU_DSPProgram_St 0 "Invalid" 1 "Normal" 2 "Pop" 3 "Classical" 4 "Rock" 5 "Voice" 6 "Reserved1" 7 "Reserved2" ;
VAL_ 732 ACU_CurrPreset2_St 0 "Invalid" 31 "NoActivePreset" ;
VAL_ 732 ACU_FunctionStatus_St 0 "Invalid" 1 "Reading" 2 "Loading" 3 "Loaded" 4 "Insert" 5 "PreparingToEject" 6 "Ejecting" 7 "RemoveDisc" ;
VAL_ 732 ACU_CurrFMSLPreset_St 0 "Invalid" 255 "NoValidPreset" ;
VAL_ 732 ACU_StorePreset_St 0 "Invalid" 31 "NotStoring" ;
VAL_ 732 ACU_CurrMixPreset_St 0 "Invalid" 31 "NoActivePreset" ;
VAL_ 732 ACU_VoiceCommand_St 0 "Invalid" 1 "Ok" 2 "NotOk" ;
VAL_ 732 ACU_CurrItemsInFMSL_St 0 "Invalid" 255 "NoValidPreset" ;
VAL_ 734 ACU_CurrTURadioBand_St 0 "Invalid" 1 "Fm1" 2 "Fm2" 3 "FmAst" 4 "Am" 5 "AmAst" 6 "Fm3" 7 "DAB1" 8 "DAB2" 9 "SAT1" 10 "SAT2" 11 "SAT3" 12 "reserved" 15 "reserved_last" ;
VAL_ 734 ACU_CurrTUServiceLink_St 0 "Invalid" 1 "Active" 2 "Inactive" 3 "reserved" ;
VAL_ 734 ACU_CurrTUDRService_St 0 "Invalid" 1 "SyncEnsemble" 2 "ServiceNotAvailable" 3 "ServiceAvailable" ;
VAL_ 734 ACU_ActServiceLink_St 0 "Invalid" 1 "DAB2FM" 2 "FM2DAB" 3 "reserved" ;
VAL_ 734 ACU_CurrTUDRService2_St 0 "Invalid" 1 "SyncEnsemble" 2 "ServiceNotAvailable" 3 "ServiceAvailable" 4 "DabNotAvailable" 5 "reserved" 7 "last_reserved" ;
VAL_ 734 ACU_ComTUSIDValid_St 0 "Invalid" 1 "Validation" ;
VAL_ 736 VRM_IncCallOption_St 0 "Inactive" 1 "RejectAll" 2 "AcceptIncomingCall" 3 "Silent" ;
VAL_ 736 BTInCallOptions_St 0 "Inactive" 1 "Switched" 2 "Joined" 3 "InPrivacyMode" 4 "InHandsFreeMode" 5 "InHoldMode" 6 "HoldModeoff" ;
VAL_ 736 TextMessage_Rsp 0 "Invalid" 1 "Listening" 2 "MessageIgnored" 3 "Cancelled" ;
VAL_ 739 HMI_HMIMode_St 0 "Invalid" 1 "OffMode" 2 "On" 3 "Phone" 4 "Climate" 5 "Load_Shed_Active" 6 "NotUsed1" 7 "NotUsed2" ;
VAL_ 739 BptStrtStop_D_RqMnu 0 "NoRequest" 1 "Stop" 2 "Start" 3 "NotUsed_1" ;
VAL_ 739 BptMde_D_RqMnu 0 "Null" 1 "Off" 2 "Manual" 3 "Automatic" 4 "NotUsed_1" 5 "NotUsed_2" 6 "NotUsed_3" 7 "NotUsed_4" ;
VAL_ 739 EngExhMdeHrStrt_D_Rq 0 "Null" 1 "Hour0_12am" 2 "Hour1_1am" 3 "Hour2_2am" 4 "Hour3_3am" 5 "Hour4_4am" 6 "Hour5_5am" 7 "Hour6_6am" 8 "Hour7_7am" 9 "Hour8_8am" 10 "Hour9_9am" 11 "Hour10_10am" 12 "Hour11_11am" 13 "Hour12_12pm" 14 "Hour13_1pm" 15 "Hour14_2pm" 16 "Hour15_3pm" 17 "Hour16_4pm" 18 "Hour17_5pm" 19 "Hour18_6pm" 20 "Hour19_7pm" 21 "Hour20_8pm" 22 "Hour21_9pm" 23 "Hour22_10pm" 24 "Hour23_11pm" 25 "NotUsed_1" 26 "NotUsed_2" 27 "NotUsed_3" 28 "NotUsed_4" 29 "NotUsed_5" 30 "NotUsed_6" 31 "NotUsed_7" ;
VAL_ 739 OnbTrgtSocOvrrd_D_Rq 0 "Null" 1 "Disable" 2 "Enable" 3 "NotUsed" ;
VAL_ 739 Partial_Amp_Shutdown 0 "Inactive" 1 "Active" ;
VAL_ 739 SeatOccChime_B_RqCancl 0 "Null" 1 "Cancel" ;
VAL_ 739 EngExhMdeHrEnbl_D_Rq 0 "Null" 1 "Disabled" 2 "Enabled" 3 "NotConfigured" ;
VAL_ 739 EngExhMdeHrEnd_D_Rq 0 "Null" 1 "Hour0_12am" 2 "Hour1_1am" 3 "Hour2_2am" 4 "Hour3_3am" 5 "Hour4_4am" 6 "Hour5_5am" 7 "Hour6_6am" 8 "Hour7_7am" 9 "Hour8_8am" 10 "Hour9_9am" 11 "Hour10_10am" 12 "Hour11_11am" 13 "Hour12_12pm" 14 "Hour13_1pm" 15 "Hour14_2pm" 16 "Hour15_3pm" 17 "Hour16_4pm" 18 "Hour17_5pm" 19 "Hour18_6pm" 20 "Hour19_7pm" 21 "Hour20_8pm" 22 "Hour21_9pm" 23 "Hour22_10pm" 24 "Hour23_11pm" 25 "NotUsed_1" 26 "NotUsed_2" 27 "NotUsed_3" 28 "NotUsed_4" 29 "NotUsed_5" 30 "NotUsed_6" 31 "NotUsed_7" ;
VAL_ 739 VgfSet_D_Stat 0 "Null" 1 "Off" 2 "On" 3 "NotUsed" ;
VAL_ 739 VehHornOccAlrt_D_Stat 0 "Null" 1 "Off" 2 "On" 3 "NotUsed" ;
VAL_ 739 SeatOccRear_D_Stat 0 "Null" 1 "Off" 2 "On" 3 "NotUsed" ;
VAL_ 739 BabySeatInUse_D_Stat 0 "Null" 1 "NotInUse" 2 "InUse" 3 "NotUsed" ;
VAL_ 739 BptMnSoc_L_RqMnu 8190 "NoDataExists" 8191 "Faulty" ;
VAL_ 739 LostPKChirp_D_RqMnu 0 "Null" 1 "Disabled" 2 "Enabled" 3 "NotConfigured" ;
VAL_ 739 SpeedChngChime_D_Rq 0 "Null" 1 "Off" 2 "On" 3 "NotUsed" ;
VAL_ 739 BptDly_T_RqMnu 62 "NoDataExists" 63 "Faulty" ;
VAL_ 740 SndPersIndx_D_Stat 0 "Pers_1" 1 "Pers_2" 2 "Pers_3" 3 "Pers_4" 4 "Vehicle" 5 "NotUsed_1" 6 "NotUsed_2" 7 "NotUsed_3" ;
VAL_ 740 EmgcyAsstActv_D_Stat 0 "Null" 1 "Inactive" 2 "Active" 3 "ConfiguredOff" ;
VAL_ 740 SndPersSrvc_D_Res 0 "Null" 1 "Success" 2 "Pending" 3 "Rejected" 4 "Interrupted" 5 "Failed" 6 "In_Prog" 7 "Invalid" 8 "NotUsed_1" 9 "NotUsed_2" 10 "NotUsed_3" 11 "NotUsed_4" 12 "NotUsed_5" 13 "NotUsed_6" 14 "NotUsed_7" 15 "Faulty" ;
VAL_ 740 SndPersChng_D_Stat 0 "Null" 1 "Profile_Updated" 2 "Data_Lost" 3 "NotUsed_1" ;
VAL_ 741 Con_USB_Shuffle_St 0 "Invalid" 1 "Off" 2 "OnTheDevice" 3 "OnTheFolderSelGroup" ;
VAL_ 741 Con_USB_FunctStatus_St 0 "Invalid" 1 "Free" 2 "Initilization" 3 "Ready" 4 "Reading" 5 "Reserved" 6 "Reserved1" 7 "Reserved2" ;
VAL_ 741 Con_USB_OpMode_St 0 "Invalid" 1 "Stop" 2 "Play" 3 "Pause" 4 "FastForward10" 5 "FastForward20" 6 "FastRewind10" 7 "FastRewind20" ;
VAL_ 741 Con_USB_IntroScan_St 0 "Invalid" 1 "Off" 2 "OnTheDevice" 3 "OnTheFolderSelGroup" ;
VAL_ 741 Con_iPod_FunctStatus_St 0 "Invalid" 1 "Free" 2 "Initilization" 3 "Ready" 4 "Reading" 5 "Reserved" 6 "Reserved1" 7 "Reserved2" ;
VAL_ 741 Con_iPod_OpMode_St 0 "Invalid" 1 "Stop" 2 "Play" 3 "Pause" 4 "FastForward10" 5 "FastForward20" 6 "FastRewind10" 7 "FastRewind20" ;
VAL_ 741 Con_iPod_Shuffle_St 0 "Invalid" 1 "Off" 2 "OnTheDevice" 3 "OnTheFolderSelGroup" ;
VAL_ 741 Con_iPod_Repeat_St 0 "Invalid" 1 "Off" 2 "RepeatOnTrack" 3 "RepeatOnFolder" 4 "RepeatOnDevice" 5 "Reserved" 6 "Reserved1" 7 "Reserved2" ;
VAL_ 741 Con_USB_Repeat_St 0 "Invalid" 1 "Off" 2 "RepeatOnTrack" 3 "RepeatOnFolder" 4 "RepeatOnDevice" 5 "Reserved" 6 "Reserved1" 7 "Reserved2" ;
VAL_ 741 Con_iPod_Error_St 0 "Invalid" 1 "NoError" 2 "InvalidFile" 3 "DeviceNotSupported" 4 "FileSysNotSupported" 5 "NoDataOnDevice" 6 "UnableToRead" 7 "NoRespFromDevice" 8 "NoDataInFolder" ;
VAL_ 741 Con_USB_Error_St 0 "Invalid" 1 "NoError" 2 "InvalidFile" 3 "DeviceNotSupported" 4 "FileSysNotSupported" 5 "NoDataOnDevice" 6 "UnableToRead" 7 "NoRespFromDevice" 8 "NoDataInFolder" 9 "USBHubNotSupported" ;
VAL_ 741 Con_ShowSWDLprogress_St 0 "Invalid" 1 "ConSWUpdateNotRunning" 2 "ConSWUpdateInProgress" 3 "ConSWUpdateFailed" 4 "ConSWUpdateNotNecessary" 5 "ConSWUpdateSuccess" ;
VAL_ 741 Con_USB_Playtype_St 0 "Invalid" 1 "Folder" 2 "Playlist" ;
VAL_ 741 Con_iPod_IntroScan_St 0 "Invalid" 1 "Off" 2 "OnTheDevice" 3 "OnTheFolderSelGroup" ;
VAL_ 746 Con_BTAud_IntroScan_St 0 "Invalid" 1 "Off" 2 "OnTheDevice" 3 "OnTheFolderSelGroup" ;
VAL_ 746 Con_BTAud_Shuffle_St 0 "Invalid" 1 "Off" 2 "OnTheDevice" 3 "OnTheFolderSelGroup" ;
VAL_ 746 Con_BTAud_OpMode_St 0 "Invalid" 1 "Stop" 2 "Play" 3 "Pause" 4 "FastForward10" 5 "FastForward20" 6 "FastRewind10" 7 "FastRewind20" ;
VAL_ 746 Con_BTAud_Repeat_St 0 "Invalid" 1 "Off" 2 "RepeatOnTrack" 3 "RepeatOnFolder" 4 "RepeatOnDevice" 5 "Reserved1" 6 "Reserved2" 7 "Reserved3" ;
VAL_ 746 Con_BTAud_FunctStats_St 0 "Invalid" 1 "Free" 2 "Initilization" 3 "Ready" 4 "Reading" 5 "Reserved" 6 "Reserved1" 7 "Reserved2" ;
VAL_ 746 Con_BTAud_Error_St 0 "Invalid" 1 "NoError" 2 "InvalidFile" 3 "DeviceNotSupported" 4 "FileSysNotSupported" 5 "NoDataOnDevice" 6 "UnableToRead" 7 "NoRespFromDevice" 8 "NoDataInFolder" ;
VAL_ 750 Nav_DistanToDestUnit_St 0 "Kilometers_km" 1 "Meters_m" 2 "Miles_mi" 3 "Yards_yd" ;
VAL_ 750 CancelCurrWaypt_St 0 "Inactive" 1 "Cancelled" ;
VAL_ 750 RouteActive_St 0 "Inactive" 1 "Active" ;
VAL_ 750 Nav_RemainTTDestDays_St 14 "Exceeding13days" ;
VAL_ 750 NavError_Waypoint_St 0 "Invalid" 1 "No_Error" 2 "Navigation_Fault" ;
VAL_ 750 WaypointsActive_St 0 "Invalid" 1 "Waypoints_Inactive" 2 "Waypoints_Active" 3 "Max_Waypoints_Active" ;
VAL_ 750 RoadsideAsstAvail_D_St 0 "Null" 1 "NotAvailable" 2 "AvailableLincoln" 3 "AvailableFord" ;
VAL_ 750 LoclFuelEffUnit_D_Stat 0 "Null" 1 "Inactive" 2 "Active" 3 "NotUsed" ;
VAL_ 750 EmbedNavActive_D_Stat 0 "Null" 1 "Inactive" 2 "Active" 3 "NotUsed" ;
VAL_ 750 UnitOfLength_St 0 "Invalid" 1 "kilometers_meters" 2 "miles_feets" 3 "miles_yards" ;
VAL_ 753 WndwCabnMde_D_Rq 0 "Inactive" 1 "Off" 2 "On" 3 "NotUsed" ;
VAL_ 753 HazrdLghtMde_D_Rq 0 "Inactive" 1 "Off" 2 "On" 3 "NotUsed" ;
VAL_ 753 DelvrAsstLckMde_D_Rq 0 "Inactive" 1 "Off" 2 "On" 3 "NotUsed" ;
VAL_ 753 DelvrAsstButtn_D_Rq 0 "Inactive" 1 "OnDemand" 2 "MultipleStops" 3 "NotUsed_1" ;
VAL_ 753 VehOprtMan_B_Rq 0 "Off" 1 "On" ;
VAL_ 753 DrConsoleLckFront_B_Rq 0 "Null" 1 "Unlock" ;
VAL_ 753 OraAutoShutdown_B_Rq 0 "Inactive" 1 "Active" ;
VAL_ 753 OraZone1_D_Rq 0 "Inactive" 1 "Off" 2 "On" 3 "NotUsed" ;
VAL_ 753 OraZone5_D_Rq 0 "Inactive" 1 "Off" 2 "On" 3 "NotUsed" ;
VAL_ 753 OraZone4_D_Rq 0 "Inactive" 1 "Off" 2 "On" 3 "NotUsed" ;
VAL_ 753 OraZone2_D_Rq 0 "Inactive" 1 "Off" 2 "On" 3 "NotUsed" ;
VAL_ 753 PdlAsyPos_D_RqMnu 0 "Idle" 1 "Stow" 2 "Deploy" 3 "NotUsed_1" ;
VAL_ 753 SelDrvMdeSwtch_D_Stat8 0 "NotPressed" 1 "SwitchState1" 2 "SwitchState2" 3 "Faulty" ;
VAL_ 753 KeylessIdlSrc_D_Rq 0 "Inactive" 1 "ProPowerOnboard" 2 "UpfitterInterface" 3 "ComfortPet" 4 "NotUsed_1" 5 "NotUsed_2" 6 "NotUsed_3" 7 "Faulty" ;
VAL_ 753 OraZone6_D_Rq 0 "Inactive" 1 "Off" 2 "On" 3 "NotUsed" ;
VAL_ 754 ACU_ActChimeType_St 0 "Invalid" 1 "No_Chime" 2 "Sine" 3 "Sample" 4 "Reserved1" 5 "Reserved2" 6 "Reserved3" 7 "Reserved4" ;
VAL_ 756 Chime_Time_Criticality2 0 "Inactive" 1 "High" 2 "Low" ;
VAL_ 756 Chime_Directionality2 0 "Inactive" 1 "ALL" 2 "FrontSpeakers" 3 "RearSpeakers" ;
VAL_ 756 AdjustableChimeVol2_Rq 0 "DefaultVolume" 1 "LevelMinus6" 2 "LevelMinus5" 3 "LevelMinus4" 4 "LevelMinus3" 5 "LevelMinus2" 6 "LevelMinus1" 7 "LevelPlus1" 8 "LevelPlus2" 9 "LevelPlus3" 10 "LevelPlus4" 11 "LevelPlus5" 12 "LevelPlus6" 13 "NotUsed_1" 14 "NotUsed_2" 15 "NotUsed_3" ;
VAL_ 756 Chime2Id_No_Rq 0 "Inactive" 1 "Id1" 10 "Id10" 20 "Id20" 30 "Id30" 40 "Id40" 50 "Id50" 60 "Id60" 70 "Id70" 80 "Id80" 90 "Id90" 100 "Id100" 120 "Id120" 140 "Id140" 160 "Id160" 180 "Id180" 200 "Id200" 220 "Id220" 240 "Id240" 250 "Id250" 255 "Id255" ;
VAL_ 756 Chime_Occurence2 0 "Inactive" 1 "PlayOnce" 2 "2Repititions" 3 "3Repititions" 4 "4Repititions" 5 "5Repititions" 6 "6Repititions" 7 "7Repititions" 8 "8Repititions" 9 "9Repititions" 10 "10Repititions" 11 "11Repititions" 12 "12Repititions" 13 "13Repititions" 14 "14Repititions" 15 "Continuous" ;
VAL_ 757 ACU_AutoStoreResult_St 0 "Invalid" 1 "Inactive" 2 "No_Station_Found" ;
VAL_ 757 ACU_DirectTune_St 0 "Invalid" 1 "Invalid_Station" 2 "Valid_Station" ;
VAL_ 757 ACU_CurrTUBand_St 0 "Invalid" 1 "Fm1" 2 "Fm2" 3 "FmAst" 4 "Am" 5 "AmAst" 6 "Fm3" 7 "DAB1" 8 "DAB2" 9 "SAT1" 10 "SAT2" 11 "SAT3" 12 "DAB3" 13 "reserved1" 15 "reserved_last" ;
VAL_ 757 SDARS_ChipControl_St 0 "Null" 1 "Off" 2 "PowerUpInProgress" 3 "PowerDownInProgress" 4 "ResetInProgress" 5 "Ready" 6 "NotUsed_1" 7 "NotUsed_2" ;
VAL_ 757 ACU_RadioSeekMode2_St 0 "Invalid" 1 "SeekOff" 2 "AutoUp" 3 "AutoDown" 4 "ManSingleStepUp" 5 "ManSingleStepDown" 6 "ContManualUp" 7 "ContManualDown" 8 "ScanUp" 9 "ScanDown" 10 "PtySeekUp" 11 "PtySeekDown" 12 "Autostore" 13 "TpSeek" 14 "PISeek" 15 "ContAutoUp" 16 "ContAutoDown" ;
VAL_ 757 SdarsAudioRtng_D_Stat 0 "NotDetermined" 1 "X40I2SStereoOut" 2 "APIMStereoOut" 3 "NotUsed_1" ;
VAL_ 757 SpkrStdCntr_D_Stat 0 "Null" 1 "NotPresent" 2 "Normal" 3 "Faulty" ;
VAL_ 757 SpkrStdLeft_D_Stat 0 "Null" 1 "NotPresent" 2 "Normal" 3 "Faulty" ;
VAL_ 757 SpkrStdRight_D_Stat 0 "Null" 1 "NotPresent" 2 "Normal" 3 "Faulty" ;
VAL_ 758 SDARS_OpMode_St 0 "Invalid" 1 "Stop" 2 "Play" 3 "Pause" 4 "FastForwardSpeed1" 5 "FastForwardSpeed2" 6 "FastRewindSpeed1" 7 "FastRewindSpeed2" ;
VAL_ 758 SDARS_Factory_Reset_St 0 "Invalid" 1 "FactorySettingsRestored" ;
VAL_ 759 ACM_HDChanStatus 1 "Acquiring" 2 "Acquired" 3 "Not_Multicast" 4 "Not_Found" ;
VAL_ 759 ACM_CurrentHDMulticast_St 0 "0" 1 "1" 2 "2" 3 "3" 4 "4" 5 "5" 6 "6" 7 "7" ;
VAL_ 759 ACM_HDModeStatus 0 "Inactive" 1 "Off" 2 "On" ;
VAL_ 759 NumofHDMulticastChans_St 0 "zero" 1 "Multicast_Available_1" 2 "Multicast_Available_2" 3 "Multicast_Available_3" 4 "Multicast_Available_4" 5 "Multicast_Available_5" 6 "Multicast_Available_6" 7 "Multicast_Available_7" ;
VAL_ 759 ACM_RBDSMode 0 "Inactive" 1 "Off" 2 "On" ;
VAL_ 759 Avail_HD_Chan_St_4 0 "NotAvailable" 1 "Available" ;
VAL_ 759 Avail_HD_Chan_St_3 0 "NotAvailable" 1 "Available" ;
VAL_ 759 Avail_HD_Chan_St_2 0 "NotAvailable" 1 "Available" ;
VAL_ 759 Avail_HD_Chan_St_1 0 "NotAvailable" 1 "Available" ;
VAL_ 759 Avail_HD_Chan_Valid 0 "Invalid" 1 "Valid" ;
VAL_ 759 ACM_TagMode 0 "Inactive" 1 "Off" 2 "On" ;
VAL_ 759 ACM_StationListScanSt 1 "Scan_Cancelled" ;
VAL_ 759 Avail_HD_Chan_St_7 0 "NotAvailable" 1 "Available" ;
VAL_ 759 Avail_HD_Chan_St_6 0 "NotAvailable" 1 "Available" ;
VAL_ 759 Avail_HD_Chan_St_5 0 "NotAvailable" 1 "Available" ;
VAL_ 760 SDARS_Channel_Lock 0 "Invalid" 1 "Locked" 2 "Unlocked" ;
VAL_ 760 SDARS_Alert_Status 0 "Invalid" 1 "Enabled" 2 "Disabled" ;
VAL_ 761 SDARS_Antenna_Err_St 0 "Invalid" 1 "Inactive" 2 "Active" ;
VAL_ 761 SDARS_Error_Conf_St 0 "Invalid" 1 "SDARS_ON" 2 "SDARS_OFF" ;
VAL_ 761 SDARS_Receive_Err_St 0 "Invalid" 1 "Inactive" 2 "Active" ;
VAL_ 761 SDARS_Firmware_Updat_St 0 "Invalid" 1 "Inactive" 2 "Active" ;
VAL_ 761 SDARS_Invalid_Chan_St 0 "Invalid" 1 "Inactive" 2 "Active" ;
VAL_ 761 SDARS_Seek_Scan_St 0 "Invalid" 1 "NoChannelsAvailable" ;
VAL_ 761 SDARS_UnSubscrb_St 0 "Invalid" 1 "Inactive" 2 "Active" ;
VAL_ 761 SDARS_Loss_Ant_St 0 "Invalid" 1 "Inactive" 2 "Active" ;
VAL_ 761 SDARS_GCI_Update_St 0 "Invalid" 1 "Inactive" 2 "Active" ;
VAL_ 761 SDARS_Subscription_St 0 "Invalid" 1 "Inactive" 2 "Active" ;
VAL_ 761 SDARS_UnSubscrb_Chan_St 0 "Invalid" 1 "Inactive" 2 "Active" ;
VAL_ 764 SdarsSampleRate_D_Stat 0 "Null" 1 "SampleRate_44100Hz" 2 "SampleRate_48000Hz" 3 "NotUsed_1" ;
VAL_ 764 SdarsBaudRate_D_Stat 0 "Null" 1 "BaudRate_57600bps" 2 "BaudRate_115200bps" 3 "BaudRate_230400bps" 4 "BaudRate_460800bps" 5 "NotUsed_1" 6 "NotUsed_2" 7 "NotUsed_3" ;
VAL_ 764 SDARS_ChannelUpdate_St 0 "Inactive" 1 "NoUpdates" 2 "NewUpdatesAvailable" 3 "NotUsed_1" ;
VAL_ 764 SDARS_Channel_Lock2 0 "Invalid" 1 "Locked" 2 "Unlocked" ;
VAL_ 765 Mc_VehTimeFrmtUsrSel_St 0 "Invalid" 1 "12h_mode" 2 "24h_mode" ;
VAL_ 765 Mc_VehLangUsrSel_St 0 "Invalid" 1 "Unknown" 2 "UK_English" 3 "NA_English" 4 "German" 5 "Italian" 6 "EU_French" 7 "Cana_French" 8 "EU_Spanish" 9 "Mex_Spanish" 10 "Turkish" 11 "Russian" 12 "Dutch" 13 "Flemish" 14 "Polish" 15 "Czech" 16 "Greek" 17 "Hungarian" 18 "Swedish" 19 "Danish" 20 "Norwegian" 21 "Finish" 22 "EU_Portuguese" 23 "Braz_Portuguese" 24 "Japanese" 25 "AU_English" 26 "Korean" 27 "Mandarin_Chinese" 28 "Taiwanese" 29 "Arabic" 30 "Slovak" 31 "Thai" 32 "Indian_English" 33 "Ukrainian" 34 "Romanian" ;
VAL_ 765 Mc_VehThemeUsrSel_St 0 "Invalid" 1 "Theme_1" 2 "Theme_2" ;
VAL_ 765 Mc_VehDayNightUsrSel_St 0 "Invalid" 1 "Day" 2 "Night" ;
VAL_ 765 EsaOn_B_Rq 0 "Off" 1 "On" ;
VAL_ 765 EngExhMdeQuiet_D_Rq 0 "Null" 1 "LoudExhaust" 2 "QuietExhaust" 3 "Faulty" ;
VAL_ 765 BrkLineLck_D_Rq 0 "NoRequest" 1 "Initiate" 2 "Engage" 3 "Off" ;
VAL_ 765 Running_Board_Cmd 0 "All_Disabled" 1 "All_Enabled" 2 "Manually_Deployed" 3 "Unused" ;
VAL_ 765 Mc_VehUnitTempUsrSel_St 0 "Temperature_deg_c" 1 "Temperature_deg_f" ;
VAL_ 765 Mc_VehUntTrpCoUsrSel_St 0 "TripComputer_metric" 1 "TripComputer_imperial" ;
VAL_ 765 RearDiffLck_D_RqArb 0 "Off" 1 "On" 2 "NotUsed" 3 "Faulty" ;
VAL_ 765 BttOn_B_Rq 0 "Off" 1 "On" ;
VAL_ 765 AwdRnge_D_ActlIpc 0 "Low_Range_Locked" 1 "Low_Range_Auto" 2 "Low_Range_2wd" 3 "Neutral" 4 "High_Range_Locked" 5 "High_Range_Auto" 6 "High_Range_2wd" 7 "Unknown" ;
VAL_ 765 AirSusp_D_RqDrv 0 "NoModeSelected" 1 "Off" 2 "On" 3 "NotUsed" ;
VAL_ 765 DrvInputRequired_B_Rq 0 "No" 1 "Yes" ;
VAL_ 765 Btt_L_Actl 126 "NoDataExists" 127 "Faulty" ;
VAL_ 765 SelDrvMdeTxtReset_B_Rq 0 "No" 1 "Yes" ;
VAL_ 765 SelDrvMdeDsply_B_Avail 0 "NotAvailable" 1 "Available" ;
VAL_ 765 AwdDrvMde_D_Rq 0 "Normal" 1 "Sport" 2 "Weather" 3 "MudAndSand" 4 "Baja" 5 "RockCrawl" 6 "NotAvailable" 7 "Faulty" ;
VAL_ 765 AwdMde_D_RqArb 0 "FourByTwo" 1 "FourByFourAuto" 2 "FourByFourHigh" 3 "FourByFourLow" 4 "Neutral" 5 "NoRequest" 6 "NotUsed2" 7 "Faulty" ;
VAL_ 765 EdmSailMde_B_RqDrv 0 "Off" 1 "On" ;
VAL_ 765 WaitToStartLamp_D_Falt 0 "Wait_to_start_lamp_OK" 1 "Diagnosis_not_ready" 2 "Wait_to_start_lamp_failed" 3 "NotUsed" ;
VAL_ 765 AutoTowAllw_D_RqMnu 0 "NoSelection" 1 "AutoTowHaulDisabled" 2 "AutoTowHaulEnabled" 3 "TowHaulCommandedOn" ;
VAL_ 765 EngExhMdeQuiet_D2_Rq 0 "Null" 1 "Stealth" 2 "Normal" 3 "Sport" 4 "Track" 5 "NotUsed_1" 6 "NotUsed_2" 7 "NotUsed_3" ;
VAL_ 765 BalrSwtch_D_Stat 0 "Null" 1 "NotPressed" 2 "Pressed" 3 "NotUsed" ;
VAL_ 765 BalrMde_D_Rq 0 "Null" 1 "Low" 2 "Medium" 3 "High" ;
VAL_ 765 RstrnOnPsngr_D_RqMnu 0 "NoAction" 1 "NotUsed_1" 2 "NotUsed_2" 3 "NotUsed_3" 4 "NotUsed_4" 5 "Off" 6 "NotUsed_5" 7 "NotUsed_6" 8 "NotUsed_7" 9 "NotUsed_8" 10 "On" 11 "NotUsed_9" 12 "ConfiguredOff" 13 "NotUsed_10" 14 "NotUsed_11" 15 "Faulty" ;
VAL_ 766 McSelMsgId_B_Stat 0 "Invalid" 1 "Valid" ;
VAL_ 766 McSelChoice_D_Stat 0 "Ok" 1 "Choice1" 2 "Choice2" 3 "Choice3" 4 "Choice4" 5 "Choice5" 6 "Choice6" 7 "Choice7" ;
VAL_ 766 McPrsntMsgId_B_Stat 0 "Invalid" 1 "Valid" ;
VAL_ 766 McPrsntActv_D_Stat 0 "Inactive" 1 "ActiveGranted" 2 "UpdateGranted" 3 "Deactivated" 4 "NotUsed_1" 5 "NotUsed_2" 6 "NotUsed_3" 7 "NotUsed_4" ;
VAL_ 766 McCntrStckNotfn_B_Stat 0 "Off" 1 "On" ;
VAL_ 770 ScEnbl_B_Stat 0 "Off" 1 "On" ;
VAL_ 770 BattTracVrtOck_B_Stat 0 "No" 1 "Yes" ;
VAL_ 770 ChrgTrgtSocOvrrd_B_Stat 0 "Off" 1 "On" ;
VAL_ 770 ScChrgrPwMax_Pw_Actl 4095 "Faulty" ;
VAL_ 770 ScPayloadUpdate_B_Stat 0 "Null" 1 "InProcess" 2 "Complete" 3 "NotUsed" ;
VAL_ 772 Memory_Feedback_Rqst 0 "No" 1 "Yes" ;
VAL_ 772 Cancel_Auto_Movement 0 "Null" 1 "Cancel" ;
VAL_ 772 MemDrvDeny_B_Stat 0 "No" 1 "Yes" ;
VAL_ 772 Easy_Entry_Rqst 0 "Null" 1 "Drive" 2 "Easy_Entry" ;
VAL_ 772 SeatSlprPosMsgTxt_B_Rq 0 "Off" 1 "On" ;
VAL_ 772 PwRnngBoardSwtch_D_Stat 0 "Inactive" 1 "AlwaysActive" 2 "DeployUnlocked" 3 "NotUsed" ;
VAL_ 772 SeatScrnDrvOn_B_Rq 0 "Off" 1 "On" ;
VAL_ 772 SeatPos_D_Stat 0 "Null" 1 "EasyEntry" 2 "Pending" 3 "Moving" 4 "Drive" 5 "Error" 6 "NotUsed2" 7 "NotUsed3" ;
VAL_ 772 Memory_Cmd 0 "Null" 1 "Store_1" 2 "Store_2" 3 "Store_3" 4 "Store_4" 5 "Recall_1" 6 "Recall_2" 7 "Recall_3" 8 "Recall_4" ;
VAL_ 772 SeatPosSavDrv_B_Stat 0 "Fail" 1 "Success" ;
VAL_ 772 SeatRelxPosDact_B_Stat 0 "Fail" 1 "Success" ;
VAL_ 772 SeatRelxPosActv_B_Stat 0 "Fail" 1 "Success" ;
VAL_ 772 SeatRelxPosSet_B_Stat 0 "Fail" 1 "Success" ;
VAL_ 772 SeatSlprPosPsngr_D_Stat 0 "Null" 1 "Upright" 2 "Sleeper" 3 "Faulty" ;
VAL_ 772 PwRnngBoardT_D_Stat 0 "Inactive" 1 "Timer1" 2 "Timer2" 3 "NotUsed" ;
VAL_ 772 SteClmnPosDrvMde_D_St 0 "Null" 1 "Forward" 2 "Backward" 3 "NotUsed_1" ;
VAL_ 772 SteClmnPosSav_D_St 0 "Null" 1 "Forward" 2 "Backward" 3 "NotUsed_1" ;
VAL_ 772 SeatMovDrv_D_Stat 0 "Null" 1 "Success" 2 "Pending" 3 "Rejected" 4 "Interrupted" 5 "Failed" 6 "In_Prog" 7 "Invalid" 8 "NotUsed_1" 9 "NotUsed_2" 10 "NotUsed_3" 11 "NotUsed_4" 12 "NotUsed_5" 13 "NotUsed_6" 14 "NotUsed_7" 15 "Faulty" ;
VAL_ 772 SeatMemPosDrv_D_Stat 0 "Null" 1 "WorkStore_1" 2 "WorkStore_2" 3 "WorkStore_3" 4 "WorkStore_4" 5 "RestStore_1" 6 "RestStore_2" 7 "RestStore_3" 8 "RestStore_4" 9 "WorkRecall_1" 10 "WorkRecall_2" 11 "WorkRecall_3" 12 "WorkRecall_4" 13 "RestRecall_1" 14 "RestRecall_2" 15 "RestRecall_3" 16 "RestRecall_4" 17 "NotUsed_1" 18 "NotUsed_2" 19 "NotUsed_3" 20 "NotUsed_4" 21 "NotUsed_5" 22 "NotUsed_6" 23 "NotUsed_7" 24 "NotUsed_8" 25 "NotUsed_9" 26 "NotUsed_10" 27 "NotUsed_11" 28 "NotUsed_12" 29 "NotUsed_13" 30 "NotUsed_14" 31 "NotUsed_15" ;
VAL_ 773 SeatBckInclnPsng_B_St 0 "Null" 1 "Stall" ;
VAL_ 773 StmsScrnPsngrOn_B_Rq 0 "Off" 1 "On" ;
VAL_ 773 SeatPsngrMem_D_Cmd 0 "Null" 1 "STORE_1" 2 "STORE_2" 3 "STORE_3" 4 "STORE_4" 5 "RECALL_1" 6 "RECALL_2" 7 "RECALL_3" 8 "RECALL_4" 9 "NotUsed_1" 10 "NotUsed_2" 11 "NotUsed_3" 12 "NotUsed_4" 13 "NotUsed_5" 14 "NotUsed_6" 15 "NotUsed_7" ;
VAL_ 773 SeatScrnPsngrOn_B_Rq 0 "Off" 1 "On" ;
VAL_ 773 MemSwtchPsngrFdbck_B_Rq 0 "No" 1 "Yes" ;
VAL_ 773 SeatBckInclTopPsn_B_St 0 "Null" 1 "Stall" ;
VAL_ 773 SeatMovDrv_D_Rq 0 "Null" 1 "Forward_Upward_Tap" 2 "Rearward_Downward_Tap" 3 "Forward_Upward_Cont" 4 "Rearward_Downward_Cont" 5 "Cancel" 6 "NotUsed_1" 7 "NotUsed_2" ;
VAL_ 773 SeatMovMdeSel_D_Rq 0 "Null" 1 "Rest_Mode" 2 "Work_Mode" 3 "Drive_Mode" ;
VAL_ 773 SeatAutoSavPsngr_D_St 0 "None" 1 "InProgress" 2 "Major" 3 "Minor" ;
VAL_ 773 PersStorePsngr_D_Stat 0 "Complete" 1 "InProgress" 2 "Null" 3 "NotUsed" ;
VAL_ 773 StwblStewMde_D_Dsply 0 "UNUSED" 1 "UNUSED" 2 "UNUSED" 3 "UNUSED" ;
VAL_ 773 StwblStewMde_D_Stat 0 "UNUSED" 1 "UNUSED" 2 "UNUSED" 3 "UNUSED" 4 "UNUSED" 5 "UNUSED" 6 "UNUSED" 7 "UNUSED" 8 "UNUSED" 9 "UNUSED" 10 "UNUSED" 11 "UNUSED" 12 "UNUSED" 13 "UNUSED" 14 "UNUSED" 15 "UNUSED" ;
VAL_ 773 SeatLmbrExtnPsngr_B_St 0 "Null" 1 "Stall" ;
VAL_ 773 SeatHghtRearPsng_B_St 0 "Null" 1 "Stall" ;
VAL_ 773 SeatHghtFrontPsng_B_St 0 "Null" 1 "Stall" ;
VAL_ 773 SeatHeadrstTltPsn_B_St 0 "Null" 1 "Stall" ;
VAL_ 773 SeatMovPsngr_D_Res 0 "NULL" 1 "SUCCESS" 2 "PENDING" 3 "REJECTED" 4 "INTERRUPTED" 5 "FAILED" 6 "IN_PROG" 7 "INVALID" 8 "NotUsed_1" 9 "NotUsed_2" 10 "NotUsed_3" 11 "NotUsed_4" 12 "NotUsed_5" 13 "NotUsed_6" 14 "NotUsed_7" 15 "Faulty" ;
VAL_ 773 SeatHeadrstHgtPsn_B_St 0 "Null" 1 "Stall" ;
VAL_ 773 SeatThghRExtnPsng_B_St 0 "Null" 1 "Stall" ;
VAL_ 773 SeatThghLExtnPsng_B_St 0 "Null" 1 "Stall" ;
VAL_ 773 SeatSlidPosPsngr_B_St 0 "Null" 1 "Stall" ;
VAL_ 773 SeatLmbrHghtPsngr_B_St 0 "Null" 1 "Stall" ;
VAL_ 773 PersRecallPsng_D_Actl 0 "Complete" 1 "Inprogress" 2 "Null" 3 "NotUsed" ;
VAL_ 773 SeatMovSrvcPsngr_D_Arb 0 "NULL" 1 "LOCAL" 2 "SOA" 3 "NotUsed_1" ;
VAL_ 778 Cta_D_Rq 0 "Off" 1 "On" 2 "NoDataExists" 3 "Unused" ;
VAL_ 778 PrkAidRear_D_RqDrv 0 "Disabled" 1 "Enabled" 2 "Status" 3 "NotUsed" ;
VAL_ 778 PrkAidFront_D_RqDrv 0 "Disabled" 1 "Enabled" 2 "Status" 3 "NotUsed" ;
VAL_ 778 Sod_D_Rq 0 "Off" 1 "BLIS_On_Second_Warning_OFF" 2 "BLIS_On_Second_Warning_ON" 3 "No_Selection_Made" ;
VAL_ 778 SteEffort_D_Rq 0 "Normal" 1 "Sport" 2 "Comfort" 3 "SpecialMode_1" 4 "SpecialMode_2" 5 "NotUsed_1" 6 "NotUsed_2" 7 "NotUsed_3" ;
VAL_ 778 PrkAidAcsyRear_D_RqDrv 0 "Null" 1 "Off" 2 "On" 3 "NotUsed" ;
VAL_ 778 PrkAidAcsyFront_D_RqDrv 0 "Null" 1 "Off" 2 "On" 3 "NotUsed" ;
VAL_ 778 ClrExitAsstEnbl_D_RqDrv 0 "Inactive" 1 "Disable" 2 "Enable" 3 "NotUsed" ;
VAL_ 779 TrlrTireLf_P_Actl 65534 "Invalid" 65535 "NotSupported" ;
VAL_ 779 TrlrTireLm_P_Actl 65534 "Invalid" 65535 "NotSupported" ;
VAL_ 779 TrlrTireLr_P_Actl 65534 "Invalid" 65535 "NotSupported" ;
VAL_ 779 TrlrTireSensLm_D_Stat 0 "Unknown" 1 "Normal" 2 "Low" 3 "Fault" 4 "Alert" 5 "NotUsed1" 6 "NotUsed2" 7 "NotUsed3" 8 "NotUsed4" 9 "NotUsed5" 10 "NotUsed6" 11 "NotUsed7" 12 "NotUsed8" 13 "NotUsed9" 14 "NotUsed10" 15 "NotSupported" ;
VAL_ 779 TrlrTireSensLf_D_Stat 0 "Unknown" 1 "Normal" 2 "Low" 3 "Fault" 4 "Alert" 5 "NotUsed1" 6 "NotUsed2" 7 "NotUsed3" 8 "NotUsed4" 9 "NotUsed5" 10 "NotUsed6" 11 "NotUsed7" 12 "NotUsed8" 13 "NotUsed9" 14 "NotUsed10" 15 "NotSupported" ;
VAL_ 779 TrlrTireSensLr_D_Stat 0 "Unknown" 1 "Normal" 2 "Low" 3 "Fault" 4 "Alert" 5 "NotUsed1" 6 "NotUsed2" 7 "NotUsed3" 8 "NotUsed4" 9 "NotUsed5" 10 "NotUsed6" 11 "NotUsed7" 12 "NotUsed8" 13 "NotUsed9" 14 "NotUsed10" 15 "NotSupported" ;
VAL_ 780 TrlrTireRf_P_Actl 65534 "Invalid" 65535 "NotSupported" ;
VAL_ 780 TrlrTireRm_P_Actl 65534 "Invalid" 65535 "NotSupported" ;
VAL_ 780 TrlrTireRr_P_Actl 65534 "Invalid" 65535 "NotSupported" ;
VAL_ 780 TrlrTireSensRm_D_Stat 0 "Unknown" 1 "Normal" 2 "Low" 3 "Fault" 4 "Alert" 5 "NotUsed1" 6 "NotUsed2" 7 "NotUsed3" 8 "NotUsed4" 9 "NotUsed5" 10 "NotUsed6" 11 "NotUsed7" 12 "NotUsed8" 13 "NotUsed9" 14 "NotUsed10" 15 "NotSupported" ;
VAL_ 780 TrlrTireSensRf_D_Stat 0 "Unknown" 1 "Normal" 2 "Low" 3 "Fault" 4 "Alert" 5 "NotUsed1" 6 "NotUsed2" 7 "NotUsed3" 8 "NotUsed4" 9 "NotUsed5" 10 "NotUsed6" 11 "NotUsed7" 12 "NotUsed8" 13 "NotUsed9" 14 "NotUsed10" 15 "NotSupported" ;
VAL_ 780 TrlrTireSensRr_D_Stat 0 "Unknown" 1 "Normal" 2 "Low" 3 "Fault" 4 "Alert" 5 "NotUsed1" 6 "NotUsed2" 7 "NotUsed3" 8 "NotUsed4" 9 "NotUsed5" 10 "NotUsed6" 11 "NotUsed7" 12 "NotUsed8" 13 "NotUsed9" 14 "NotUsed10" 15 "NotSupported" ;
VAL_ 781 TrlrTireSys_D_Stat 0 "SystemUnknown" 1 "System_Fault" 2 "SensorFault" 3 "TireLow" 4 "SystemActive" 5 "RequestTireCount" 6 "RequestPressureThresh" 7 "TrainLFTire" 8 "TrainRFTire" 9 "TrainRRTire" 10 "TrainRMTire" 11 "TrainLRTire" 12 "TrainLMTire" 13 "TrainingComplete" 14 "TiresNotTrained" 15 "NotUsed" ;
VAL_ 781 Chirp_D_RqTrlr 0 "NoRequest" 1 "Chirp_1" 2 "Chirp_2" 3 "NotUsed" ;
VAL_ 781 TrlrTireCnt_D_Stat 0 "Unconfigured" 1 "TwoTire" 2 "FourTire" 3 "SixTire" 4 "FourTireOneAxle" 5 "EightTire" 6 "TwelveTire" 7 "Faulty" ;
VAL_ 781 TrlrTireDual_D_Stat 0 "SystemUnknown" 1 "OuterTire" 2 "InnerTire" 3 "Invalid" 4 "NotSupported" 5 "NotUsed_1" 6 "NotUsed_2" 7 "NotUsed_3" 8 "NotUsed_4" 9 "NotUsed_5" 10 "NotUsed_6" 11 "NotUsed_7" 12 "NotUsed_8" 13 "NotUsed_9" 14 "NotUsed_10" 15 "NotUsed_11" ;
VAL_ 783 TrlrLearnMdeOn_B_RqDrv 0 "False" 1 "True" ;
VAL_ 783 TrlrTireCnt_D_RqDrv 0 "Unconfigured" 1 "Two_Tire" 2 "Four_Tire" 3 "Six_Tire" 4 "FourTireOneAxle" 5 "EightTire" 6 "TwelveTire" 7 "Faulty" ;
VAL_ 784 TrlrTireLf_T_Actl 254 "Invalid" 255 "NotSupported" ;
VAL_ 784 TrlrTireLm_T_Actl 254 "Invalid" 255 "NotSupported" ;
VAL_ 784 TrlrTireLr_T_Actl 254 "Invalid" 255 "NotSupported" ;
VAL_ 784 TrlrTireRf_T_Actl 254 "Invalid" 255 "NotSupported" ;
VAL_ 784 TrlrTireRm_T_Actl 254 "Invalid" 255 "NotSupported" ;
VAL_ 784 TrlrTireRr_T_Actl 254 "Invalid" 255 "NotSupported" ;
VAL_ 784 TrlrTireTSensLr_D_Stat 0 "NotAvailable" 1 "Normal" 2 "HighTempWarning" 3 "Faulty" ;
VAL_ 784 TrlrTireTSensLm_D_Stat 0 "NotAvailable" 1 "Normal" 2 "HighTempWarning" 3 "Faulty" ;
VAL_ 784 TrlrTireTSensLf_D_Stat 0 "NotAvailable" 1 "Normal" 2 "HighTempWarning" 3 "Faulty" ;
VAL_ 784 TrlrTireTempSys_D_Stat 0 "NotSupported" 1 "Normal" 2 "HighTempWarning" 3 "Faulty" ;
VAL_ 784 TrlrTireTSensRr_D_Stat 0 "NotAvailable" 1 "Normal" 2 "HighTempWarning" 3 "Faulty" ;
VAL_ 784 TrlrTireTSensRm_D_Stat 0 "NotAvailable" 1 "Normal" 2 "HighTempWarning" 3 "Faulty" ;
VAL_ 784 TrlrTireTSensRf_D_Stat 0 "NotAvailable" 1 "Normal" 2 "HighTempWarning" 3 "Faulty" ;
VAL_ 785 BattTracLoThres_D_Stat 0 "Null" 1 "Thres20mi_32km" 2 "Thres30mi_48km" 3 "Thres50mi_80km" 4 "Thres30km_18mi" 5 "Thres50km_31mi" 6 "Thres80km_50mi" 7 "NotUsed" ;
VAL_ 785 BattTracLoSoc_D_Dsply 0 "Null" 1 "LoDte" 2 "ZeroDteDepletedBattery" 3 "NotUsed" ;
VAL_ 785 BattTracLoMsgTxt_D_Rq 0 "Null" 1 "LowDteFirstAlert" 2 "LowDteSecondAlert" 3 "ClimateLowDteFirstAlert" 4 "ClimateLowDteSecondAlert" 5 "ZeroDteBatteryDepleted" 6 "NotUsed_1" 7 "NotUsed_2" ;
VAL_ 785 PwPckTqRdyChime_B_Rq 0 "Null" 1 "Startup" 2 "Shutdown" 3 "NotUsed" ;
VAL_ 785 RgenAnimation_B_Dsply 0 "Inactive" 1 "Active" ;
VAL_ 785 EcoIdl_D_Stat 0 "Null" 1 "Disabled" 2 "Enabled" 3 "NotUsed" ;
VAL_ 785 BattElecPerf_D2_Actl 0 "NoMessage" 1 "LimitedPerf_BatteryTe" 2 "SeverelyLimPerf_BatteryTe" 3 "LimitedPerf_MotorTe" 4 "SeverelyLimPerf_MotorTe" 5 "LimitedPerformance" 6 "SeverelyLimitedPerformance" 7 "NotUsed" ;
VAL_ 785 VehPerfDemo_D_Stat 0 "Inactive" 1 "Active" 2 "NotReady" 3 "NotUsed" ;
VAL_ 785 DteVehOffstMsgTxt_D_Rq 0 "NoMessage" 1 "DestinationRoute" 2 "HillyTerrain" 3 "ExternalTemperature" 4 "TrafficAlongRoute" 5 "TrailerTowing_On" 6 "TrailerTowing_Off" 7 "Payload" 8 "PowerToTheBox" 9 "NotUsed_1" 10 "NotUsed_2" 11 "NotUsed_3" 12 "NotUsed_4" 13 "NotUsed_5" 14 "NotUsed_6" 15 "NotUsed_7" ;
VAL_ 785 DteVehOffst_L_Dsply 8190 "NoDataExists" 8191 "Faulty" ;
VAL_ 785 VehVLimMsgTxt_B_Rq 0 "No" 1 "Yes" ;
VAL_ 785 BattTracLimPerf_D_Dsply 0 "NoDisplay" 1 "LimitedPerformance" 2 "SeverelyLimitedPerformance" 3 "NotUsed" ;
VAL_ 786 VehElRngeCyc_L_Dsply 4094 "NoDataExists" 4095 "Faulty" ;
VAL_ 786 VehElRnge_L2_Dsply 8190 "NoDataExists" 8191 "Faulty" ;
VAL_ 786 PtDataKeyId_D_Stat 0 "Null" 1 "Cust_1_Stat" 2 "Cust_2_Stat" 3 "Cust_3_Stat" 4 "Cust_4_Stat" 5 "Tot_Veh_Stat" 6 "Cust_1_NUT" 7 "Cust_2_NUT" 8 "Cust_3_NUT" 9 "Cust_4_NUT" 10 "Tot_Veh_NUT" 11 "NotUsed1" 12 "NotUsed2" 13 "NotUsed3" 14 "NotUsed4" 15 "NotUsed5" ;
VAL_ 786 ChrgStat_D_Dsply 0 "Not_Ready" 1 "Fault_Unknown_Location" 2 "Fault_Inside_Car" 3 "Fault_Outside_Car" 4 "In_Progress" 5 "Scheduled" 6 "Complete" 7 "NotUsed" ;
VAL_ 786 RgenTrip_L_Dsply 65534 "NoDataExists" 65535 "Fault" ;
VAL_ 787 PwTgateStepMsgTxt_B_Rq 0 "NoMessage" 1 "DisplayMessage" ;
VAL_ 787 DrTGate_D_Rq 0 "Not_Moving" 1 "Opening" 2 "Closing" 3 "NotUsed" ;
VAL_ 787 Power_Liftgate_Mode_Stt 0 "Disabled" 1 "Enabled" 2 "Unused" 3 "Not_Supported" ;
VAL_ 787 PwLftgtIntSw_B_Stat 0 "Null" 1 "Pressed" ;
VAL_ 787 PwTgateMsgTxt_B_Rq 0 "NoMessage" 1 "DisplayMessage" ;
VAL_ 787 PwTgateLamp_B_Rq 0 "Off" 1 "On" ;
VAL_ 787 PwTgateInhbtMsgTxt_B_Rq 0 "NoMessage" 1 "DisplayMessage" ;
VAL_ 787 DrTgateChime2_D_Rq 0 "Off" 1 "Long" 2 "Short" 3 "Fast" 4 "Long_Repeated" 5 "NotUsed1" 6 "NotUsed2" 7 "NotUsed3" ;
VAL_ 787 DrMatLamp_B_Rq 0 "Off" 1 "On" ;
VAL_ 787 DrTgatePos_Pc_Actl 126 "NoDataExists" 127 "Faulty" ;
VAL_ 787 DrMatAjarMsgTxt_B_Rq 0 "NoMessage" 1 "DisplayMessage" ;
VAL_ 787 DrMatInhbt_B_Rq 0 "No_Inhibit" 1 "Inhibit" ;
VAL_ 787 DrMatInhbtMsgTxt_B_Rq 0 "NoMessage" 1 "DisplayMessage" ;
VAL_ 787 BecManCloseMsgTxt_D_Rq 0 "NoMessage" 1 "Message_1" 2 "Message_2" 3 "Message_3" ;
VAL_ 787 BecAjarMsgTxt_D_Rq 0 "NoMessage" 1 "Message_1" 2 "Message_2" 3 "Message_3" ;
VAL_ 787 BecConfg_D_Stat 0 "Disabled" 1 "Enabled" 2 "Not_Used" 3 "NotSupported" ;
VAL_ 787 Bec2Ajar_B_Stat 0 "Closed" 1 "Ajar" ;
VAL_ 787 AvPwLftgtChime_D_Rq 0 "Inactive" 1 "AvEventOpen" 2 "AvEventClose" 3 "AvEventOpenObstructed" 4 "AvEventCloseObstructed" 5 "NotUsed_1" 6 "NotUsed_2" 7 "NotUsed_3" ;
VAL_ 789 VehElSurpStat_L_Dsply 8190 "Data_Not_Available" 8191 "Faulty" ;
VAL_ 789 TripSum_L_Dsply 65534 "Data_Not_Available_" 65535 "Faulty" ;
VAL_ 789 TripSum_E_Dsply 510 "Data_Not_Available" 511 "Faulty" ;
VAL_ 791 BattElEmotive_Pc_Dsply 1022 "NoDataExists" 1023 "Faulty" ;
VAL_ 791 EcoMde_D_RqMnu 0 "Null" 1 "Off" 2 "On" 3 "NotUsed" ;
VAL_ 791 ChargeProfIDPref_Rq 0 "Inactive" 1 "ChargeNow" 2 "Value" 3 "NotUsed" ;
VAL_ 791 HybMdeOvrrd_D_Rq 0 "Null" 1 "Override" 2 "Invalid" 3 "NotUsed" ;
VAL_ 791 StopStrtVThres_D_RqMnu 0 "NoSelection" 1 "Low" 2 "Medium" 3 "High" ;
VAL_ 791 AwdDrvMde_D2_Rq 0 "Normal" 1 "Sport" 2 "Weather" 3 "MudAndSand" 4 "Baja" 5 "RockCrawl" 6 "TowHaul" 7 "NotAvailable" 8 "NotUsed_1" 9 "NotUsed_2" 10 "NotUsed_3" 11 "NotUsed_4" 12 "NotUsed_5" 13 "NotUsed_6" 14 "NotUsed_7" 15 "Faulty" ;
VAL_ 791 GrdAsstAllw_D_RqMnu 0 "NoModeSelected" 1 "Off" 2 "On" 3 "NotUsed" ;
VAL_ 791 EngAirFilt_B_RqReset 0 "No" 1 "Yes" ;
VAL_ 791 LongTermReset_B_Rq 0 "Off" 1 "On" ;
VAL_ 791 GpsElMdeSel_B_Rq 0 "Off" 1 "On" ;
VAL_ 791 EcoCcActv_B_Rq 0 "Off" 1 "On" ;
VAL_ 791 EmotiveType_D_Dsply 0 "Null" 1 "EmotiveDisplay_1" 2 "EmotiveDisplay_2" 3 "EmotiveDisplay_3" ;
VAL_ 791 PlgOvrrdStrt_D_Cmd 0 "Null_State" 1 "Dont_Override_Plug_Status" 2 "Override_Plug_Status" 3 "NotUsed" ;
VAL_ 791 DrvEffLvl_No_Stat 62 "NoDataExists" 63 "Fault" ;
VAL_ 791 VehElEffTrip2Reset_B_Rq 0 "Off" 1 "On" ;
VAL_ 791 VehElEffTrip1Reset_B_Rq 0 "Off" 1 "On" ;
VAL_ 792 ElLongTerm_L_Dsply 16777214 "No_Data_Exists" 16777215 "Fault" ;
VAL_ 792 ElTrip_L_Dsply 65534 "No_Data_Exists" 65535 "Fault" ;
VAL_ 792 DsplyChkActv_B_Stat 0 "Inactive" 1 "Active" ;
VAL_ 792 FmesSndShrt_D_Stat 0 "Inactive" 1 "NotAccepted" 2 "Accepted" 3 "NotUsed_1" ;
VAL_ 801 DrvDsplyPalette_D_Stat 0 "Null" 1 "AutoDay" 2 "AutoNight" 3 "ManualDay" 4 "ManualNightBright" 5 "ManualNightDark" 6 "NotUsed_2" 7 "NotUsed_3" ;
VAL_ 801 CDWarnChime_St 0 "Off" 1 "On" ;
VAL_ 801 HardWarning 0 "Chime_Off" 1 "Chime_On" ;
VAL_ 801 SoftWarning 0 "Chime_Off" 1 "Chime_On" ;
VAL_ 801 InfoWarning 0 "Chime_Off" 1 "Chime_On" ;
VAL_ 802 AvgFeTrip2Actv_B_Dsply 0 "Inactive" 1 "Active" ;
VAL_ 802 AvgFeTrip1Actv_B_Dsply 0 "Inactive" 1 "Active" ;
VAL_ 802 AvgFeTripUnit_D_Stat 0 "Inactive" 1 "MilePerGallon" 2 "KilometerPerLiter" 3 "LiterPer100kilometer" 4 "NotUsed_1" 5 "NotUsed_2" 6 "NotUsed_3" 7 "NotUsed_4" 8 "NotUsed_5" 9 "NotUsed_6" 10 "NotUsed_7" 11 "NotUsed_8" 12 "NotUsed_9" 13 "NotUsed_10" 14 "NotUsed_11" 15 "NotUsed_12" ;
VAL_ 802 AvgFeActv_B_Dsply 0 "Inactive" 1 "Active" ;
VAL_ 803 DistTripUnit_D_Stat 0 "Inactive" 1 "Kilometers" 2 "Miles" 3 "NotUsed" ;
VAL_ 804 ConsInstUnit_D_Stat 0 "Inactive" 1 "GallonPerHour" 2 "LiterPerHour" 3 "NotUsed" ;
VAL_ 804 ConsInstActv_B_Dsply 0 "Inactive" 1 "Active" ;
VAL_ 805 InstFeTripUnit_D_Stat 0 "Inactive" 1 "MilePerGallon" 2 "KilometerPerLiter" 3 "LiterPer100kilometer" 4 "NotUsed_1" 5 "NotUsed_2" 6 "NotUsed_3" 7 "NotUsed_4" 8 "NotUsed_5" 9 "NotUsed_6" 10 "NotUsed_7" 11 "NotUsed_8" 12 "NotUsed_9" 13 "NotUsed_10" 14 "NotUsed_11" 15 "NotUsed_12" ;
VAL_ 806 SnowPlowMde_B_Enbl 0 "Disable" 1 "Enable" ;
VAL_ 806 StopStrtDrvMde_B_RqBtn 0 "Not_Pressed" 1 "Pressed" ;
VAL_ 806 WndwFrontHeat_B_Stat 0 "Off" 1 "On" ;
VAL_ 806 ClimtPw_B_Rq 0 "No" 1 "Yes" ;
VAL_ 806 HtrCorePump_B_Rq 0 "Off" 1 "On" ;
VAL_ 806 HvacAirCond_B_Rq 0 "No" 1 "Yes" ;
VAL_ 806 HvacEvap_Te_Actl 1023 "Fault" ;
VAL_ 806 ClimtHeat_D_Rq 0 "NoHeatingRequest" 1 "OpportunisticHeatingReq" 2 "FastTempPullDownHeatingReq" 3 "Defrost_Defog" 4 "PtcHtrTestMde" 5 "HtrCoreClntFlwOnly" 6 "NotUsed3" 7 "NotUsed4" ;
VAL_ 806 ClimtCool_D_Rq 0 "NoCoolingRequest" 1 "OpportunisticCoolingReq" 2 "FastTempPullDownCoolReq" 3 "Defrost_Defog" 4 "ElACTestMde" 5 "NotUsed2" 6 "NotUsed3" 7 "NotUsed4" ;
VAL_ 806 ClimtDeltaLoad_Pw_Actl 62 "NoDataExists" 63 "Faulty" ;
VAL_ 806 AirAmb_Te_RqCld 0 "NoRequest" 1 "Request" ;
VAL_ 806 ClimtHeatRear_D_Rq 0 "NoHeatingRequest" 1 "OpportunisticHeatingReq" 2 "FastTempPullDownHeatingReq" 3 "Defrost_Defog" 4 "PtcHtrTestMde" 5 "HtrCoreClntFlwOnly" 6 "NotUsed3" 7 "NotUsed4" ;
VAL_ 806 ClimtCoolRear_B_Rq 0 "Off" 1 "On" ;
VAL_ 807 ElDistTripCur_No_Dsply 0 "0_second" ;
VAL_ 807 ElDistTripUnit_D_Stat 0 "Inactive" 1 "Kilometers" 2 "Miles" 3 "NotUsed" ;
VAL_ 810 ExtLghtDsply_B_StatArb 0 "Off" 1 "On" ;
VAL_ 810 ScOnb_D_Rq 0 "Null" 1 "Offboard" 2 "Onboard" 3 "NotUsed_1" ;
VAL_ 810 OneTEditActv_B_RqCld 0 "No" 1 "Yes" ;
VAL_ 811 ExtLghtLeft_D_RqMnu 0 "Reset" 1 "PressToOff1" 2 "PressToOn1" 3 "PressToOff2" 4 "PressToOn2" 5 "PressToOff3" 6 "PressToOn3" 7 "NotUsed" ;
VAL_ 811 ExtLghtFront_D_RqMnu 0 "Reset" 1 "PressToOff1" 2 "PressToOn1" 3 "PressToOff2" 4 "PressToOn2" 5 "PressToOff3" 6 "PressToOn3" 7 "NotUsed" ;
VAL_ 811 ExtLghtDsply_D_Stat 0 "Reset" 1 "PressToOff1" 2 "PressToOn1" 3 "PressToOff2" 4 "PressToOn2" 5 "PressToOff3" 6 "PressToOn3" 7 "NotUsed" ;
VAL_ 811 AutoLghtOvrrd_B_RqDrv 0 "NotAllowed" 1 "Allowed" ;
VAL_ 811 ExtLghtRight_D_RqMnu 0 "Reset" 1 "PressToOff1" 2 "PressToOn1" 3 "PressToOff2" 4 "PressToOn2" 5 "PressToOff3" 6 "PressToOn3" 7 "NotUsed" ;
VAL_ 811 ExtLghtRear_D_RqMnu 0 "Reset" 1 "PressToOff1" 2 "PressToOn1" 3 "PressToOff2" 4 "PressToOn2" 5 "PressToOff3" 6 "PressToOn3" 7 "NotUsed" ;
VAL_ 811 OnePdlDrvButtn_B_Falt 0 "NotFaulted" 1 "Faulted" ;
VAL_ 811 LongTermReset_B_RqMnu 0 "Off" 1 "On" ;
VAL_ 811 DistToStopover_L_Actl 65535 "Faulty" ;
VAL_ 811 GoTEditHr_T_RqMnu 30 "NoDataExists" 31 "Faulty" ;
VAL_ 811 StopoverType_D_Stat 0 "Null" 1 "FinalDestination" 2 "ChargeStation" 3 "Home" 4 "Work" 5 "Other" 6 "NotUsed_1" 7 "Faulty" ;
VAL_ 811 OnePdlDrvButtn_B_Stat 0 "Not_Pressed" 1 "Pressed" ;
VAL_ 811 ScMnSoc_Pc_RqMnu 126 "NoDataExists" 127 "Faulty" ;
VAL_ 811 ScEnbl_D_RqMnu 0 "Null" 1 "Off" 2 "On" 3 "NotUsed" ;
VAL_ 811 SpeedoMajorUnit_D_Confg 0 "Null" 1 "Mph" 2 "Kph" 3 "NotUsed" ;
VAL_ 811 GoTEditMnte_T_RqMnu 0 "Minute_0" 1 "Minute_5" 2 "Minute_10" 3 "Minute_15" 4 "Minute_20" 5 "Minute_25" 6 "Minute_30" 7 "Minute_35" 8 "Minute_40" 9 "Minute_45" 10 "Minute_50" 11 "Minute_55" 12 "NotUsed_1" 13 "NotUsed_2" 14 "NoDataExists" 15 "Faulty" ;
VAL_ 812 TimerTrip1_T_Dsply 0 "0_second" ;
VAL_ 812 TimerTrip2_T_Dsply 0 "0_second" ;
VAL_ 813 TimerTripCurnt_T_Dsply 0 "0_second" ;
VAL_ 816 KeyPadCodeDgt2_D_Stat 0 "EndofString" 1 "Button1_2or1" 2 "Button2" 3 "Button3_4or3" 4 "Button4" 5 "Button5_6or5" 6 "Button6" 7 "Button7_8or7" 8 "Button8" 9 "Button9_0or9" 10 "Button0" 11 "Button7_8and9_0" 12 "NotUsed_1" 13 "NotUsed_2" 14 "NotUsed_3" 15 "NotUsed_4" ;
VAL_ 816 KeyPadCodeDgt1_D_Stat 0 "EndofString" 1 "Button1_2or1" 2 "Button2" 3 "Button3_4or3" 4 "Button4" 5 "Button5_6or5" 6 "Button6" 7 "Button7_8or7" 8 "Button8" 9 "Button9_0or9" 10 "Button0" 11 "Button7_8and9_0" 12 "NotUsed_1" 13 "NotUsed_2" 14 "NotUsed_3" 15 "NotUsed_4" ;
VAL_ 816 KeyPadCodeDgt4_D_Stat 0 "EndofString" 1 "Button1_2or1" 2 "Button2" 3 "Button3_4or3" 4 "Button4" 5 "Button5_6or5" 6 "Button6" 7 "Button7_8or7" 8 "Button8" 9 "Button9_0or9" 10 "Button0" 11 "Button7_8and9_0" 12 "NotUsed_1" 13 "NotUsed_2" 14 "NotUsed_3" 15 "NotUsed_4" ;
VAL_ 816 KeyPadCodeDgt3_D_Stat 0 "EndofString" 1 "Button1_2or1" 2 "Button2" 3 "Button3_4or3" 4 "Button4" 5 "Button5_6or5" 6 "Button6" 7 "Button7_8or7" 8 "Button8" 9 "Button9_0or9" 10 "Button0" 11 "Button7_8and9_0" 12 "NotUsed_1" 13 "NotUsed_2" 14 "NotUsed_3" 15 "NotUsed_4" ;
VAL_ 816 KeyPadCodeDgt6_D_Stat 0 "EndofString" 1 "Button1_2or1" 2 "Button2" 3 "Button3_4or3" 4 "Button4" 5 "Button5_6or5" 6 "Button6" 7 "Button7_8or7" 8 "Button8" 9 "Button9_0or9" 10 "Button0" 11 "Button7_8and9_0" 12 "NotUsed_1" 13 "NotUsed_2" 14 "NotUsed_3" 15 "NotUsed_4" ;
VAL_ 816 KeyPadCodeDgt5_D_Stat 0 "EndofString" 1 "Button1_2or1" 2 "Button2" 3 "Button3_4or3" 4 "Button4" 5 "Button5_6or5" 6 "Button6" 7 "Button7_8or7" 8 "Button8" 9 "Button9_0or9" 10 "Button0" 11 "Button7_8and9_0" 12 "NotUsed_1" 13 "NotUsed_2" 14 "NotUsed_3" 15 "NotUsed_4" ;
VAL_ 816 DcacPwResetScnd_B_Rq 0 "Null" 1 "Reset" ;
VAL_ 816 CntrStk2_D_RqAssoc 0 "Check_KeyCode" 1 "Erase_KeyCode" 2 "Key" 3 "Null" 4 "RKE" 5 "Set_Keycode" 6 "Cancel" 7 "Unused_2" ;
VAL_ 816 KeyPadCodeDgt7_D_Stat 0 "EndofString" 1 "Button1_2or1" 2 "Button2" 3 "Button3_4or3" 4 "Button4" 5 "Button5_6or5" 6 "Button6" 7 "Button7_8or7" 8 "Button8" 9 "Button9_0or9" 10 "Button0" 11 "Button7_8and9_0" 12 "NotUsed_1" 13 "NotUsed_2" 14 "NotUsed_3" 15 "NotUsed_4" ;
VAL_ 816 DcacLoFuelLim_L_RqMnu 510 "NoDataExists" 511 "Faulty" ;
VAL_ 816 NfcMyKeyCreate_D_Rq 0 "Null" 1 "Request" ;
VAL_ 816 DcacZone2Pw_D_Rq 0 "Null" 1 "Off" 2 "On" 3 "NotUsed" ;
VAL_ 816 DcacAllZone_D_Rq 0 "Null" 1 "Off" 2 "On" 3 "NotUsed" ;
VAL_ 816 KeylessIdl_D_Rq 0 "Inactive" 1 "Active" 2 "IgnitionOff" 3 "Cancel" ;
VAL_ 816 DgtlKeyPrflAssoc_D_Rq 0 "Null" 1 "EnterKeyAssociation" 2 "ExitKeyAssociation" 3 "DisassociateKey1" 4 "DisassociateKey2" 5 "DisassociateKey3" 6 "DisassociateKey4" 7 "OverwriteKey" ;
VAL_ 816 DcacPwScnd_D_Rq 0 "Null" 1 "Off" 2 "Low" 3 "High" ;
VAL_ 816 DcacZone3Pw_D_Rq 0 "Null" 1 "Off" 2 "On" 3 "NotUsed" ;
VAL_ 816 HybMdeSel_D_Rq 0 "Null" 1 "EV_Auto_Mode" 2 "EV_Now_Mode" 3 "EV_Later_Mode" 4 "EV_Charge_Mode" 5 "EV_Override_Mode" 6 "No_Mode_Requested" 7 "NotUsed_1" ;
VAL_ 816 Dimming_Lvl_RqMnu 0 "NotPressed" 1 "Night_1" 2 "Night_2" 3 "Night_3" 4 "Night_4" 5 "Night_5" 6 "Night_6" 7 "Night_7" 8 "Night_8" 9 "Night_9" 10 "Night_10" 11 "Night_11" 12 "Night_12" 13 "Day_1" 14 "Day_2" 15 "Day_3" 16 "Day_4" 17 "Day_5" 18 "Day_6" 19 "Down" 20 "Up" 21 "NotUsed_1" 22 "NotUsed_2" 23 "NotUsed_3" 24 "NotUsed_4" 25 "NotUsed_5" 26 "NotUsed_6" 27 "NotUsed_7" 28 "NotUsed_8" 29 "NotUsed_9" 30 "NotUsed_10" 31 "NotUsed_11" ;
VAL_ 817 Power_Liftgate_Rqst 0 "Null" 1 "Active" ;
VAL_ 817 Power_Decklid_Rqst 0 "Null" 1 "Active" ;
VAL_ 817 LockInhibit 0 "No_Inhibit" 1 "Inhibit" ;
VAL_ 817 L_Pwr_Sliding_Dr_Rqst 0 "Null" 1 "Active" ;
VAL_ 817 FobComm_D_Stat 0 "Null" 1 "RemEngStartFail" 2 "RemEngStartOK" 3 "NotUsed" ;
VAL_ 817 CamperMde_D_Stat 0 "Disabled" 1 "Enabled" 2 "NotUsed_1" 3 "Faulty" ;
VAL_ 817 DrTgateExtSwMde_B_Stat 0 "Disable" 1 "Enable" ;
VAL_ 817 Veh_Lock_Status 0 "LOCK_DBL" 1 "LOCK_ALL" 2 "UNLOCK_ALL" 3 "UNLOCK_DRV" ;
VAL_ 817 WindowLockout_B_Stat 0 "Unlock" 1 "Locked" ;
VAL_ 817 R_Pwr_Sliding_Dr_Rqst 0 "Null" 1 "Active" ;
VAL_ 817 Lockmsgtxt_D_Rq 0 "NO_WARNING" 1 "MSG1" 2 "MSG2" 3 "MSG3" 4 "MSG4" 5 "MSG5" 6 "MSG6" 7 "MSG7" ;
VAL_ 817 Remote_Device_Feedback 0 "Null" 1 "Acknowledge" 2 "Starting" 3 "Running" 4 "Shutdown" 5 "Unused1" 6 "Unused2" 7 "Unused3" ;
VAL_ 817 Veh_Lock_Requestor 0 "Null" 1 "Autolock" 2 "Auto_Unlock" 3 "Interior" 4 "Key_Cylinder" 5 "Keypad" 6 "Powerslide" 7 "Programming" 8 "Remote" 9 "Passive" 10 "Sliding_Door" 11 "Smart_Unlock" 12 "RemoteStart" 13 "Autorelock" 14 "Passive_Smart_Unlock" 15 "Passport" 16 "SYNC" 17 "Slam_Lock_Protect" 18 "Passive_Driver" 19 "Passive_Pasenger" 20 "Double_Lock" 21 "Child_Lock" 22 "Console_Lock" 23 "Diagnostics" 24 "Transit_Ajar_Lock" 25 "Transit_Cargo_Relock" 26 "Transit_Vehicle_Relock" 27 "Boundary_Alert" 28 "Rgtm_Shutlock_Switch" 29 "DoorsOffToOn_Smart_Unlock" 30 "Remote_Park_Assist" 31 "Walk_Away_Locking" ;
VAL_ 817 ChildLckMde_B_Stat 0 "Disable" 1 "Enable" ;
VAL_ 817 VehLckInd_D_Rq 0 "Off" 1 "On_Night" 2 "On_Day" 3 "NotUsed" ;
VAL_ 817 DrTgateOpen_B_Rq 0 "Null" 1 "Open" ;
VAL_ 817 Veh_Lock_Sub_Id 0 "Null" 1 "Customer_1" 2 "Customer_2" 3 "Customer_3" 4 "Customer_4" 5 "Customer_5" 6 "Customer_6" 7 "Customer_7" 8 "Customer_8" 9 "Unused1" 10 "Unused2" 11 "Unused3" 12 "Unused4" 13 "Unused5" 14 "Unused6" 15 "Unused7" ;
VAL_ 818 WndwDrvSide_D_Stat 0 "NoWindows_Operating" 1 "FrontWindow_Operating" 2 "RearWindow_Operating" 3 "BothWindow_Operating" ;
VAL_ 818 KeyCylSwDrvDr_D_Stat 0 "Null" 1 "Lock" 2 "Unlock" 3 "NotUsed" ;
VAL_ 818 Driver_Lock_Sw_Stat 0 "Null" 1 "Lock" 2 "Unlock" 3 "Invalid" ;
VAL_ 818 ChildLckPw_D_Rq 0 "Null" 1 "Active" ;
VAL_ 818 ChildLckFdbckRd_B_Stat 0 "Unlock" 1 "Locked" ;
VAL_ 818 DrvSpotLight_B_Stat 0 "Inactive" 1 "Active" ;
VAL_ 818 WndwUpDrvRear_D_Falt 0 "Null" 1 "NoFault" 2 "Fault" 3 "NotUsed" ;
VAL_ 818 WndwUpDrvFront_D_Falt 0 "Null" 1 "NoFault" 2 "Fault" 3 "NotUsed" ;
VAL_ 818 RvrseMirrorChime_B_Rq 0 "No" 1 "Yes" ;
VAL_ 818 BLISLEDStatDriverSide 0 "Off" 1 "On" 2 "Unused" 3 "Fault" ;
VAL_ 818 DrDrvMsgTxt_B_Rq 0 "No" 1 "Yes" ;
VAL_ 818 DrPrsntRearDrv_D_Stat 0 "NotDetermined" 1 "NotPresent" 2 "Present" 3 "Faulty" ;
VAL_ 818 DrPrsntDrv_D_Stat 0 "NotDetermined" 1 "NotPresent" 2 "Present" 3 "Faulty" ;
VAL_ 818 DrHandleOuterFl_D_StMa 0 "None" 1 "Deploy" 2 "Flush" 3 "DeployFault1" 4 "DeployFault2" 5 "FlushFault" 6 "Deploying" 7 "Retracting" ;
VAL_ 818 DrHandleOuterRl_D_StMa 0 "None" 1 "Deploy" 2 "Flush" 3 "DeployFault1" 4 "DeployFault2" 5 "FlushFault" 6 "Deploying" 7 "Retracting" ;
VAL_ 819 Memory_1_SwPsngr_Stat 0 "Null" 1 "Pressed" ;
VAL_ 819 BLISLEDStatPassSide 0 "Off" 1 "On" 2 "Unused" 3 "Fault" ;
VAL_ 819 WndwPsngrSide_D_Stat 0 "NoWindows_Operating" 1 "FrontWindow_Operating" 2 "RearWindow_Operating" 3 "BothWindow_Operating" ;
VAL_ 819 Pasngr_Lock_Sw_Stat 0 "Null" 1 "Lock" 2 "Unlock" 3 "Invalid" ;
VAL_ 819 ChildLckFdbckRp_B_Stat 0 "Unlock" 1 "Locked" ;
VAL_ 819 DrPrsntPsngr_D_Stat 0 "NotDetermined" 1 "NotPresent" 2 "Present" 3 "Faulty" ;
VAL_ 819 WndwUpPsngrRear_D_Falt 0 "Null" 1 "NoFault" 2 "Fault" 3 "NotUsed" ;
VAL_ 819 WndwUpPsngrFront_D_Falt 0 "Null" 1 "NoFault" 2 "Fault" 3 "NotUsed" ;
VAL_ 819 Memory_3_SwPsngr_Stat 0 "Null" 1 "Pressed" ;
VAL_ 819 Memory_2_SwPsngr_Stat 0 "Null" 1 "Pressed" ;
VAL_ 819 DrPsngrMsgTxt_B_Rq 0 "No" 1 "Yes" ;
VAL_ 819 DrPrsntRearPsngr_D_Stat 0 "NotDetermined" 1 "NotPresent" 2 "Present" 3 "Faulty" ;
VAL_ 819 DrHandleOuterFr_D_StMa 0 "None" 1 "Deploy" 2 "Flush" 3 "DeployFault1" 4 "DeployFault2" 5 "FlushFault" 6 "Deploying" 7 "Retracting" ;
VAL_ 819 DrHandleOuterRr_D_StMa 0 "None" 1 "Deploy" 2 "Flush" 3 "DeployFault1" 4 "DeployFault2" 5 "FlushFault" 6 "Deploying" 7 "Retracting" ;
VAL_ 820 HeadLghtHiOn_B_StatHcm 0 "Off" 1 "On" ;
VAL_ 820 TailLghtAnmtn_D_Stat 0 "Null" 1 "Type1" 2 "Type2" 3 "Type3" 4 "Type4" 5 "Type5" 6 "Type6" 7 "NotUsed_1" 8 "NotUsed_2" 9 "NotUsed_3" 10 "NotUsed_4" 11 "NotUsed_5" 12 "NotUsed_6" 13 "NotUsed_7" 14 "NotUsed_8" 15 "Faulty" ;
VAL_ 820 TurnLampFrOut_B_Stat 0 "Null" 1 "Out" ;
VAL_ 820 TurnLampFlOut_B_Stat 0 "Null" 1 "Out" ;
VAL_ 820 Adaptive_Hdlmp_Fault 0 "No" 1 "Yes" ;
VAL_ 820 HeadLampLoFlOut_B_Stat 0 "Null" 1 "Out" ;
VAL_ 820 HeadLampLoFrOut_B_Stat 0 "Null" 1 "Out" ;
VAL_ 820 DgtlShadeAr2_D_Stat 0 "Null" 1 "OnClear" 2 "OffShade" 3 "AutoClear" 4 "AutoShade" 5 "NotUsed_1" 6 "NotUsed_2" 7 "NotUsed_3" ;
VAL_ 820 DgtlShadeAr1_D_Stat 0 "Null" 1 "OnClear" 2 "OffShade" 3 "AutoClear" 4 "AutoShade" 5 "NotUsed_1" 6 "NotUsed_2" 7 "NotUsed_3" ;
VAL_ 820 DgtlShadeAr4_D_Stat 0 "Null" 1 "OnClear" 2 "OffShade" 3 "AutoClear" 4 "AutoShade" 5 "NotUsed_1" 6 "NotUsed_2" 7 "NotUsed_3" ;
VAL_ 820 DgtlShadeAr3_D_Stat 0 "Null" 1 "OnClear" 2 "OffShade" 3 "AutoClear" 4 "AutoShade" 5 "NotUsed_1" 6 "NotUsed_2" 7 "NotUsed_3" ;
VAL_ 820 DgtlShadeAr6_D_Stat 0 "Null" 1 "OnClear" 2 "OffShade" 3 "AutoClear" 4 "AutoShade" 5 "NotUsed_1" 6 "NotUsed_2" 7 "NotUsed_3" ;
VAL_ 820 DgtlShadeAr5_D_Stat 0 "Null" 1 "OnClear" 2 "OffShade" 3 "AutoClear" 4 "AutoShade" 5 "NotUsed_1" 6 "NotUsed_2" 7 "NotUsed_3" ;
VAL_ 820 DrDefeatMde_B_Stat 0 "Disable" 1 "Enable" ;
VAL_ 820 HeadLghtDrvSide_B_Stat 0 "Right_Hand_Traffic" 1 "Left_Hand_Traffic" ;
VAL_ 820 DgtlShadeMde_D_Stat 0 "Null" 1 "AllOnClear" 2 "AllOffShade" 3 "Pattern" 4 "Auto" 5 "ManualMode" 6 "NotUsed_1" 7 "NotUsed_2" ;
VAL_ 820 AhbStatGfhbFdbk_D_Actl 0 "GfhbUnavailable" 1 "GfhbHighBeamOff" 2 "GfhbHighBeamPartlyOn" 3 "GfhbHighBeamFullyOn" ;
VAL_ 826 Mirror_Manual_Override 0 "Null" 1 "Override" ;
VAL_ 826 Memory_3_Sw_Stat 0 "Null" 1 "Pressed" ;
VAL_ 826 Memory_2_Sw_Stat 0 "Null" 1 "Pressed" ;
VAL_ 826 Memory_1_Sw_Stat 0 "Null" 1 "Pressed" ;
VAL_ 827 LghtAmbIntns_D2_Sns 0 "Low" 1 "Medium" 2 "High" 3 "Faulty" ;
VAL_ 827 LghtAmbIntns_D_Sns 0 "Null" 1 "Low" 2 "High" 3 "Faulty" ;
VAL_ 827 SteClmnSwtchTlt_D_Stat 0 "Null" 1 "Up" 2 "Down" 3 "Unused" ;
VAL_ 827 SteClmnSwtchTel_D_Stat 0 "Null" 1 "Forward" 2 "Rearward" 3 "Unused" ;
VAL_ 828 SpotLghtRight_D_Stat 0 "Off" 1 "On" ;
VAL_ 828 SpotLghtLeft_D_Stat 0 "Off" 1 "On" ;
VAL_ 828 RearPassWindowPos 0 "Undefined" 1 "Fully_Closed" 2 "BetFully_10PercentOpen" 3 "Bet10Percent_60Percent" 4 "Bet60Percent_FullyOpen" 5 "Fully_Open" 6 "Unused1" 7 "Unused2" ;
VAL_ 828 PassWindowPosition 0 "Undefined" 1 "Fully_Closed" 2 "BetFully_10PercentOpen" 3 "Bet10Percent_60Percent" 4 "Bet60Percent_FullyOpen" 5 "Fully_Open" 6 "Unused1" 7 "Unused2" ;
VAL_ 828 DrvSpotLight_B_Rq 0 "No" 1 "Yes" ;
VAL_ 831 RearPassWindowLockCmd 0 "Disable" 1 "Enable" ;
VAL_ 831 DriverWindowPosition 0 "Undefined" 1 "Fully_Closed" 2 "BetFully_10PercentOpen" 3 "Bet10Percent_60Percent" 4 "Bet60Percent_FullyOpen" 5 "Fully_Open" 6 "Unused1" 7 "Unused2" ;
VAL_ 831 DipMirrorPosPassenger 0 "Off" 1 "Dipped" ;
VAL_ 831 ActiveStoragePassenger 0 "Off" 1 "StoreDipMemoryButton1" 2 "StoreDipMemoryButton2" 3 "StoreDipMemoryButton3" 4 "StoreDipMemoryButton4" 5 "Unused1" 6 "Unused2" 7 "Unused3" ;
VAL_ 831 MirrorTelescopic_D_Rq 0 "Null" 1 "Extend" 2 "Retract" 3 "NotUsed" ;
VAL_ 831 PassWindowCmd 0 "Idle" 1 "Manual_Up" 2 "Auto_Up" 3 "Manual_Down" 4 "Audo_Down" 5 "NotDefined" 6 "Unused1" 7 "Unused2" ;
VAL_ 831 PassMirrorCmd 0 "Idle" 1 "Up" 2 "Down" 3 "Left" 4 "Right" 5 "Fold" 6 "Unfold" 7 "Unused" ;
VAL_ 831 WndwChildLckPw_B_Stat 0 "Unlock" 1 "Lock" ;
VAL_ 831 RearPassWindowCmd 0 "Idle" 1 "Manual_Up" 2 "Auto_Up" 3 "Manual_Down" 4 "Audo_Down" 5 "NotDefined" 6 "Unused1" 7 "Unused2" ;
VAL_ 831 RearDriverWindowPos 0 "Undefined" 1 "Fully_Closed" 2 "BetFully_10PercentOpen" 3 "Bet10Percent_60Percent" 4 "Bet60Percent_FullyOpen" 5 "Fully_Open" 6 "Unused1" 7 "Unused2" ;
VAL_ 836 EngClnt_Te_ActlFoh 255 "Fault" ;
VAL_ 836 HvacPrecondBlwr_D_Rq 0 "Off" 1 "Speed1" 2 "Speed2" 3 "Speed3" 4 "Speed4" 5 "Speed5" 6 "Speed6" 7 "Speed7" 8 "Auto" 9 "Last_User_Setting" 10 "NotUsed1" 11 "NotUsed2" 12 "NotUsed3" 13 "NotUsed4" 14 "NotUsed5" 15 "NotUsed6" ;
VAL_ 836 HvacPrecondMode_D_Rq 0 "Off" 1 "MAX_AC" 2 "Panel" 3 "Panel_Floor" 4 "Floor" 5 "Windshield_Floor" 6 "Windshield" 7 "Windshield_Panel" 8 "Windshield_Panel_Floor" 9 "Max_Defrost" 10 "Auto" 11 "Last_User_Settings" 12 "Low_Blower_Auto" 13 "NotUsed2" 14 "NotUsed3" 15 "NotUsed4" ;
VAL_ 836 FohEnbl_B_RqDrv 0 "Off" 1 "On" ;
VAL_ 836 Foh_D_Stat 0 "Off" 1 "Prestart" 2 "Starting" 3 "Running" 4 "Stopping" 5 "Unused1" 6 "Unused2" 7 "Unused3" ;
VAL_ 836 FohFalt_D_Stat 0 "No_Disable" 1 "AmbientTemp_OutofRange" 2 "CoolantTemp_OutofRange" 3 "Impact_Event" 4 "Voltage_limitation" 5 "Internal_Fault" 6 "External_Fault" 7 "Fuel_Level_OutofRange" 8 "TimeDelayAvoidExcessCycl" 9 "AuxElectricCoolantPumpInop" 10 "Lifecycle_ModeNotSet" 11 "FuelTypeDoesNotMatchFOH" 12 "NotUsed1" 13 "NotUsed2" 14 "NotUsed3" 15 "NotUsed4" ;
VAL_ 836 FohRqRun_B_Rq 0 "DoesNotSubmitRequest_toRun" 1 "SubmitRequest_toRun" ;
VAL_ 837 AirSusp_D_Stat 0 "Null" 1 "Off" 2 "On" 3 "NotUsed" ;
VAL_ 837 AirSuspMsgTxt_D_Rq 0 "NoMessage" 1 "Override" 2 "Faulty" 3 "NotUsed" ;
VAL_ 837 CcdMsgTxt_D_RqDsply 0 "No_Mode_Selected" 1 "Comfort" 2 "Normal" 3 "Sport" 4 "Faulty" 5 "CCD_Service_Required" 6 "CCD_Temporarily_Off" 7 "Mode_Change_Unavailable" 8 "StationaryMode" 9 "Unused2" 10 "Unused3" 11 "Unused4" 12 "Unused5" 13 "Unused6" 14 "Unused7" 15 "Unused8" ;
VAL_ 837 AdptDrvMdeChassis_D_Rq 0 "AdaptiveNotActive" 1 "Chassis2Comfort" 2 "Chassis2Normal" 3 "Chassis2Sport" 4 "NotUsed1" 5 "NotUsed2" 6 "NotUsed3" 7 "Faulty" ;
VAL_ 837 VdmSustnActv_B_Rq 0 "Inactive" 1 "Active" ;
VAL_ 837 SuspDrvMde_D_Stat 0 "Normal" 1 "Sport" 2 "Snow_Wet" 3 "Track" 4 "Drag" 5 "NotUsed1" 6 "NotUsed2" 7 "Faulty" ;
VAL_ 837 AirSprngRateFl_D_Rq 0 "Soft" 1 "Medium" 2 "Firm" 3 "NoRequest" ;
VAL_ 837 SuspVLim_B_Rq 0 "False" 1 "True" ;
VAL_ 837 SelDrvMdeSusp_D_Stat 0 "NotAvailable" 1 "Available" 2 "TemporarilyNotAvailable" 3 "Faulty" ;
VAL_ 837 AdptDrvMdePt_D_Rq 0 "AdaptiveNotActive" 1 "Powertrain2Comfort" 2 "Powertrain2Normal" 3 "Powertrain2Sport" 4 "NotUsed1" 5 "NotUsed2" 6 "NotUsed3" 7 "Faulty" ;
VAL_ 837 Ccd_B_Falt 0 "No" 1 "Yes" ;
VAL_ 837 SuspType_B_Stat 0 "NonMagnetic" 1 "Magnetic" ;
VAL_ 837 AirSprngRateRr_D_Rq 0 "Soft" 1 "Medium" 2 "Firm" 3 "NoRequest" ;
VAL_ 837 AirSprngRateRl_D_Rq 0 "Soft" 1 "Medium" 2 "Firm" 3 "NoRequest" ;
VAL_ 837 AirSprngRateFr_D_Rq 0 "Soft" 1 "Medium" 2 "Firm" 3 "NoRequest" ;
VAL_ 837 VehCurb_M_Actl 1022 "NoDataExists" 1023 "Faulty" ;
VAL_ 837 VehGvwr_M_Actl 1022 "NoDataExists" 1023 "Faulty" ;
VAL_ 838 FohT2Enable_B_Rq 0 "Disable" 1 "Enable" ;
VAL_ 838 FohT1Enable_B_Rq 0 "Disable" 1 "Enable" ;
VAL_ 838 FohTAllEnable_B_Rq 0 "Disable" 1 "Enable" 2 "NotUsed" 3 "Unknown" ;
VAL_ 838 FohStop_B_Rq 0 "Disable" 1 "Enable" 2 "NotUsed" 3 "Unknown" ;
VAL_ 838 FohStrtDay_T_Rq 0 "NotUsed" 1 "Monday" 2 "Tuesday" 3 "Wednesday" 4 "Thursday" 5 "Friday" 6 "Saturday" 7 "Sunday" ;
VAL_ 838 FohStrtEnable_B_Rq 0 "Disable" 1 "Enable" ;
VAL_ 838 FohContOn_B_Rq 0 "Disable" 1 "Enable" 2 "NotUsed" 3 "Unknown" ;
VAL_ 839 FohT1Enable_B_Stat 0 "Disable" 1 "Enable" ;
VAL_ 839 FohStrtEnable_B_Stat 0 "Disable" 1 "Enable" ;
VAL_ 839 FohMsgTxt_D_Rq 0 "NoMessage" 1 "LowFuel" 2 "AmbientTemperatureTooHigh" 3 "Exceed7DaysFromLastEngRun" 4 "BatteryNotFullyCharged" ;
VAL_ 839 FohT1Friday_T_Stat 0 "Disable" 1 "Enable" ;
VAL_ 839 FohKeyOff_B_Rq 0 "Disable" 1 "Enable" ;
VAL_ 839 FohEnbl_B_Rq 0 "Disable" 1 "Enable" ;
VAL_ 839 FohStrtDay_T_Stat 0 "NotUsed" 1 "Monday" 2 "Tuesday" 3 "Wednesday" 4 "Thursday" 5 "Friday" 6 "Saturday" 7 "Sunday" ;
VAL_ 839 FohTAllEnable_B_Stat 0 "Disable" 1 "Enable" 2 "NotUsed" 3 "Unknown" ;
VAL_ 839 FohT1Sunday_T_Stat 0 "Disable" 1 "Enable" ;
VAL_ 839 FohT1Saturday_T_Stat 0 "Disable" 1 "Enable" ;
VAL_ 839 FohT1Monday_T_Stat 0 "Disable" 1 "Enable" ;
VAL_ 839 FohContOn_B_Stat 0 "Disable" 1 "Enable" 2 "NotUsed" 3 "Unknown" ;
VAL_ 839 FohT1Wednesday_T_Stat 0 "Disable" 1 "Enable" ;
VAL_ 839 FohT1Tuesday_T_Stat 0 "Disable" 1 "Enable" ;
VAL_ 839 FohT1Thursday_T_Stat 0 "Disable" 1 "Enable" ;
VAL_ 839 FohStop_B_Stat 0 "Disable" 1 "Enable" 2 "NotUsed" 3 "Unknown" ;
VAL_ 839 FohT2Wednesday_T_Stat 0 "Disable" 1 "Enable" ;
VAL_ 839 FohT2Tuesday_T_Stat 0 "Disable" 1 "Enable" ;
VAL_ 839 FohT2Thursday_T_Stat 0 "Disable" 1 "Enable" ;
VAL_ 839 FohT2Sunday_T_Stat 0 "Disable" 1 "Enable" ;
VAL_ 839 FohT2Saturday_T_Stat 0 "Disable" 1 "Enable" ;
VAL_ 839 FohT2Monday_T_Stat 0 "Disable" 1 "Enable" ;
VAL_ 839 FohT2Friday_T_Stat 0 "Disable" 1 "Enable" ;
VAL_ 839 FohT2Enable_B_Stat 0 "Disable" 1 "Enable" ;
VAL_ 840 FohT2Friday_T_Rq 0 "Disable" 1 "Enable" ;
VAL_ 840 FohT1Wednesday_T_Rq 0 "Disable" 1 "Enable" ;
VAL_ 840 FohT1Tuesday_T_Rq 0 "Disable" 1 "Enable" ;
VAL_ 840 FohT1Thursday_T_Rq 0 "Disable" 1 "Enable" ;
VAL_ 840 FohT1Sunday_T_Rq 0 "Disable" 1 "Enable" ;
VAL_ 840 FohT1Saturday_T_Rq 0 "Disable" 1 "Enable" ;
VAL_ 840 FohT1Monday_T_Rq 0 "Disable" 1 "Enable" ;
VAL_ 840 FohT1Friday_T_Rq 0 "Disable" 1 "Enable" ;
VAL_ 840 FohAddHeater_D_Rq 0 "NoModeSelected" 1 "Off" 2 "On" 3 "NotUsed" ;
VAL_ 840 FohT2Wednesday_T_Rq 0 "Disable" 1 "Enable" ;
VAL_ 840 FohT2Tuesday_T_Rq 0 "Disable" 1 "Enable" ;
VAL_ 840 FohT2Thursday_T_Rq 0 "Disable" 1 "Enable" ;
VAL_ 840 FohT2Sunday_T_Rq 0 "Disable" 1 "Enable" ;
VAL_ 840 FohT2Saturday_T_Rq 0 "Disable" 1 "Enable" ;
VAL_ 840 FohT2Monday_T_Rq 0 "Disable" 1 "Enable" ;
VAL_ 841 FohAddHeater_D_Stat 0 "NoModeSelected" 1 "Off" 2 "On" 3 "NotUsed" ;
VAL_ 842 SeatBlLoDrv_Pc_Actl 127 "Null" ;
VAL_ 842 SeatBlUpDrv_Pc_Actl 127 "Null" ;
VAL_ 843 SeatBlLoPsgr_Pc_Actl 127 "Null" ;
VAL_ 843 SeatBlUpPsgr_Pc_Actl 127 "Null" ;
VAL_ 843 SeatSrvcPsngr_D_Arb 0 "Null" 1 "Local" 2 "Soa" 3 "NotUsed_1" ;
VAL_ 843 StmsPtrnPsngr_D_Stat 0 "Null" 1 "Lower_Rolling" 2 "Upper_Rolling" 3 "Circular_Cushion" 4 "Full_Recovery" 5 "Relaxed_Recovery" 6 "Circular_Combo" 7 "Zig_Zag_Combo" 8 "Sweep_Wave" 9 "Up_Wave" 10 "Pulse" 11 "NotUsed_1" 12 "NotUsed_2" 13 "NotUsed_3" 14 "NotUsed_4" 15 "NotUsed_5" ;
VAL_ 843 SeatSrvcPsngr_D_Res 0 "Null" 1 "Success" 2 "Pending" 3 "Rejected" 4 "Interrupted" 5 "Failed" 6 "In_Prog" 7 "Invalid" 8 "NotUsed_1" 9 "NotUsed_2" 10 "NotUsed_3" 11 "NotUsed_4" 12 "NotUsed_5" 13 "NotUsed_6" 14 "NotUsed_7" 15 "Faulty" ;
VAL_ 843 StmsSrvcPsngr_D_Res 0 "Null" 1 "Success" 2 "Pending" 3 "Rejected" 4 "Interrupted" 5 "Failed" 6 "In_Prog" 7 "Invalid" 8 "NotUsed_1" 9 "NotUsed_2" 10 "NotUsed_3" 11 "NotUsed_4" 12 "NotUsed_5" 13 "NotUsed_6" 14 "NotUsed_7" 15 "Faulty" ;
VAL_ 843 StmsSrvcPsngr_D_Arb 0 "Null" 1 "Local" 2 "Soa" 3 "NotUsed_1" ;
VAL_ 843 StmsIntnsPsngr_D_Stat 0 "Null" 1 "Low" 2 "Medium" 3 "High" ;
VAL_ 844 StmsLmbrDrv_D_Stat 0 "Null" 1 "Off" 2 "Low" 3 "High" ;
VAL_ 844 StmsCshnDrv_D_Stat 0 "Null" 1 "Off" 2 "Low" 3 "High" ;
VAL_ 844 SeatPDrv_B_Stat 0 "NotUpdating" 1 "Updating" ;
VAL_ 844 SeatFnDrv_D_Stat 0 "Null" 1 "LowerLumbar" 2 "MiddleLumbar" 3 "UpperLumbar" 4 "LowerBolster" 5 "UpperBolster" 6 "LumbarMassage" 7 "CushionMassage" ;
VAL_ 844 SeatMasgDrv_D_Stat 0 "Null" 1 "Pattern1" 2 "Pattern2" 3 "Pattern3" 4 "Pattern4" 5 "Pattern5" 6 "Pattern6" 7 "Pattern7" 8 "Pattern8" 9 "Pattern9" 10 "Pattern10" 11 "NotUsed_6" 12 "NotUsed_7" 13 "NotUsed_8" 14 "NotUsed_9" 15 "NotUsed_10" ;
VAL_ 844 SeatIntnsDrv_D_Stat 0 "Null" 1 "Off" 2 "Low" 3 "Medium" 4 "High" 5 "NotUsed_1" 6 "NotUsed_2" 7 "NotUsed_3" ;
VAL_ 844 SeatSwtchDrv_B_Stat 0 "Off" 1 "On" ;
VAL_ 844 StmsMduleDrv_D_Stat 0 "Null" 1 "Off" 2 "Partial_Active" 3 "Fully_Active" ;
VAL_ 845 PsgrMemFeedback_Rsp 0 "Inactive" 1 "Store_1" 2 "Store_2" 3 "Store_3" 4 "Store_4" 5 "Recall_1" 6 "Recall_2" 7 "Recall_3" 8 "Recall_4" ;
VAL_ 845 SeatFnPsgr_D_Stat 0 "Null" 1 "LowerLumbar" 2 "MiddleLumbar" 3 "UpperLumbar" 4 "LowerBolster" 5 "UpperBolster" 6 "LumbarMassage" 7 "CushionMassage" ;
VAL_ 845 SeatPPsgr_B_Stat 0 "NotUpdating" 1 "Updating" ;
VAL_ 845 SeatIntnsPsngr_D_Stat 0 "Null" 1 "Off" 2 "Low" 3 "Medium" 4 "High" 5 "NotUsed_1" 6 "NotUsed_2" 7 "NotUsed_3" ;
VAL_ 845 SeatSwtchPsgr_B_Stat 0 "Off" 1 "On" ;
VAL_ 845 StmsCshnPsgr_D_Stat 0 "Null" 1 "Off" 2 "Low" 3 "High" ;
VAL_ 845 StmsLmbrPsgr_D_Stat 0 "Null" 1 "Off" 2 "Low" 3 "High" ;
VAL_ 845 StmsMdulePsngr_D_Stat 0 "Null" 1 "Off" 2 "Partial_Active" 3 "Fully_Active" ;
VAL_ 845 StmsAutoSavPsngr_D_St 0 "None" 1 "InProgress" 2 "Major" 3 "Minor" ;
VAL_ 845 SeatMasgPsngr_D_Stat 0 "Null" 1 "Pattern1" 2 "Pattern2" 3 "Pattern3" 4 "Pattern4" 5 "Pattern5" 6 "Pattern6" 7 "Pattern7" 8 "Pattern8" 9 "Pattern9" 10 "Pattern10" 11 "NotUsed_6" 12 "NotUsed_7" 13 "NotUsed_8" 14 "NotUsed_9" 15 "NotUsed_10" ;
VAL_ 846 PsgrMemory_Rq 0 "Inactive" 1 "Store_1" 2 "Store_2" 3 "Store_3" 4 "Store_4" 5 "Recall_1" 6 "Recall_2" 7 "Recall_3" 8 "Recall_4" ;
VAL_ 846 SeatFnChngDrv_D_Rq 0 "Inactive" 1 "Increase" 2 "Decrease" ;
VAL_ 846 SeatFnChngPsgr_D_Rq 0 "Inactive" 1 "Increase" 2 "Decrease" ;
VAL_ 846 SeatFnDfaltDrv_B_Rq 0 "Inactive" 1 "Active" ;
VAL_ 846 SeatFnDfaltPsgr_B_Rq 0 "Inactive" 1 "Active" ;
VAL_ 846 SeatFnDrv_D_Rq 0 "Inactive" 1 "LowerLumbar" 2 "MiddleLumbar" 3 "UpperLumbar" 4 "LowerBolster" 5 "UpperBolster" 6 "LumbarMassage" 7 "CushionMassage" ;
VAL_ 846 SeatFnPsgr_D_Rq 0 "Inactive" 1 "LowerLumbar" 2 "MiddleLumbar" 3 "UpperLumbar" 4 "LowerBolster" 5 "UpperBolster" 6 "LumbarMassage" 7 "CushionMassage" ;
VAL_ 846 SeatFnChngDrv2_D_Rq 0 "Inactive" 1 "NotUsed1" 2 "Increase" 3 "Decrease" 4 "Off" 5 "Low" 6 "High" 7 "Off_2" 8 "Low_2" 9 "Med_2" 10 "High_2" 11 "NotUsed6" 12 "NotUsed7" 13 "NotUsed8" 14 "NotUsed9" 15 "Faulty" ;
VAL_ 846 SeatFnChngPsgr2_D_Rq 0 "Inactive" 1 "NotUsed1" 2 "Increase" 3 "Decrease" 4 "Off" 5 "Low" 6 "High" 7 "Off_2" 8 "Low_2" 9 "Med_2" 10 "High_2" 11 "NotUsed6" 12 "NotUsed7" 13 "NotUsed8" 14 "NotUsed9" 15 "Faulty" ;
VAL_ 846 SeatMasgDrv_D_Rq 0 "Null" 1 "Pattern1" 2 "Pattern2" 3 "Pattern3" 4 "Pattern4" 5 "Pattern5" 6 "Pattern6" 7 "Pattern7" 8 "Pattern8" 9 "Pattern9" 10 "Pattern10" 11 "NotUsed_6" 12 "NotUsed_7" 13 "NotUsed_8" 14 "NotUsed_9" 15 "NotUsed_10" ;
VAL_ 846 SeatLmbr_D_Rq 0 "Null" 1 "DriverFore" 2 "DriverAft" 3 "DriverUp" 4 "DriverDown" 5 "PassengerFore" 6 "PassengerAft" 7 "PassengerUp" 8 "PassengerDown" 9 "NotUsed_1" 10 "NotUsed_2" 11 "NotUsed_3" 12 "NotUsed_4" 13 "NotUsed_5" 14 "NotUsed_6" 15 "NotUsed_7" ;
VAL_ 846 SeatRelxPosDactv_B_Rq 0 "False" 1 "True" ;
VAL_ 846 SeatRelxPosActv_B_Rq 0 "False" 1 "True" ;
VAL_ 846 SeatRelxPosSet_D_Rq 0 "Inactive" 1 "Store" 2 "Active" 3 "NotUsed" ;
VAL_ 846 SeatMasgPsngr_D_Rq 0 "Null" 1 "Pattern1" 2 "Pattern2" 3 "Pattern3" 4 "Pattern4" 5 "Pattern5" 6 "Pattern6" 7 "Pattern7" 8 "Pattern8" 9 "Pattern9" 10 "Pattern10" 11 "NotUsed_6" 12 "NotUsed_7" 13 "NotUsed_8" 14 "NotUsed_9" 15 "NotUsed_10" ;
VAL_ 846 SeatPosHomeRear_D_Rq 0 "NoRequest" 1 "LeftSecondRowSeatReturn" 2 "RightSecondRowSeatReturn" 3 "BothSecondRowSeatReturn" 4 "LeftThirdRowSeatReturn" 5 "RightThirdRowSeatReturn" 6 "BothThirdRowSeatReturn" 7 "NotUsed_1" 8 "NotUsed_2" 9 "NotUsed_3" 10 "NotUsed_4" 11 "NotUsed_5" 12 "NotUsed_6" 13 "NotUsed_7" 14 "NotUsed_8" 15 "NotUsed_9" ;
VAL_ 848 RILStat 0 "Off" 1 "On" 2 "Plant_Mode" 3 "Fault" ;
VAL_ 851 ConsAvgTrip_No_Dsply 4094 "No_Data_Exists" 4095 "Faulty" ;
VAL_ 851 ConsLongTerm_No_Dsply 4094 "No_Data_Exists" 4095 "Faulty" ;
VAL_ 851 ConsUnitIPC_D_Dsply 0 "Invalid" 1 "Miles_Gallon_US_" 2 "Liters_100_km" 3 "km_L" 4 "miles_gallon_UK_" 5 "Whr_mi_" 6 "Whr_km_" 7 "Miles_Gallon" 8 "Liters_100_km" 9 "km_L_" 10 "miles_gallon_UK_" 11 "MPG_Hi_Res" 12 "Reserved_12" 13 "Reserved_13" 14 "Reserved_14" 15 "Reserved_15" ;
VAL_ 861 Rr_AUTO_Btn_Stt 0 "Enabled_Inactive" 1 "Active" 2 "Disabled" 3 "Unused" ;
VAL_ 861 Rr_On_Indicator 0 "Off" 1 "On" ;
VAL_ 861 CC_Rr_Stat_User_Adj 0 "None" 1 "RLHS_SetPt_Selection" 2 "RRHS_SetPt_Selection" 3 "Rr_Blwr_Spd_Selection" 4 "Rr_Power_Selection" 5 "Rr_Control_Selection" 6 "Rr_Auto_Selection" 7 "Unused1" 8 "Unused2" 9 "Unused3" 10 "Unused4" 11 "Unused5" 12 "Unused6" 13 "Unused7" 14 "Unused8" 15 "Unused9" ;
VAL_ 861 Rr_Floor_Btn_Stt 0 "Enabled_Inactive" 1 "Active" 2 "Disabled" 3 "Unused" ;
VAL_ 861 Rr_Control_Btn_Stt 0 "Enabled_Inactive" 1 "Active" 2 "Disabled" 3 "Unused" ;
VAL_ 861 Rr_Blower_Indicate 0 "Indicators_Off" 1 "1_Indicator_On" 2 "2_Indicators_On" 3 "3_Indicators_On" 4 "4_Indicators_On" 5 "5_Indicators_On" 6 "6_Indicators_On" 7 "7_Indicators_On" 8 "8_Indicators_On" 9 "9_Indicators_On" 10 "10_Indicators_On" 11 "11_Indicators_On" 12 "12_Indicators_On" 13 "13_Indicators_On" 14 "14_Indicators_On" 15 "Display_Blank" ;
VAL_ 861 Rr_RH_Cond_Seat_Stat 0 "Off" 1 "Level_1_Cooling" 2 "Level_2_Cooling" 3 "Level_3_Cooling" 4 "Level_1_Heating" 5 "Level_2_Heating" 6 "Level_3_Heating" 7 "Unused" ;
VAL_ 861 Rr_LH_Cond_Seat_Stat 0 "Off" 1 "Level_1_Cooling" 2 "Level_2_Cooling" 3 "Level_3_Cooling" 4 "Level_1_Heating" 5 "Level_2_Heating" 6 "Level_3_Heating" 7 "Unused" ;
VAL_ 861 Rr_LH_Cld_Seat_Btn_Stt 0 "Enabled_Inactive" 1 "Active" 2 "Disabled" 3 "Unused" ;
VAL_ 861 Rr_LHS_Set_Temp_Dig2 0 "0" 1 "1" 2 "2" 3 "3" 4 "4" 5 "5" 6 "6" 7 "7" 8 "8" 9 "9" 10 "L" 11 "O" 12 "H" 13 "I" 14 "Blank1" 15 "Blank2" ;
VAL_ 861 Rr_LHS_Set_Temp_Dig1 0 "0" 1 "1" 2 "2" 3 "3" 4 "4" 5 "5" 6 "6" 7 "7" 8 "8" 9 "9" 10 "L" 11 "O" 12 "H" 13 "I" 14 "Blank1" 15 "Blank2" ;
VAL_ 861 Rr_LH_Htd_Seat_Btn_Stt 0 "Enabled_Inactive" 1 "Active" 2 "Disabled" 3 "Unused" ;
VAL_ 861 Rr_Pnl_Flr_Btn_Stt 0 "Enabled_Inactive" 1 "Active" 2 "Disabled" 3 "Unused" ;
VAL_ 861 Rr_Panel_Btn_Stt 0 "Enabled_Inactive" 1 "Active" 2 "Disabled" 3 "Unused" ;
VAL_ 861 Rr_LHS_Set_Temp_Dig3 0 "Off" 1 "0" 2 "5" ;
VAL_ 861 Rr_Set_Temp_Units 0 "Off" 1 "Celsius" 2 "Fahrenheit" ;
VAL_ 861 Rr_RHS_Set_Temp_Dig3 0 "Off" 1 "0" 2 "5" ;
VAL_ 861 Rr_RH_Htd_Seat_Btn_Stt 0 "Enabled_Inactive" 1 "Active" 2 "Disabled" 3 "Unused" ;
VAL_ 861 Rr_RH_Cld_Seat_Btn_Stt 0 "Enabled_Inactive" 1 "Active" 2 "Disabled" 3 "Unused" ;
VAL_ 861 Rr_RHS_Set_Temp_Dig2 0 "0" 1 "1" 2 "2" 3 "3" 4 "4" 5 "5" 6 "6" 7 "7" 8 "8" 9 "9" 10 "L" 11 "O" 12 "H" 13 "I" 14 "Blank1" 15 "Blank2" ;
VAL_ 861 Rr_RHS_Set_Temp_Dig1 0 "0" 1 "1" 2 "2" 3 "3" 4 "4" 5 "5" 6 "6" 7 "7" 8 "8" 9 "9" 10 "L" 11 "O" 12 "H" 13 "I" 14 "Blank1" 15 "Blank2" ;
VAL_ 861 Rr_Power_Btn_Stt 0 "Enabled_Inactive" 1 "Active" 2 "Disabled" 3 "Unused" ;
VAL_ 861 Rr_Temp_Detents 0 "No_Bars" 1 "4_Cool_Bars" 2 "3_Cool_Bars" 3 "2_Cool_Bars" 4 "1_Cool_Bar" 5 "Neutral_Bar_Only" 6 "1_Heat_Bar" 7 "2_Heat_Bars" 8 "3_Heat_Bars" 9 "4_Heat_Bars" 10 "Display_Blank" 11 "Unused1" 12 "Unused2" 13 "Unused3" 14 "Unused4" 15 "Unused5" ;
VAL_ 862 AutoStpHvacDelta_I_Est 255 "Fault" ;
VAL_ 862 CabnAmb_Te_Actl 255 "Fault" ;
VAL_ 862 ClimtThrmlLoad_No_Actl 255 "Fault" ;
VAL_ 862 ApaSwtch_D_RqDrv 0 "Not_Pressed" 1 "Pressed" 2 "NotUsed1" 3 "NotUsed2" ;
VAL_ 862 CamraDefog_B_Actl 0 "Off" 1 "On" ;
VAL_ 862 HvacBlwrFront_D_Stat 0 "Off" 1 "5_Percent" 2 "10_Percent" 3 "15_Percent" 4 "20_Percent" 5 "25_Percent" 6 "30_Percent" 7 "35_Percent" 8 "40_Percent" 9 "45_Percent" 10 "50_Percent" 11 "55_Percent" 12 "60_Percent" 13 "65_Percent" 14 "70_Percent" 15 "75_Percent" 16 "80_Percent" 17 "85_Percent" 18 "90_Percent" 19 "95_Percent" 20 "Full_On" 31 "Not_Used" ;
VAL_ 862 EcoMde_D_RqDrv 0 "Null" 1 "Off" 2 "On" 3 "Faulty" ;
VAL_ 862 TwHlGrdAsst_B_RqTrn 0 "Off" 1 "On" ;
VAL_ 862 HvacBlwrRear_D_Stat 0 "Off" 1 "5_Percent" 2 "10_Percent" 3 "15_Percent" 4 "20_Percent" 5 "25_Percent" 6 "30_Percent" 7 "35_Percent" 8 "40_Percent" 9 "45_Percent" 10 "50_Percent" 11 "55_Percent" 12 "60_Percent" 13 "65_Percent" 14 "70_Percent" 15 "75_Percent" 16 "80_Percent" 17 "85_Percent" 18 "90_Percent" 19 "95_Percent" 20 "Full_On" 31 "Not_Used" ;
VAL_ 863 StewSwtchPrim_D_Stat2 0 "NotPressed" 1 "Pressed" ;
VAL_ 863 StewSwtchScnd_D_Stat2 0 "NotPressed" 1 "Pressed" ;
VAL_ 863 SteWhlHeat_D_Stat 0 "Off" 1 "Level_1_Heating_LS" 2 "Level_1_Heating" 3 "Level_2_Heating_LS" 4 "Level_2_Heating" 5 "Level_3_Heating_LS" 6 "Level_3_Heating" 7 "Reserved_1" 8 "Reserved_2" 9 "Reserved_3" 10 "NotUsed1" 11 "NotUsed2" 12 "NotUsed3" 13 "NotUsed4" 14 "NotUsed5" 15 "NotUsed6" ;
VAL_ 863 StewSwtchPrimPosX_D_St 0 "NoTouch" 1 "Loc_1" 2 "Loc_2" 3 "Loc_3" 4 "Loc_4" 5 "Loc_5" 6 "Loc_6" 7 "Loc_7" 8 "Loc_8" 9 "Loc_9" 10 "Loc_10" 11 "Loc_11" 12 "Loc_12" 13 "Loc_13" 14 "Loc_14" 15 "Loc_15" 16 "Loc_16" 17 "Loc_17" 18 "Loc_18" 19 "Loc_19" 20 "Loc_20" 21 "Loc_21" 22 "Loc_22" 23 "Loc_23" 24 "Loc_24" 25 "Loc_25" 26 "Loc_26" 27 "Loc_27" 28 "Loc_28" 29 "Loc_29" 30 "Loc_30" 31 "Loc_31" 32 "Loc_32" 33 "Loc_33" 34 "Loc_34" 35 "Loc_35" 36 "Loc_36" 37 "Loc_37" 38 "Loc_38" 39 "Loc_39" 40 "Loc_40" 41 "Loc_41" 42 "Loc_42" 43 "Loc_43" 44 "Loc_44" 45 "Loc_45" 46 "Loc_46" 47 "Loc_47" 48 "Loc_48" 49 "Loc_49" 50 "Loc_50" 51 "Loc_51" 52 "Loc_52" 53 "Loc_53" 54 "Loc_54" 55 "Loc_55" 56 "Loc_56" 57 "Loc_57" 58 "Loc_58" 59 "Loc_59" 60 "Loc_60" 61 "Loc_61" 62 "Loc_62" 63 "Loc_63" 64 "Loc_64" 65 "Loc_65" 66 "Loc_66" 67 "Loc_67" 68 "Loc_68" 69 "Loc_69" 70 "Loc_70" 71 "Loc_71" 72 "Loc_72" 73 "Loc_73" 74 "Loc_74" 75 "Loc_75" 76 "Loc_76" 77 "Loc_77" 78 "Loc_78" 79 "Loc_79" 80 "Loc_80" 81 "Loc_81" 82 "Loc_82" 83 "Loc_83" 84 "Loc_84" 85 "Loc_85" 86 "Loc_86" 87 "Loc_87" 88 "Loc_88" 89 "Loc_89" 90 "Loc_90" 91 "Loc_91" 92 "Loc_92" 93 "Loc_93" 94 "Loc_94" 95 "Loc_95" 96 "Loc_96" 97 "Loc_97" 98 "Loc_98" 99 "Loc_99" 100 "Loc_100" 101 "Loc_101" 102 "Loc_102" 103 "Loc_103" 104 "Loc_104" 105 "Loc_105" 106 "Loc_106" 107 "Loc_107" 108 "Loc_108" 109 "Loc_109" 110 "Loc_110" 111 "Loc_111" 112 "Loc_112" 113 "Loc_113" 114 "Loc_114" 115 "Loc_115" 116 "Loc_116" 117 "Loc_117" 118 "Loc_118" 119 "Loc_119" 120 "Loc_120" 121 "Loc_121" 122 "Loc_122" 123 "Loc_123" 124 "Loc_124" 125 "Loc_125" 126 "Loc_126" 127 "Loc_127" 128 "Loc_128" 129 "Loc_129" 130 "Loc_130" 131 "Loc_131" 132 "Loc_132" 133 "Loc_133" 134 "Loc_134" 135 "Loc_135" 136 "Loc_136" 137 "Loc_137" 138 "Loc_138" 139 "Loc_139" 140 "Loc_140" 141 "Loc_141" 142 "Loc_142" 143 "Loc_143" 144 "Loc_144" 145 "Loc_145" 146 "Loc_146" 147 "Loc_147" 148 "Loc_148" 149 "Loc_149" 150 "Loc_150" 151 "Loc_151" 152 "Loc_152" 153 "Loc_153" 154 "Loc_154" 155 "Loc_155" 156 "Loc_156" 157 "Loc_157" 158 "Loc_158" 159 "Loc_159" 160 "Loc_160" 161 "Loc_161" 162 "Loc_162" 163 "Loc_163" 164 "Loc_164" 165 "Loc_165" 166 "Loc_166" 167 "Loc_167" 168 "Loc_168" 169 "Loc_169" 170 "Loc_170" 171 "Loc_171" 172 "Loc_172" 173 "Loc_173" 174 "Loc_174" 175 "Loc_175" 176 "Loc_176" 177 "Loc_177" 178 "Loc_178" 179 "Loc_179" 180 "Loc_180" 181 "Loc_181" 182 "Loc_182" 183 "Loc_183" 184 "Loc_184" 185 "Loc_185" 186 "Loc_186" 187 "Loc_187" 188 "Loc_188" 189 "Loc_189" 190 "Loc_190" 191 "Loc_191" 192 "Loc_192" 193 "Loc_193" 194 "Loc_194" 195 "Loc_195" 196 "Loc_196" 197 "Loc_197" 198 "Loc_198" 199 "Loc_199" 200 "Loc_200" 201 "Loc_201" 202 "Loc_202" 203 "Loc_203" 204 "Loc_204" 205 "Loc_205" 206 "Loc_206" 207 "Loc_207" 208 "Loc_208" 209 "Loc_209" 210 "Loc_210" 211 "Loc_211" 212 "Loc_212" 213 "Loc_213" 214 "Loc_214" 215 "Loc_215" 216 "Loc_216" 217 "Loc_217" 218 "Loc_218" 219 "Loc_219" 220 "Loc_220" 221 "Loc_221" 222 "Loc_222" 223 "Loc_223" 224 "Loc_224" 225 "Loc_225" 226 "Loc_226" 227 "Loc_227" 228 "Loc_228" 229 "Loc_229" 230 "Loc_230" 231 "Loc_231" 232 "Loc_232" 233 "Loc_233" 234 "Loc_234" 235 "Loc_235" 236 "Loc_236" 237 "Loc_237" 238 "Loc_238" 239 "Loc_239" 240 "Loc_240" 241 "Loc_241" 242 "Loc_242" 243 "Loc_243" 244 "Loc_244" 245 "Loc_245" 246 "Loc_246" 247 "Loc_247" 248 "Loc_248" 249 "Loc_249" 250 "Loc_250" 251 "Loc_251" 252 "Loc_252" 253 "NotUsed_1" 254 "NotUsed_2" 255 "Faulty" ;
VAL_ 863 StewSwtchPrimPosY_D_St 0 "NoTouch" 1 "Loc_1" 2 "Loc_2" 3 "Loc_3" 4 "Loc_4" 5 "Loc_5" 6 "Loc_6" 7 "Loc_7" 8 "Loc_8" 9 "Loc_9" 10 "Loc_10" 11 "Loc_11" 12 "Loc_12" 13 "Loc_13" 14 "Loc_14" 15 "Loc_15" 16 "Loc_16" 17 "Loc_17" 18 "Loc_18" 19 "Loc_19" 20 "Loc_20" 21 "Loc_21" 22 "Loc_22" 23 "Loc_23" 24 "Loc_24" 25 "Loc_25" 26 "Loc_26" 27 "Loc_27" 28 "Loc_28" 29 "Loc_29" 30 "Loc_30" 31 "Loc_31" 32 "Loc_32" 33 "Loc_33" 34 "Loc_34" 35 "Loc_35" 36 "Loc_36" 37 "Loc_37" 38 "Loc_38" 39 "Loc_39" 40 "Loc_40" 41 "Loc_41" 42 "Loc_42" 43 "Loc_43" 44 "Loc_44" 45 "Loc_45" 46 "Loc_46" 47 "Loc_47" 48 "Loc_48" 49 "Loc_49" 50 "Loc_50" 51 "Loc_51" 52 "Loc_52" 53 "Loc_53" 54 "Loc_54" 55 "Loc_55" 56 "Loc_56" 57 "Loc_57" 58 "Loc_58" 59 "Loc_59" 60 "Loc_60" 61 "Loc_61" 62 "Loc_62" 63 "Loc_63" 64 "Loc_64" 65 "Loc_65" 66 "Loc_66" 67 "Loc_67" 68 "Loc_68" 69 "Loc_69" 70 "Loc_70" 71 "Loc_71" 72 "Loc_72" 73 "Loc_73" 74 "Loc_74" 75 "Loc_75" 76 "Loc_76" 77 "Loc_77" 78 "Loc_78" 79 "Loc_79" 80 "Loc_80" 81 "Loc_81" 82 "Loc_82" 83 "Loc_83" 84 "Loc_84" 85 "Loc_85" 86 "Loc_86" 87 "Loc_87" 88 "Loc_88" 89 "Loc_89" 90 "Loc_90" 91 "Loc_91" 92 "Loc_92" 93 "Loc_93" 94 "Loc_94" 95 "Loc_95" 96 "Loc_96" 97 "Loc_97" 98 "Loc_98" 99 "Loc_99" 100 "Loc_100" 101 "Loc_101" 102 "Loc_102" 103 "Loc_103" 104 "Loc_104" 105 "Loc_105" 106 "Loc_106" 107 "Loc_107" 108 "Loc_108" 109 "Loc_109" 110 "Loc_110" 111 "Loc_111" 112 "Loc_112" 113 "Loc_113" 114 "Loc_114" 115 "Loc_115" 116 "Loc_116" 117 "Loc_117" 118 "Loc_118" 119 "Loc_119" 120 "Loc_120" 121 "Loc_121" 122 "Loc_122" 123 "Loc_123" 124 "Loc_124" 125 "Loc_125" 126 "Loc_126" 127 "Loc_127" 128 "Loc_128" 129 "Loc_129" 130 "Loc_130" 131 "Loc_131" 132 "Loc_132" 133 "Loc_133" 134 "Loc_134" 135 "Loc_135" 136 "Loc_136" 137 "Loc_137" 138 "Loc_138" 139 "Loc_139" 140 "Loc_140" 141 "Loc_141" 142 "Loc_142" 143 "Loc_143" 144 "Loc_144" 145 "Loc_145" 146 "Loc_146" 147 "Loc_147" 148 "Loc_148" 149 "Loc_149" 150 "Loc_150" 151 "Loc_151" 152 "Loc_152" 153 "Loc_153" 154 "Loc_154" 155 "Loc_155" 156 "Loc_156" 157 "Loc_157" 158 "Loc_158" 159 "Loc_159" 160 "Loc_160" 161 "Loc_161" 162 "Loc_162" 163 "Loc_163" 164 "Loc_164" 165 "Loc_165" 166 "Loc_166" 167 "Loc_167" 168 "Loc_168" 169 "Loc_169" 170 "Loc_170" 171 "Loc_171" 172 "Loc_172" 173 "Loc_173" 174 "Loc_174" 175 "Loc_175" 176 "Loc_176" 177 "Loc_177" 178 "Loc_178" 179 "Loc_179" 180 "Loc_180" 181 "Loc_181" 182 "Loc_182" 183 "Loc_183" 184 "Loc_184" 185 "Loc_185" 186 "Loc_186" 187 "Loc_187" 188 "Loc_188" 189 "Loc_189" 190 "Loc_190" 191 "Loc_191" 192 "Loc_192" 193 "Loc_193" 194 "Loc_194" 195 "Loc_195" 196 "Loc_196" 197 "Loc_197" 198 "Loc_198" 199 "Loc_199" 200 "Loc_200" 201 "Loc_201" 202 "Loc_202" 203 "Loc_203" 204 "Loc_204" 205 "Loc_205" 206 "Loc_206" 207 "Loc_207" 208 "Loc_208" 209 "Loc_209" 210 "Loc_210" 211 "Loc_211" 212 "Loc_212" 213 "Loc_213" 214 "Loc_214" 215 "Loc_215" 216 "Loc_216" 217 "Loc_217" 218 "Loc_218" 219 "Loc_219" 220 "Loc_220" 221 "Loc_221" 222 "Loc_222" 223 "Loc_223" 224 "Loc_224" 225 "Loc_225" 226 "Loc_226" 227 "Loc_227" 228 "Loc_228" 229 "Loc_229" 230 "Loc_230" 231 "Loc_231" 232 "Loc_232" 233 "Loc_233" 234 "Loc_234" 235 "Loc_235" 236 "Loc_236" 237 "Loc_237" 238 "Loc_238" 239 "Loc_239" 240 "Loc_240" 241 "Loc_241" 242 "Loc_242" 243 "Loc_243" 244 "Loc_244" 245 "Loc_245" 246 "Loc_246" 247 "Loc_247" 248 "Loc_248" 249 "Loc_249" 250 "Loc_250" 251 "Loc_251" 252 "Loc_252" 253 "NotUsed_1" 254 "NotUsed_2" 255 "Faulty" ;
VAL_ 863 StewSwtchScndPosX_D_St 0 "NoTouch" 1 "Loc_1" 2 "Loc_2" 3 "Loc_3" 4 "Loc_4" 5 "Loc_5" 6 "Loc_6" 7 "Loc_7" 8 "Loc_8" 9 "Loc_9" 10 "Loc_10" 11 "Loc_11" 12 "Loc_12" 13 "Loc_13" 14 "Loc_14" 15 "Loc_15" 16 "Loc_16" 17 "Loc_17" 18 "Loc_18" 19 "Loc_19" 20 "Loc_20" 21 "Loc_21" 22 "Loc_22" 23 "Loc_23" 24 "Loc_24" 25 "Loc_25" 26 "Loc_26" 27 "Loc_27" 28 "Loc_28" 29 "Loc_29" 30 "Loc_30" 31 "Loc_31" 32 "Loc_32" 33 "Loc_33" 34 "Loc_34" 35 "Loc_35" 36 "Loc_36" 37 "Loc_37" 38 "Loc_38" 39 "Loc_39" 40 "Loc_40" 41 "Loc_41" 42 "Loc_42" 43 "Loc_43" 44 "Loc_44" 45 "Loc_45" 46 "Loc_46" 47 "Loc_47" 48 "Loc_48" 49 "Loc_49" 50 "Loc_50" 51 "Loc_51" 52 "Loc_52" 53 "Loc_53" 54 "Loc_54" 55 "Loc_55" 56 "Loc_56" 57 "Loc_57" 58 "Loc_58" 59 "Loc_59" 60 "Loc_60" 61 "Loc_61" 62 "Loc_62" 63 "Loc_63" 64 "Loc_64" 65 "Loc_65" 66 "Loc_66" 67 "Loc_67" 68 "Loc_68" 69 "Loc_69" 70 "Loc_70" 71 "Loc_71" 72 "Loc_72" 73 "Loc_73" 74 "Loc_74" 75 "Loc_75" 76 "Loc_76" 77 "Loc_77" 78 "Loc_78" 79 "Loc_79" 80 "Loc_80" 81 "Loc_81" 82 "Loc_82" 83 "Loc_83" 84 "Loc_84" 85 "Loc_85" 86 "Loc_86" 87 "Loc_87" 88 "Loc_88" 89 "Loc_89" 90 "Loc_90" 91 "Loc_91" 92 "Loc_92" 93 "Loc_93" 94 "Loc_94" 95 "Loc_95" 96 "Loc_96" 97 "Loc_97" 98 "Loc_98" 99 "Loc_99" 100 "Loc_100" 101 "Loc_101" 102 "Loc_102" 103 "Loc_103" 104 "Loc_104" 105 "Loc_105" 106 "Loc_106" 107 "Loc_107" 108 "Loc_108" 109 "Loc_109" 110 "Loc_110" 111 "Loc_111" 112 "Loc_112" 113 "Loc_113" 114 "Loc_114" 115 "Loc_115" 116 "Loc_116" 117 "Loc_117" 118 "Loc_118" 119 "Loc_119" 120 "Loc_120" 121 "Loc_121" 122 "Loc_122" 123 "Loc_123" 124 "Loc_124" 125 "Loc_125" 126 "Loc_126" 127 "Loc_127" 128 "Loc_128" 129 "Loc_129" 130 "Loc_130" 131 "Loc_131" 132 "Loc_132" 133 "Loc_133" 134 "Loc_134" 135 "Loc_135" 136 "Loc_136" 137 "Loc_137" 138 "Loc_138" 139 "Loc_139" 140 "Loc_140" 141 "Loc_141" 142 "Loc_142" 143 "Loc_143" 144 "Loc_144" 145 "Loc_145" 146 "Loc_146" 147 "Loc_147" 148 "Loc_148" 149 "Loc_149" 150 "Loc_150" 151 "Loc_151" 152 "Loc_152" 153 "Loc_153" 154 "Loc_154" 155 "Loc_155" 156 "Loc_156" 157 "Loc_157" 158 "Loc_158" 159 "Loc_159" 160 "Loc_160" 161 "Loc_161" 162 "Loc_162" 163 "Loc_163" 164 "Loc_164" 165 "Loc_165" 166 "Loc_166" 167 "Loc_167" 168 "Loc_168" 169 "Loc_169" 170 "Loc_170" 171 "Loc_171" 172 "Loc_172" 173 "Loc_173" 174 "Loc_174" 175 "Loc_175" 176 "Loc_176" 177 "Loc_177" 178 "Loc_178" 179 "Loc_179" 180 "Loc_180" 181 "Loc_181" 182 "Loc_182" 183 "Loc_183" 184 "Loc_184" 185 "Loc_185" 186 "Loc_186" 187 "Loc_187" 188 "Loc_188" 189 "Loc_189" 190 "Loc_190" 191 "Loc_191" 192 "Loc_192" 193 "Loc_193" 194 "Loc_194" 195 "Loc_195" 196 "Loc_196" 197 "Loc_197" 198 "Loc_198" 199 "Loc_199" 200 "Loc_200" 201 "Loc_201" 202 "Loc_202" 203 "Loc_203" 204 "Loc_204" 205 "Loc_205" 206 "Loc_206" 207 "Loc_207" 208 "Loc_208" 209 "Loc_209" 210 "Loc_210" 211 "Loc_211" 212 "Loc_212" 213 "Loc_213" 214 "Loc_214" 215 "Loc_215" 216 "Loc_216" 217 "Loc_217" 218 "Loc_218" 219 "Loc_219" 220 "Loc_220" 221 "Loc_221" 222 "Loc_222" 223 "Loc_223" 224 "Loc_224" 225 "Loc_225" 226 "Loc_226" 227 "Loc_227" 228 "Loc_228" 229 "Loc_229" 230 "Loc_230" 231 "Loc_231" 232 "Loc_232" 233 "Loc_233" 234 "Loc_234" 235 "Loc_235" 236 "Loc_236" 237 "Loc_237" 238 "Loc_238" 239 "Loc_239" 240 "Loc_240" 241 "Loc_241" 242 "Loc_242" 243 "Loc_243" 244 "Loc_244" 245 "Loc_245" 246 "Loc_246" 247 "Loc_247" 248 "Loc_248" 249 "Loc_249" 250 "Loc_250" 251 "Loc_251" 252 "Loc_252" 253 "NotUsed_1" 254 "NotUsed_2" 255 "Faulty" ;
VAL_ 863 StewSwtchScndPosY_D_St 0 "NoTouch" 1 "Loc_1" 2 "Loc_2" 3 "Loc_3" 4 "Loc_4" 5 "Loc_5" 6 "Loc_6" 7 "Loc_7" 8 "Loc_8" 9 "Loc_9" 10 "Loc_10" 11 "Loc_11" 12 "Loc_12" 13 "Loc_13" 14 "Loc_14" 15 "Loc_15" 16 "Loc_16" 17 "Loc_17" 18 "Loc_18" 19 "Loc_19" 20 "Loc_20" 21 "Loc_21" 22 "Loc_22" 23 "Loc_23" 24 "Loc_24" 25 "Loc_25" 26 "Loc_26" 27 "Loc_27" 28 "Loc_28" 29 "Loc_29" 30 "Loc_30" 31 "Loc_31" 32 "Loc_32" 33 "Loc_33" 34 "Loc_34" 35 "Loc_35" 36 "Loc_36" 37 "Loc_37" 38 "Loc_38" 39 "Loc_39" 40 "Loc_40" 41 "Loc_41" 42 "Loc_42" 43 "Loc_43" 44 "Loc_44" 45 "Loc_45" 46 "Loc_46" 47 "Loc_47" 48 "Loc_48" 49 "Loc_49" 50 "Loc_50" 51 "Loc_51" 52 "Loc_52" 53 "Loc_53" 54 "Loc_54" 55 "Loc_55" 56 "Loc_56" 57 "Loc_57" 58 "Loc_58" 59 "Loc_59" 60 "Loc_60" 61 "Loc_61" 62 "Loc_62" 63 "Loc_63" 64 "Loc_64" 65 "Loc_65" 66 "Loc_66" 67 "Loc_67" 68 "Loc_68" 69 "Loc_69" 70 "Loc_70" 71 "Loc_71" 72 "Loc_72" 73 "Loc_73" 74 "Loc_74" 75 "Loc_75" 76 "Loc_76" 77 "Loc_77" 78 "Loc_78" 79 "Loc_79" 80 "Loc_80" 81 "Loc_81" 82 "Loc_82" 83 "Loc_83" 84 "Loc_84" 85 "Loc_85" 86 "Loc_86" 87 "Loc_87" 88 "Loc_88" 89 "Loc_89" 90 "Loc_90" 91 "Loc_91" 92 "Loc_92" 93 "Loc_93" 94 "Loc_94" 95 "Loc_95" 96 "Loc_96" 97 "Loc_97" 98 "Loc_98" 99 "Loc_99" 100 "Loc_100" 101 "Loc_101" 102 "Loc_102" 103 "Loc_103" 104 "Loc_104" 105 "Loc_105" 106 "Loc_106" 107 "Loc_107" 108 "Loc_108" 109 "Loc_109" 110 "Loc_110" 111 "Loc_111" 112 "Loc_112" 113 "Loc_113" 114 "Loc_114" 115 "Loc_115" 116 "Loc_116" 117 "Loc_117" 118 "Loc_118" 119 "Loc_119" 120 "Loc_120" 121 "Loc_121" 122 "Loc_122" 123 "Loc_123" 124 "Loc_124" 125 "Loc_125" 126 "Loc_126" 127 "Loc_127" 128 "Loc_128" 129 "Loc_129" 130 "Loc_130" 131 "Loc_131" 132 "Loc_132" 133 "Loc_133" 134 "Loc_134" 135 "Loc_135" 136 "Loc_136" 137 "Loc_137" 138 "Loc_138" 139 "Loc_139" 140 "Loc_140" 141 "Loc_141" 142 "Loc_142" 143 "Loc_143" 144 "Loc_144" 145 "Loc_145" 146 "Loc_146" 147 "Loc_147" 148 "Loc_148" 149 "Loc_149" 150 "Loc_150" 151 "Loc_151" 152 "Loc_152" 153 "Loc_153" 154 "Loc_154" 155 "Loc_155" 156 "Loc_156" 157 "Loc_157" 158 "Loc_158" 159 "Loc_159" 160 "Loc_160" 161 "Loc_161" 162 "Loc_162" 163 "Loc_163" 164 "Loc_164" 165 "Loc_165" 166 "Loc_166" 167 "Loc_167" 168 "Loc_168" 169 "Loc_169" 170 "Loc_170" 171 "Loc_171" 172 "Loc_172" 173 "Loc_173" 174 "Loc_174" 175 "Loc_175" 176 "Loc_176" 177 "Loc_177" 178 "Loc_178" 179 "Loc_179" 180 "Loc_180" 181 "Loc_181" 182 "Loc_182" 183 "Loc_183" 184 "Loc_184" 185 "Loc_185" 186 "Loc_186" 187 "Loc_187" 188 "Loc_188" 189 "Loc_189" 190 "Loc_190" 191 "Loc_191" 192 "Loc_192" 193 "Loc_193" 194 "Loc_194" 195 "Loc_195" 196 "Loc_196" 197 "Loc_197" 198 "Loc_198" 199 "Loc_199" 200 "Loc_200" 201 "Loc_201" 202 "Loc_202" 203 "Loc_203" 204 "Loc_204" 205 "Loc_205" 206 "Loc_206" 207 "Loc_207" 208 "Loc_208" 209 "Loc_209" 210 "Loc_210" 211 "Loc_211" 212 "Loc_212" 213 "Loc_213" 214 "Loc_214" 215 "Loc_215" 216 "Loc_216" 217 "Loc_217" 218 "Loc_218" 219 "Loc_219" 220 "Loc_220" 221 "Loc_221" 222 "Loc_222" 223 "Loc_223" 224 "Loc_224" 225 "Loc_225" 226 "Loc_226" 227 "Loc_227" 228 "Loc_228" 229 "Loc_229" 230 "Loc_230" 231 "Loc_231" 232 "Loc_232" 233 "Loc_233" 234 "Loc_234" 235 "Loc_235" 236 "Loc_236" 237 "Loc_237" 238 "Loc_238" 239 "Loc_239" 240 "Loc_240" 241 "Loc_241" 242 "Loc_242" 243 "Loc_243" 244 "Loc_244" 245 "Loc_245" 246 "Loc_246" 247 "Loc_247" 248 "Loc_248" 249 "Loc_249" 250 "Loc_250" 251 "Loc_251" 252 "Loc_252" 253 "NotUsed_1" 254 "NotUsed_2" 255 "Faulty" ;
VAL_ 864 Dual_Button_Stt 0 "Enabled_Inactive" 1 "Active" 2 "Disabled" 3 "Unused" ;
VAL_ 864 Defrost_Btn_Stt 0 "Enabled_Inactive" 1 "Active" 2 "Disabled" 3 "Unused" ;
VAL_ 864 Auto_Recirc_Btn_Stt 0 "Enabled_Inactive" 1 "Active" 2 "Disabled" 3 "Unused" ;
VAL_ 864 AC_Btn_Stt 0 "Enabled_Inactive" 1 "Active" 2 "Disabled" 3 "Unused" ;
VAL_ 864 LHS_Cond_Seat_Status 0 "Off" 1 "Level_1_Cooling" 2 "Level_2_Cooling" 3 "Level_3_Cooling" 4 "Level_1_Heating" 5 "Level_2_Heating" 6 "Level_3_Heating" 7 "Unused" ;
VAL_ 864 CC_Fr_Btn_User_Adj 0 "None" 1 "Save_MyTemp_Selection" 2 "Use_MyTemp_Selection" 3 "Fr_Auto_Selection" 4 "AC_Selection" 5 "Recirc_Selection" 6 "Fr_Power_Selection" 7 "Max_AC_Selection" 8 "Fr_Air_Dist_Selection" 9 "Defrost_Selection" 10 "Max_Defrost_Selection" 11 "Rear_Defrost_Selection" 12 "Dual_Selection" 13 "HSW_Selection" 14 "LHS_Htd_St_Selection" 15 "RHS_Htd_St_Selection" 16 "Htd_WS_Selection" 17 "UFC_Active" 18 "UFC_Complete" 19 "UFC_Interrupted" 20 "LHS_Cld_St_Selection" 21 "RHS_Cld_St_Selection" 22 "Unused6" 23 "Unused7" 24 "Unused8" 25 "Unused9" 26 "Unused10" 27 "Unused11" 28 "Unused12" 29 "Unused13" 30 "Unused14" 31 "Unused15" ;
VAL_ 864 Front_Power_Btn_Stt 0 "Enabled_Inactive" 1 "Active" 2 "Disabled" 3 "Unused" ;
VAL_ 864 Front_AUTO_Label 0 "Off" 1 "Blower" 2 "Mode" 3 "Full" ;
VAL_ 864 Front_AUTO_Btn_Stt 0 "Enabled_Inactive" 1 "Active" 2 "Disabled" 3 "Unused" ;
VAL_ 864 Floor_Btn_Stt 0 "Enabled_Inactive" 1 "Active" 2 "Disabled" 3 "Unused" ;
VAL_ 864 LHS_Cld_Seat_Btn_Stt 0 "Enabled_Inactive" 1 "Active" 2 "Disabled" 3 "Unused" ;
VAL_ 864 Htd_Strg_Whl_Status 0 "Off" 1 "Level_1_Heating" 2 "Level_2_Heating" 3 "Level_3_Heating" ;
VAL_ 864 Htd_Strg_Whl_Btn_Stt 0 "Enabled_Inactive" 1 "Active" 2 "Disabled" 3 "Unused" ;
VAL_ 864 Htd_Frt_Wsh_Btn_Stt 0 "Enabled_Inactive" 1 "Active" 2 "Disabled" 3 "Unused" ;
VAL_ 864 My_Temp_Btn_Stt 0 "Enabled_Inactive" 1 "Active" 2 "Disabled" 3 "Unused" ;
VAL_ 864 Max_Defrost_Btn_Stt 0 "Enabled_Inactive" 1 "Active" 2 "Disabled" 3 "Unused" ;
VAL_ 864 Max_AC_Btn_Stt 0 "Enabled_Inactive" 1 "Active" 2 "Disabled" 3 "Unused" ;
VAL_ 864 LHS_Htd_Seat_Btn_Stt 0 "Enabled_Inactive" 1 "Active" 2 "Disabled" 3 "Unused" ;
VAL_ 864 Recirc_Btn_Stt 0 "Enabled_Inactive" 1 "Active" 2 "Disabled" 3 "Unused" ;
VAL_ 864 Rear_Defrost_Btn_Stt 0 "Enabled_Inactive" 1 "Active" 2 "Disabled" 3 "Unused" ;
VAL_ 864 Panel_Btn_Stt 0 "Enabled_Inactive" 1 "Active" 2 "Disabled" 3 "Unused" ;
VAL_ 864 Outside_Btn_Stt 0 "Enabled_Inactive" 1 "Active" 2 "Disabled" 3 "Unused" ;
VAL_ 864 RearMnu_Buttn_Stat 0 "Not_Pressed" 1 "Pressed" ;
VAL_ 864 FrontMnu_Buttn_Stat 0 "Not_Pressed" 1 "Pressed" ;
VAL_ 864 Windscreen_Btn_Stt 0 "Enabled_Inactive" 1 "Active" 2 "Disabled" 3 "Unused" ;
VAL_ 864 RHS_Htd_Seat_Btn_Stt 0 "Enabled_Inactive" 1 "Active" 2 "Disabled" 3 "Unused" ;
VAL_ 864 RHS_Cld_Seat_Btn_Stt 0 "Enabled_Inactive" 1 "Active" 2 "Disabled" 3 "Unused" ;
VAL_ 864 DrvrFcsdMde_Btn_Stt 0 "Enabled_Inactive" 1 "Active" 2 "Disabled" 3 "Unused" ;
VAL_ 864 MdeMnu_Buttn_Stat 0 "Not_Pressed" 1 "Pressed" ;
VAL_ 864 Front_AUTO_Blwr_Lvl 0 "Off" 1 "Low" 2 "Medium" 3 "High" ;
VAL_ 864 RHS_Cond_Seat_Status 0 "Off" 1 "Level_1_Cooling" 2 "Level_2_Cooling" 3 "Level_3_Cooling" 4 "Level_1_Heating" 5 "Level_2_Heating" 6 "Level_3_Heating" 7 "Unused" ;
VAL_ 865 EATC_LHS_Units 0 "Off" 1 "Celsius" 2 "Fahrenheit" ;
VAL_ 865 RHS_Temp_Display_Digit3 0 "OFF" 1 "0" 2 "5" ;
VAL_ 865 CC_Fr_Stat_User_Adj 0 "None" 1 "FLHS_SetPt_Selection" 2 "FRHS_SetPt_Selection" 3 "Fr_Blwr_Spd_Selection" 4 "DrvrFcsdMde_Selection" 5 "LHS_AUTO_St_Selection" 6 "RHS_AUTO_St_Selection" 7 "Unused4" ;
VAL_ 865 LHS_Temp_Display_Digit3 0 "OFF" 1 "0" 2 "5" ;
VAL_ 865 Front_Blower_Indicate 0 "Indicators_Off" 1 "1_Indicator_On" 2 "2_Indicators_On" 3 "3_Indicators_On" 4 "4_Indicators_On" 5 "5_Indicators_On" 6 "6_Indicators_On" 7 "7_Indicators_On" 8 "8_Indicators_On" 9 "9_Indicators_On" 10 "10_Indicators_On" 11 "11_Indicators_On" 12 "12_Indicators_On" 13 "13_Indicators_On" 14 "14_Indicators_On" 15 "Display_Blank" ;
VAL_ 865 EATC_RHS_Units 0 "Off" 1 "Celsius" 2 "Fahrenheit" ;
VAL_ 865 SelDrvMdeSwtch_D_Stat2 0 "NotPressed" 1 "SwitchState1" 2 "SwitchState2" 3 "Faulty" ;
VAL_ 865 EngExhMdeQuiet_B_RqDrv 0 "Not_Pressed" 1 "Pressed" ;
VAL_ 865 LnchCtlSys_B_RqDrv 0 "Not_Pressed" 1 "Pressed" ;
VAL_ 865 SteEffortButtn_B_Stat 0 "Not_Pressed" 1 "Pressed" ;
VAL_ 865 SelDrvMdeButtn_B_Stat 0 "Not_Pressed" 1 "Pressed" ;
VAL_ 865 RHS_Auto_Seat_Btn_Stt 0 "Enabled_Inactive" 1 "Active" 2 "Disabled" 3 "Unused" ;
VAL_ 865 LHS_Auto_Seat_Btn_Stt 0 "Enabled_Inactive" 1 "Active" 2 "Disabled" 3 "Unused" ;
VAL_ 865 Dsp_RotAddrBtnEv_St 0 "Neg_7Steps" 1 "Neg_6Steps" 2 "Neg_5Steps" 3 "Neg_4Steps" 4 "Neg_3Steps" 5 "Neg_2Steps" 6 "Neg_1Steps" 7 "NotPressed" 8 "Pos_1Step" 9 "Pos_2Steps" 10 "Pos_3Steps" 11 "Pos_4Steps" 12 "Pos_5Steps" 13 "Pos_6Steps" 14 "Pos_7Steps" 15 "NotUsed_1" ;
